VERSION "0.0.1"

NS_ :

BS_:

BU_: TCU BRK ESP MCU RDD GP TMS GW KPD1 RDE FNR ECU KPD2 ATSGO ACU IMU1 IMU2 IMU3 IMU4 IMU5 AGW PMI HDOQS EGOQS OBC EEC CBSW EJRH EJLH EPDLT EPDL2 EPDLR EPDLA TRBDZ ECU1 CLST LC510 EGDL JS SMB KPAC ACCU Audio TGU RDRR RDLH RDRH AVM CHMSL CTC SMK MC3D EVC MCU2
VAL_TABLE_ Bool 3 "N/A" 2 "Error" 1 "True" 0 "False" ;
VAL_TABLE_ PwrDnCmd 3 "N/A" 2 "Emergency Power-Down" 1 "Normal Power-Down" 0 "Not request" ;
VAL_TABLE_ OffOn 3 "N/A" 2 "Error" 1 "On" 0 "Off" ;
VAL_TABLE_ NoneOffOn 3 "N/A" 2 "On" 1 "Off" 0 "None" ;
VAL_TABLE_ MachineStatus 3 "N/A" 2 "Key off charging" 1 "Key on" 0 "Key off" ;
VAL_TABLE_ ChargingStatus 5 "EVSE Signal Warning" 4 "AC Voltage Below Normal" 3 "AC Voltage Above Normal" 2 "Charging Gun Warning" 1 "Charging Port Warning" 0 "Charging" ;
VAL_TABLE_ WrnLamp 3 "Slow Blinking" 2 "Blinking" 1 "On" 0 "Off" ;
VAL_TABLE_ WrnLampTxt 15 "Slow Blinking text4" 14 "Blinking text4" 13 "On text4" 12 "N/A" 11 "Slow Blinking text2" 10 "Blinking text2" 9 "On text2" 8 "N/A" 7 "Slow Blinking text3" 6 "Blinking text3" 5 "On text3" 4 "N/A" 3 "Slow Blinking text1" 2 "Blinking text1" 1 "On text1" 0 "Off" ;
VAL_TABLE_ AntDetect 2 "Shorted" 1 "Removal" 0 "Normal" ;
VAL_TABLE_ TrvModeCr 3 "N/A" 2 "Auto Speed" 1 "High Speed" 0 "Low Speed" ;
VAL_TABLE_ WrkMode 3 "Reserved" 2 "Two Way" 1 "Breaker" 0 "Not Defined" ;
VAL_TABLE_ TwoWayOpt 3 "Not Defined" 2 "Option Pedal" 1 "Joystick Thumb Wheel" 0 "N/A" ;
VAL_TABLE_ GpsSt 3 "3D" 2 "2D" 1 "No Fix" 0 "Unknown" ;
VAL_TABLE_ SmkFobReg 3 "Fail2" 2 "Fail1" 1 "Success" 0 "Normal" ;
VAL_TABLE_ SmkFobDet 1 "Detect Request" 0 "Default" ;
VAL_TABLE_ SmkFobIdReq 1 "Request" 0 "Default" ;
VAL_TABLE_ CmdOnOff 3 "N/A" 2 "Off" 1 "On" 0 "No Action" ;
VAL_TABLE_ EgStartCmd 3 "Key On" 2 "Engine Off" 1 "Engine On" 0 "No Action" ;
VAL_TABLE_ ColdStart 8 "Test of Grid Heater Voltage" 7 "Normal Blinking" 6 "Slow Blinking" 5 "Fault while Pre-Heating" 4 "Parking Brake for Pre-Heating" 3 "No Foot on the Pdedal for Pre-Heating" 2 "Gear Neutral for Pre-Heating" 1 "Trsm Pre-Heating" 0 "OFF" ;
VAL_TABLE_ FuelBlock 1 "Fuel Blocked" 0 "Fuel Released" ;
VAL_TABLE_ LampSt 3 "N/A" 2 "Blinking" 1 "On" 0 "Off" ;
VAL_TABLE_ WrnHigh 3 "Not Available" 2 "Reserved" 1 "Above Operation Range" 0 "Normal" ;
VAL_TABLE_ LampBitSt 4 "Blinking" 1 "On" 0 "Off" ;
VAL_TABLE_ WrnLow 3 "Not Available" 2 "Reserved" 1 "Below Operation Range" 0 "Normal" ;
VAL_TABLE_ Wrn 3 "Not Available" 2 "Reserved" 1 "Warning" 0 "Normal" ;
VAL_TABLE_ EdcOprSt 2 "Diagnostic Test" 1 "Afterrun Drive" 0 "Normal Operation" ;
VAL_TABLE_ PtoSt 31 "N/A" 19 "PTO set speed memory 2" 18 "PTO set speed memory 1" 17 "Preprogrammed set speed 8" 16 "Preprogrammed set speed 7" 15 "Preprogrammed set speed 6" 14 "Preprogrammed set speed 5" 13 "Preprogrammed set speed 4" 12 "Preprogrammed set speed 3" 11 "Preprogrammed set speed 2" 10 "Preprogrammed set speed 1" 9 "Accelerator Override" 8 "Accelerate" 7 "Resume" 6 "Decelerate/Coast" 5 "Set" 4 "Remote Standby" 3 "Standby" 2 "Remote Hold" 1 "Hold" 0 "Off/Disabled" ;
VAL_TABLE_ DpfActRegenSt 3 "N/A" 2 "Regeneration needed" 1 "Active" 0 "Not active" ;
VAL_TABLE_ DpfActRegenIhbSw 3 "N/A" 1 "Inhibited" 0 "Not inhibited" ;
VAL_TABLE_ AtDefPpt 15 "N/A" 14 "Error" 13 "Not able to determine" 3 "Diesel exhaust fluid is proper mixture" 2 "Fluid is diesel" 1 "Urea concentration too low" 0 "Urea concentration too high" ;
VAL_TABLE_ AtSelCatalRedOprIndAct 7 "N/A" 4 "Blinking" 1 "On" 0 "Off" ;
VAL_TABLE_ AtGasSsHtCont 3 "Heater off" 2 "Preheat 1" 1 "Preheat 2" 0 "Automatic" ;
VAL_TABLE_ EgOvrContMd 3 "Speed/torque limit control" 2 "Torque control" 1 "Speed control" 0 "Override disabled" ;
VAL_TABLE_ PRI 3 "Low" 2 "Medium" 1 "High" 0 "Highest" ;
VAL_TABLE_ TractionCont 4 "Auto" 3 "High" 2 "Medium" 1 "Low" 0 "Off" ;
VAL_TABLE_ PowMd 3 "N/A" 2 "PWR" 1 "STD" 0 "ECO" ;
VAL_TABLE_ MaxSpd 5 "Speed 5" 4 "Speed 4" 3 "Speed 3" 2 "Speed 2" 1 "Speed 1" 0 "Neutral" ;
VAL_TABLE_ RpmReqMd 3 "None" 1 "Limphome" 0 "Autoidle" ;
VAL_TABLE_ NFR 3 "TCU requires N position" 2 "Position_R" 1 "Position_F" 0 "Position_N" ;
VAL_TABLE_ FNR 3 "N/A" 2 "R" 1 "N" 0 "F" ;
VAL_TABLE_ GrSt 7 "Limp Home" 6 "Gear 6" 5 "Gear 5" 4 "Gear 4" 3 "Gear 3" 2 "Gear 2" 1 "Gear 1" 0 "Neutral" ;
VAL_TABLE_ OpMd 6 "TCU Idle" 5 "TCU Key Off" 4 "TCU_Shutdown" 3 "Transmission_Shutdown" 2 "Limp_Home" 1 "Substitute_Clutch_Control" 0 "Normal" ;
VAL_TABLE_ MchKeyOnSt 3 "Not defined" 2 "Key off charging" 1 "Key on" 0 "Key off" ;
VAL_TABLE_ ChrgSt 5 "EVSE Signal Warning" 4 "AC Voltage Below Normal" 3 "AC Voltage Above Normal" 2 "Charging Gun Warning" 1 "Charging Port Warning" 0 "Charging" ;
VAL_TABLE_ TrvMdCrw 3 "N/A" 2 "Auto Speed" 1 "High Speed" 0 "Low Speed" ;
VAL_TABLE_ IsoBhl 2 "BHL" 1 "ISO" 0 "OFF" ;
VAL_TABLE_ TrvMdWhl 3 "Not Defined" 2 "3" 1 "2" 0 "True" ;
VAL_TABLE_ HhMntLgc 3 ">4000m" 2 "<=4000m" 1 "<=3000m" 0 "OFF" ;
VAL_TABLE_ BrakerAct 3 "N/A" 2 "Forced Stop" 1 "Running" 0 "Stop" ;
VAL_TABLE_ FaultCnt 3 "N/A" 2 "FaultOc2" 1 "FaultOc1" 0 "None" ;
VAL_TABLE_ TrvMdWld 3 "Not Defined" 2 "Auto Speed 2" 1 "Auto Speed 1" 0 "Manual" ;
VAL_TABLE_ HstMdWld 3 "Not Defined" 2 "Slip" 1 "Auto" 0 "Max" ;
VAL_TABLE_ OprPowMd 4 "Power+" 3 "AutoIdle" 2 "Economy" 1 "Standard" 0 "Power" ;
VAL_TABLE_ OprMd 1 "Digging" 0 "Normal" ;
VAL_TABLE_ WhlDrvMd 3 "AlignComplete" 2 "RearAlignReq" 1 "FrontAlignReq" 0 "Off" ;
VAL_TABLE_ OffOnCnd 3 "Condition Yellow" 2 "Condition Green" 1 "On" 0 "Off" ;
VAL_TABLE_ VhcStSymb 3 "Yellow" 2 "Green" 1 "Grey" 0 "Off" ;
VAL_TABLE_ DAC 5 "Suspend auto" 4 "Interlock" 3 "Auto" 2 "Manual" 1 "Stand By" 0 "Not Ready" ;
VAL_TABLE_ Chmsl 6 "Object Sensing (Fast Flashing)" 5 "Swing Left" 4 "Swing Right" 3 "Working Status (Flashing)" 2 "Standby Working (Continuous)" 1 "Brake On" 0 "Off" ;
VAL_TABLE_ MchCond 3 "Standstill Condition" 2 "Error" 1 "Working Condition" 0 "Idle Condition" ;
VAL_TABLE_ PilotCutOffSt 3 "Not Available" 2 "Auto Lock" 1 "Manual Lock " 0 "Unlock " ;
VAL_TABLE_ BodySt 3 "Not Defined" 2 "Float" 1 "Hold" 0 "Off" ;
VAL_TABLE_ EcoSymbol 3 "White" 2 "Red" 1 "Yellow" 0 "Green" ;
VAL_TABLE_ Progress 3 "N/A" 2 "Complete" 1 "In Progress" 0 "None" ;
VAL_TABLE_ Progress2 1 "Complete" 0 "In Progress" ;
VAL_TABLE_ ManAuto 3 "N/A" 2 "Error" 1 "Auto" 0 "Manual" ;
VAL_TABLE_ AdminSet 4 "Entertainment Restrict" 2 "Attachment" 1 "Ignition Lock" 0 "None" ;
VAL_TABLE_ Uptime 3 "N/A" 2 "5 min" 1 "1 min" 0 "Always" ;
VAL_TABLE_ HydElec 1 "Electronic" 0 "Hydraulic" ;
VAL_TABLE_ JoyPdl 3 "N/A" 2 "Option Pedal" 1 "Joystick Thumb Wheel" 0 "N/A" ;
VAL_TABLE_ ThmbWhl 3 "N/A" 2 "Fast" 1 "Normal" 0 "Smooth" ;
VAL_TABLE_ MultiFunc 7 "Not Defined" 6 "Not Defined" 5 "Auto Breaker" 4 "Audio Mute" 3 "Ram Lock  Status Change" 2 "Camera View Mode Change" 1 "Smart Boom Cut" 0 "Wiper On" ;
VAL_TABLE_ EmsCtrl 128 "N/A" 5 "NR4" 4 "StageV" 3 "Tier4F" 2 "Tier4i" 1 "Tier3" 0 "Tier2" ;
VAL_TABLE_ MchGen 224 "D" 133 "G" 132 "SD" 131 "S" 130 "K" 129 "H" 128 "DL" 108 "AGK" 96 "JD" 5 "W" 4 "B" 3 "C" 2 "V" 1 "U" 0 "DX" ;
VAL_TABLE_ MchType 14 "ADT" 13 "Road Builder" 12 "Compact Track Loader" 11 "Drill Rig" 10 "Material Handler Wheel" 9 "Material Handler" 8 "Dozer" 7 "Loader" 6 "Wheel" 5 "Mountain" 4 "Zero Tail" 3 "Reduced Tail" 2 "LogLoader" 1 "Long Crawler" 0 "Crawler" ;
VAL_TABLE_ ModelYearVer 5 "5th" 4 "4th" 3 "3rd" 2 "2nd" 1 "1st" 0 "Original" ;
VAL_TABLE_ EgMaker 8 "Daedong" 7 "Yanmar" 5 "Isuzu" 4 "Perkins" 3 "Cummins" 2 "Scania" 1 "Doosan" 0 "None" ;
VAL_TABLE_ EcuMaker 12 "Perkins_2506J_Unified" 11 "Weifu" 10 "Bosch (EDC7)" 9 "Woodward" 8 "Perkins_1204J" 7 "Hitachi" 6 "Bosch (G2)" 5 "Isuzu" 4 "Perkins_2506J" 3 "Cummins" 2 "Scania" 1 "Bosch (DL06 / DL08)" 0 "None" ;
VAL_TABLE_ PmpType 4 "LS" 3 "VBO" 2 "Open Center" 1 "Posicon" 0 "Negacon" ;
VAL_TABLE_ MechElec 1 "Electric" 0 "Mechanic" ;
VAL_TABLE_ McvCtrlType 2 "FEH" 1 "VBO" 0 "Mechanic" ;
VAL_TABLE_ TcuType 3 "HDT Level1" 2 "CVT" 1 "HST" 0 "HDT" ;
VAL_TABLE_ Region 4 "US" 3 "Emerging" 2 "Advanced" 1 "China" 0 "Korea" ;
VAL_TABLE_ Btn 3 "N/A" 2 "Propotional" 1 "Toggle" 0 "Push" ;
VAL_TABLE_ Active 3 "N/A" 2 "Error" 1 "Active" 0 "Deactive" ;
VAL_TABLE_ GYR 2 "Red" 1 "Yellow" 0 "Green" ;
VAL_TABLE_ WghSt 5 "Confirm(Truck Tip-off)" 4 "Estimate(Truck tip-off)" 3 "Complete" 2 "Confirm" 1 "Estimate" 0 "Ready" ;
VAL_TABLE_ WghCntSt 3 "Not Defined" 2 "Return" 1 "Cancel" 0 "Off" ;
VAL_TABLE_ Srage 15 "Error" 14 "Success" 13 "Last Stage (Confirm)" 12 "Stage 12" 11 "Stage 11" 10 "Stage 10" 9 "Stage 9" 8 "Stage 8" 7 "Stage 7" 6 "Stage 6" 5 "Stage 5" 4 "Stage 4" 3 "Stage 3" 2 "Stage 2" 1 "Stage 1" 0 "Reserved" ;
VAL_TABLE_ GradeOffsetSw 15 "Not Available" 14 "Error" 2 "Decrement button pressed" 1 "Increment button pressed" 0 "No button pressed" ;
VAL_TABLE_ BladeAutoMd 15 "Not Available" 14 "Error" 4 "Auto Not Allowed" 3 "Service Mode" 2 "Suspend Auto" 0 "Auto Allowed" ;
VAL_TABLE_ TmsStInfo01 1 "??" 0 "????" ;
VAL_TABLE_ VwMd 15 "Not Available" 5 "Boom" 4 "3D" 3 "Top+Rear" 2 "Right" 1 "Rear" 0 "Top" ;
VAL_TABLE_ PriMd 1 "Priority Mode" 0 "Normal Mode" ;
VAL_TABLE_ FactoryType 3 "?? 4" 2 "?? 3" 1 "?? 2" 0 "?? 1" ;
VAL_TABLE_ VhcType1 1 "Crawler" 0 "Wheel" ;
VAL_TABLE_ VhcType2 3 "Not Defined" 2 "LL" 1 "LCR(???)" 0 "LC(??)" ;
VAL_TABLE_ UltsRecognitionDistanceSet 1 "???" 0 "??" ;
VAL_TABLE_ BoomCamOpt 1 "Boom Camera ??" 0 "Boom Camera ???" ;
VAL_TABLE_ OnOffSt 1 "Off" 0 "On" ;
VAL_TABLE_ Opt 1 "?? ??" 0 "?? ??" ;
VAL_TABLE_ DisEnable 1 "Enable" 0 "Disable" ;
VAL_TABLE_ ToleranceCorCmd 3 "?? ?? ??" 2 "?? ?? ??" 1 "?? ?? ?" 0 "?? ?? ?" ;
VAL_TABLE_ ToleranceCorMenuentryCmd 1 "?? ?? ?? ??" 0 "?? ?? ?? ??" ;
VAL_TABLE_ CamPrmtCorCompleteSt 0 "???" ;
VAL_TABLE_ CamPrmtcorCompleteSt 1 "?? ??" ;
VAL_TABLE_ PwrMdSt 3 "Power Mode" 2 "Power + Mode" 1 "Economy Mode" 0 "Standard Mode" ;
VAL_TABLE_ WrkMdSt 3 "Two Way" 2 "Breaker" 1 "Lift" 0 "Dig" ;
VAL_TABLE_ LockSt 1 "Lock" 0 "Unlock " ;
VAL_TABLE_ TractionMdSt 4 "Auto" 3 "C(1)" 2 "B(2)" 1 "A(3)" 0 "Max" ;
VAL_TABLE_ KeyPadPri 1 "Virtual KePad" 0 "KeyPad" ;
VAL_TABLE_ EvMdCmd 3 "N/A" 2 "N/A" 1 "EV Mode" 0 "Normal Mode" ;
VAL_TABLE_ AttType 1 "Two Way" 0 "Breaker" ;
VAL_TABLE_ AlarmSt 5 "Alarm #5" 4 "Alarm #4" 3 "Alarm #3" 2 "Alarm #2" 1 "Alarm #1" 0 "Alarm Off" ;
VAL_TABLE_ MgSoundGudStep 9 "Alarm #9" 8 "Alarm #8" 7 "Alarm #7" 6 "Alarm #6" 5 "Alarm #5" 4 "Alarm #4" 3 "Alarm #3" 2 "Alarm #2" 1 "Alarm #1" 0 "Alarm Off" ;
VAL_TABLE_ OptSetJoyPatternChange 6 "CTL H" 5 "CTL ISO" 4 "SCM" 3 "KOBE" 2 "MHI" 1 "BHL (for CTL Backhoe)" 0 "ISO (for CTL EXC)" ;
VAL_TABLE_ AudioAuxSel 3 "N/A" 2 "Error Indicator" 1 "On" 0 "Off" ;
VAL_TABLE_ ReqCallIndex 10 "10th Index" 9 "9th Index" 8 "8th Index" 7 "7th Index" 6 "6th Index" 5 "5th Index" 4 "4th Index" 3 "3rd Index" 2 "2nd Index" 1 "1st Index" 0 "None" ;
VAL_TABLE_ MainCmd 1 "CAM Button CMD" 0 "No Action CMD" ;
VAL_TABLE_ SubCmd 1 "????? ?? ?" 0 "????? ?? ??" ;
VAL_TABLE_ Dt02GpType 1 "S&T 8inch ???" 0 "S&T 7inch ???" ;
VAL_TABLE_ GspnIdentifier 1 "GSPN" 0 "SPN" ;
VAL_TABLE_ PdlCalb 2 "Max Pushed Cal CMD" 1 "Max Release Cal CMD" 0 "Calibration Ready CMD" ;
VAL_TABLE_ Joystick 3 "Not Defined" 2 "???" 1 "??" 0 "????" ;
VAL_TABLE_ NoInReq 1 "??" 0 "??" ;
VAL_TABLE_ DoorLockSt 3 "Failed" 2 "Unlock " 1 "Lock" 0 "None" ;
VAL_TABLE_ NoneOnOff 3 "Failed" 2 "Off" 1 "On" 0 "None" ;
VAL_TABLE_ VentilationTmp 15 "Failed" ;
VAL_TABLE_ FobRgstFdbk 3 "None" 2 "Detection Complete" 1 "Not Detection" 0 "Default" ;
VAL_TABLE_ FobWarn 3 "ON (Slow Blinking)" 2 "ON (Normal Blinking)" 1 "ON (No Blinking)" 0 "OFF" ;
VAL_TABLE_ KeyStChange 3 "Crank or Engine Running" 2 "Key On" 1 "ACC" 0 "Key Off" ;
VAL_TABLE_ Detect 1 "Detect" 0 "No Detect" ;
VAL_TABLE_ OpenClose 1 "Close" 0 "Open" ;
VAL_TABLE_ RmRunningSt 1 "Remote Running Status" 0 "Normal Status" ;
VAL_TABLE_ Activation 1 "Activation" 0 "No Activation" ;
VAL_TABLE_ JoyEnbsignal 3 "Not Available" 2 "Reserved" 1 "Active" 0 "Inactive" ;
VAL_TABLE_ Errorcode 15 "No Error" 14 "Reserved" 13 "Reserved" 12 "Reserved" 11 "Reserved" 10 "Reserved" 9 "Reserved" 8 "Reserved" 7 "Reserved" 6 "Reserved" 5 "Reserved" 4 "Reserved" 3 "Reserved" 2 "Reserved" 1 "Reserved" 0 "Reserved" ;
VAL_TABLE_ Drtindication 3 "Not Available" 2 "Error indicator" 1 "Reverse" 0 "Forward" ;
VAL_TABLE_ IfconfiguredasPrptA 0 "Always" ;
VAL_TABLE_ StrMdReq 1 "Operating" 0 "Not Operating" ;
VAL_TABLE_ AuxStrDeviceLckout 3 "Not Available" 2 "Reserved" 1 "AUX steering prohibited" 0 "AUX steering allowed" ;
VAL_TABLE_ AutoGudRecvSelandLckout 3 "Reserved" 2 "GPS 2 Steering selected" 1 "GPS Steering selected" 0 "No GPS receiver selected (GPS steering
prohibited)" ;
VAL_TABLE_ TrvlSpdSet 3 "Preset 4" 2 "Preset 3" 1 "Preset 2" 0 "Preset 1" ;
VAL_TABLE_ Spd 10 "Speed 5" 9 "Speed 4.5" 8 "Speed 4" 7 "Speed 3.5" 6 "Speed 3" 5 "Speed 2.5" 4 "Speed 2" 3 "Speed 1.5" 2 "Speed 1" 1 "Speed 0.5" 0 "Speed 0" ;
VAL_TABLE_ Fnr 2 "Reverse" 1 "Neutral" 0 "Forward" ;
VAL_TABLE_ CurPwrMd 3 "Not available" 2 "PWR" 1 "STD" 0 "ECO" ;
VAL_TABLE_ MnAutoMdSt 3 "Reserved" 2 "Auto" 1 "Not Available" 0 "Manual" ;
VAL_TABLE_ MdSt 3 "Reserved" 2 "Enable" 1 "Not Available" 0 "Disable" ;
VAL_TABLE_ OuttakeIntakeMdsel 3 "Reserved" 2 "Intake mode" 1 "Not Available" 0 "Outtake mode" ;
VAL_TABLE_ VhcStSybACOffInd 3 "Blink (Slow Blink)" 2 "Blink (Normal Blink)" 1 "On(No Blinking)" 0 "Off" ;
VAL_TABLE_ OutReq 3 "Not Available" 2 "Error Indicator" 1 "On" 0 "Off" ;
VAL_TABLE_ OutFdbkCur 1 "Not Available" 0 "Error indicator" ;
VAL_TABLE_ ErrorFlag 1 "Error indicator" 0 "None" ;
VAL_TABLE_ NorOpenShort 2 "Short" 1 "Open" 0 "Normal" ;
VAL_TABLE_ ResolutionMd 3 "Don't Care" 2 "Reserved" 1 "High Resolution" 0 "Standard Resolution" ;
VAL_TABLE_ VvSt 15 "N/A" 3 "Float" 2 "Retract" 1 "Extend" 0 "Block" ;
VAL_TABLE_ FailSafeMd 3 "Don't Care" 2 "Reserved" 1 "Extend" 0 "Block" ;
VAL_TABLE_ AvmLanguagePack 24 "Vietnamese" 23 "Greek" 22 "Thai" 21 " Hindi" 20 "Farsi(Persian)" 19 "Arabic(Saudi Arabia)" 18 "Russian" 17 "Polish" 16 " Indonesian" 15 "Turkish" 14 "Japanese" 13 "Danish" 12 "Norwegian(Bokmal)" 11 "Swedish" 10 "Finnish" 9 "Spanish(International)" 8 "Portuguese(Portugal)" 7 "Italian(Italy)" 6 "Dutch(Netherlands)" 5 "German(Germany)" 4 "French(France)" 3 "Chinese (PRC)" 2 "English" 1 "Korean (Default)" 0 "NotUsed" ;
VAL_TABLE_ AvmVw 5 "Boom (Option)" 4 "3D" 3 "Rear + Corner" 2 "Top + Right" 1 "Rear Wide" 0 "Topview" ;
VAL_TABLE_ AvmOutType 7 "Invalid" 6 "Error" 2 "AVM Output Type LVDS" 1 "AVM Output Type NTSC" 0 "Not Used" ;
VAL_TABLE_ AvmDisplayMsg 255 "Invalid" 254 "Error" 63 "Warning_Check_Back&Right&Left" 62 "Warning_Check_Front&Right&Left" 2 "InCameraCalibarionMode" 1 "No Message" 0 "Not Used" ;
VAL_TABLE_ AvmTonSize 15 "Invalid" 14 "Error" 5 "30T Crawler" 4 "21T Wheel" 3 "14T Wheel" 2 "5T Wheel" 1 "5T Crawler" 0 "Not Used" ;
VAL_TABLE_ AvmUltraBz 15 "Invalid" 14 "Error" 7 "Left / Right / Rear Activation" 6 "Right / Rear Activation" 5 "Left / Right Activation" 4 "Left / Rear Activation" 3 "Rear Activation" 2 "Righr Activation" 1 "Left Activation" 0 "Ultrasonic All Off" ;
VAL_TABLE_ AvmSt 31 "Invalid" 30 "Error" 3 "AVM Fail" 2 "AVM Normal (IGN On)" 1 "AVM Not Ready (IGN Off)" 0 "Not Used" ;
VAL_TABLE_ AvmWarnGud 7 "Invalid" 6 "Error" 2 "AVM Warning Guide Line On" 1 "AVM Warning Guide Line Off" 0 "Not Used" ;
VAL_TABLE_ UltsSig 15 "Invalid" 14 "Error" 5 "Noise Error" 4 "Fault" 3 "Level 3" 2 "Level 2" 1 "Level 1" 0 "Off" ;
VAL_TABLE_ Working 1 "Working" 0 "Not Working" ;
VAL_TABLE_ HtPadSt 1 "On Board Charger" 0 "Off" ;
VAL_TABLE_ ChgSt 7 "Not Available" 6 "Charger Error" 5 "Reserved" 4 "Pause" 3 "Complete" 2 "Failure" 1 "Charging" 0 "Standby" ;
VAL_TABLE_ BmsChgSourceType 3 "Not Available" 2 "Quick charger" 1 "On Board Charger" 0 "None" ;
VAL_TABLE_ ScrtyCmd 3 "Not Available" 2 "Engine Lock" 1 "RPM Limit" 0 "Normal" ;
VAL_TABLE_ GpsAntSt 3 "N/A" 2 "Shorten" 1 "Removed" 0 "Normal" ;
VAL_TABLE_ KeyType 4 "Remote" 3 "Keyless" 2 "Digital Key" 1 "Fob" 0 "None" ;
VAL_TABLE_ Type 7 "N/A" 3 "5G" 2 "4G" 1 "3G" 0 "2G" ;
VAL_TABLE_ WarnPopHyhOilQual 2 "?? 2??" 1 "?? 1??" 0 "Off" ;
VAL_TABLE_ WarnPopEgOilQual 2 "?? 2??" 1 "?? 1??" 0 "Off" ;

BO_ 3221225472 VECTOR__INDEPENDENT_SIG_MSG: 0 Vector__XXX
 SG_ GyroSnsrX : 0|16@1+ (0.0152671755725191,0) [0|1000.53435114504] "" Vector__XXX
 SG_ SwgRdctVib : 0|16@1+ (7.7E-005,0) [0|5.046195] "" Vector__XXX
 SG_ SPN : 0|19@1+ (1,0) [0|0] "" Vector__XXX
 SG_ KnmtVcstyofEgOil : 0|16@1+ (0.00778149,0) [0|500] "" Vector__XXX
 SG_ KnmtVcstyofHyhOil : 0|16@1+ (0.00778149,0) [0|500] "" Vector__XXX
 SG_ LwThKnmtVcstyofEgOil : 0|16@1+ (0.00778149,0) [0|500] "" Vector__XXX
 SG_ UpThKnmtVcstyofEgOil : 0|16@1+ (0.00778149,0) [0|500] "" Vector__XXX
 SG_ LwThDielecCstofEgOil : 0|16@1+ (0.0001220703125,0) [0|7.844] "" Vector__XXX
 SG_ UpThDielecCstofEgOil : 0|16@1+ (0.0001220703125,0) [0|7.844] "" Vector__XXX
 SG_ LwThKnmtVcstyofHyhOil : 0|16@1+ (0.00778149,0) [0|500] "" Vector__XXX
 SG_ UpThKnmtVcstyofHyhOil : 0|16@1+ (0.00778149,0) [0|500] "" Vector__XXX
 SG_ LwThDielecCstofHyhOil : 0|16@1+ (0.0001220703125,0) [0|7.844] "" Vector__XXX
 SG_ UpThDielecCstofHyhOil : 0|16@1+ (0.0001220703125,0) [0|7.844] "" Vector__XXX
 SG_ RqstdPGN : 0|24@1+ (1,0) [0|0] "" Vector__XXX
 SG_ AddressAcknowledged : 0|8@1+ (1,0) [0|0] "" Vector__XXX
 SG_ GroupFunctionValue : 0|8@1+ (1,0) [0|0] "" Vector__XXX
 SG_ ControlByte : 0|8@1+ (1,0) [0|0] "" Vector__XXX
 SG_ WarnPopHyhOilQual : 0|3@1+ (1,0) [0|7] "" Vector__XXX
 SG_ WarnPopEgOilQual : 0|3@1+ (1,0) [0|7] "" Vector__XXX
 SG_ SwVer : 0|72@1+ (1,0) [0|255] "ASCII" Vector__XXX
 SG_ KnlVer : 0|72@1+ (1,0) [0|255] "ASCII" Vector__XXX
 SG_ ProdDate : 0|72@1+ (1,0) [0|255] "ASCII" Vector__XXX
 SG_ TGUId : 0|160@1+ (1,0) [0|255] "ASCII" Vector__XXX
 SG_ TypeCd : 0|48@1+ (1,0) [0|255] "ASCII" Vector__XXX
 SG_ SwRdctFeature2ndR : 0|16@1+ (0.01,0) [0|655.35] "" Vector__XXX
 SG_ SwRdctFeature2ndL : 0|16@1+ (0.01,0) [0|655.35] "" Vector__XXX
 SG_ SwRdctFeature1stR : 0|16@1+ (0.01,0) [0|655.35] "" Vector__XXX
 SG_ SwRdctFeature1stL : 0|16@1+ (0.01,0) [0|655.35] "" Vector__XXX
 SG_ SwRdctThreshEnvTSA : 0|8@1+ (0.1,0) [0|25.5] "" Vector__XXX
 SG_ SwRdctUnitStat2ndR : 0|4@1+ (1,0) [0|15] "" Vector__XXX
 SG_ SwRdctUnitStat2ndL : 0|4@1+ (1,0) [0|15] "" Vector__XXX
 SG_ SwRdctUnitStat1stR : 0|4@1+ (1,0) [0|15] "" Vector__XXX
 SG_ SwRdctUnitStat1stL : 0|4@1+ (1,0) [0|15] "" Vector__XXX
 SG_ SwRdctThreshDTSA : 0|8@1+ (0.1,0) [0|25.5] "" Vector__XXX
 SG_ SwgRdctStatus : 0|2@1+ (1,0) [0|3] "" Vector__XXX
 SG_ SwgAngle : 0|4@1+ (24,0) [0|360] "" Vector__XXX

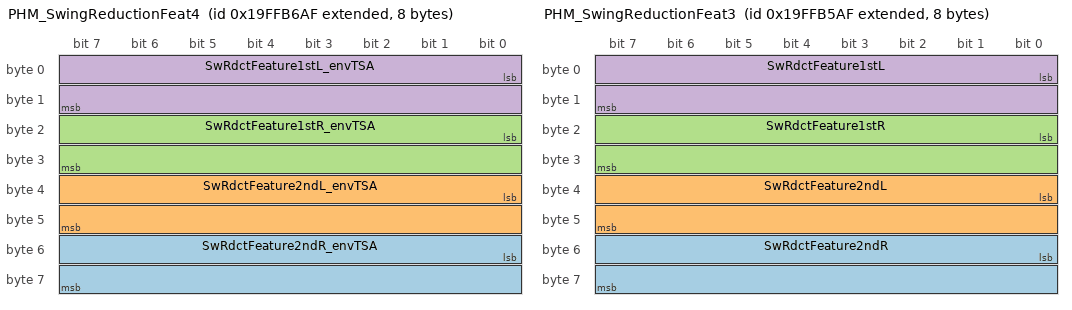
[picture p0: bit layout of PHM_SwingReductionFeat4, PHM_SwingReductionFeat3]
BO_ 2583672495 PHM_SwingReductionFeat4: 8 Vector__XXX
 SG_ SwRdctFeature2ndR_envTSA : 48|16@1+ (0.01,0) [0|655.35] "" Vector__XXX
 SG_ SwRdctFeature2ndL_envTSA : 32|16@1+ (0.01,0) [0|655.35] "" Vector__XXX
 SG_ SwRdctFeature1stR_envTSA : 16|16@1+ (0.01,0) [0|655.35] "" Vector__XXX
 SG_ SwRdctFeature1stL_envTSA : 0|16@1+ (0.01,0) [0|655.35] "" Vector__XXX

BO_ 2583672239 PHM_SwingReductionFeat3: 8 Vector__XXX
 SG_ SwRdctFeature2ndR : 48|16@1+ (0.01,0) [0|655.35] "" Vector__XXX
 SG_ SwRdctFeature2ndL : 32|16@1+ (0.01,0) [0|655.35] "" Vector__XXX
 SG_ SwRdctFeature1stR : 16|16@1+ (0.01,0) [0|655.35] "" Vector__XXX
 SG_ SwRdctFeature1stL : 0|16@1+ (0.01,0) [0|655.35] "" Vector__XXX

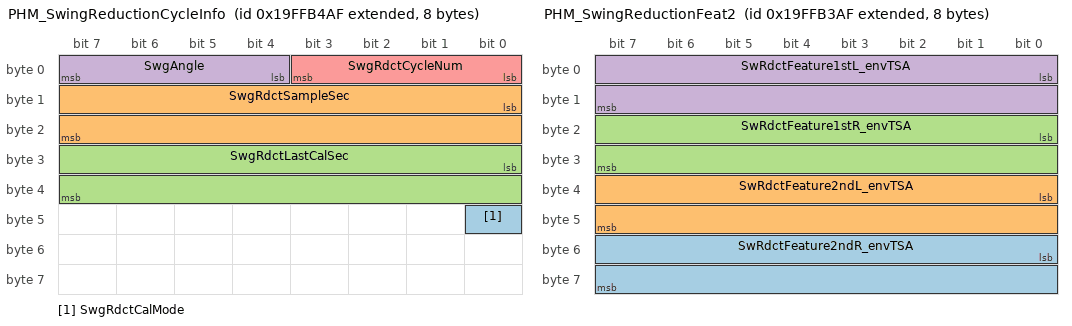
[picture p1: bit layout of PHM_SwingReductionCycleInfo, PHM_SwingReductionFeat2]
BO_ 2583671983 PHM_SwingReductionCycleInfo: 8 Vector__XXX
 SG_ SwgRdctCalMode : 40|1@1+ (1,0) [0|1] "" Vector__XXX
 SG_ SwgRdctSampleSec : 8|16@1+ (1,0) [0|65535] "" Vector__XXX
 SG_ SwgRdctLastCalSec : 24|16@1+ (1,0) [0|65535] "" Vector__XXX
 SG_ SwgAngle : 4|4@1+ (24,0) [0|360] "" Vector__XXX
 SG_ SwgRdctCycleNum : 0|4@1+ (1,0) [0|15] "" Vector__XXX

BO_ 2583671727 PHM_SwingReductionFeat2: 8 Vector__XXX
 SG_ SwRdctFeature2ndR_envTSA : 48|16@1+ (0.01,0) [0|655.35] "" Vector__XXX
 SG_ SwRdctFeature2ndL_envTSA : 32|16@1+ (0.01,0) [0|655.35] "" Vector__XXX
 SG_ SwRdctFeature1stR_envTSA : 16|16@1+ (0.01,0) [0|655.35] "" Vector__XXX
 SG_ SwRdctFeature1stL_envTSA : 0|16@1+ (0.01,0) [0|655.35] "" Vector__XXX

BO_ 2566834688 ECU_DM1_: 25 Vector__XXX
 SG_ FMI_6 : 192|5@1+ (1,0) [0|0] "" Vector__XXX
 SG_ FMI_5 : 160|5@1+ (1,0) [0|0] "" Vector__XXX
 SG_ FMI_4 : 128|5@1+ (1,0) [0|0] "" Vector__XXX
 SG_ FMI_3 : 96|5@1+ (1,0) [0|0] "" Vector__XXX
 SG_ FMI_2 : 64|5@1+ (1,0) [0|0] "" Vector__XXX
 SG_ FMI_1 : 32|5@1+ (1,0) [0|0] "" Vector__XXX
 SG_ MSB3bitofSPN_6 : 197|3@1+ (1,0) [0|0] "" Vector__XXX
 SG_ MSB3bitofSPN_5 : 165|3@1+ (1,0) [0|0] "" Vector__XXX
 SG_ MSB3bitofSPN_4 : 133|3@1+ (1,0) [0|0] "" Vector__XXX
 SG_ MSB3bitofSPN_3 : 101|3@1+ (1,0) [0|0] "" Vector__XXX
 SG_ MSB3bitofSPN_2 : 69|3@1+ (1,0) [0|0] "" Vector__XXX
 SG_ LSbyteSPN_6 : 176|16@1+ (1,0) [0|0] "" Vector__XXX
 SG_ LSbyteSPN_5 : 144|16@1+ (1,0) [0|0] "" Vector__XXX
 SG_ LSbyteSPN_4 : 112|16@1+ (1,0) [0|0] "" Vector__XXX
 SG_ LSbyteSPN_3 : 80|16@1+ (1,0) [0|0] "" Vector__XXX
 SG_ LSbyteSPN_2 : 48|16@1+ (1,0) [0|0] "" Vector__XXX
 SG_ LSbyteSPN_1 : 16|16@1+ (1,0) [0|0] "" Vector__XXX
 SG_ MSB3bitofSPN_1 : 37|3@1+ (1,0) [0|0] "" Vector__XXX

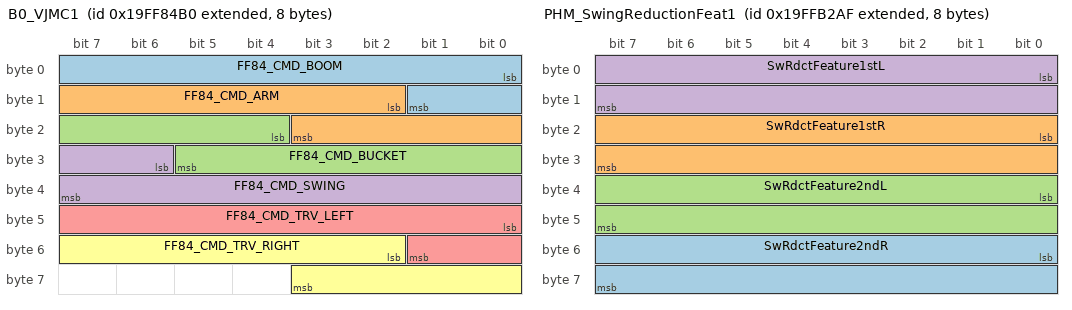
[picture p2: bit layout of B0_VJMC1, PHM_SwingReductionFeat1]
BO_ 2583659696 B0_VJMC1: 8 Vector__XXX
 SG_ FF84_CMD_BOOM : 0|10@1+ (4,-1000) [-1000|3092] "" Vector__XXX
 SG_ FF84_CMD_ARM : 10|10@1+ (4,-1000) [-1000|3092] "" Vector__XXX
 SG_ FF84_CMD_BUCKET : 20|10@1+ (4,-1000) [-1000|3092] "" Vector__XXX
 SG_ FF84_CMD_SWING : 30|10@1+ (4,-1000) [-1000|3092] "" Vector__XXX
 SG_ FF84_CMD_TRV_LEFT : 40|10@1+ (4,-1000) [-1000|3092] "" Vector__XXX
 SG_ FF84_CMD_TRV_RIGHT : 50|10@1+ (4,-1000) [-1000|3092] "" Vector__XXX

BO_ 2583671471 PHM_SwingReductionFeat1: 8 Vector__XXX
 SG_ SwRdctFeature2ndR : 48|16@1+ (0.01,0) [0|655.35] "" Vector__XXX
 SG_ SwRdctFeature1stR : 16|16@1+ (0.01,0) [0|655.35] "" Vector__XXX
 SG_ SwRdctFeature2ndL : 32|16@1+ (0.01,0) [0|655.35] "" Vector__XXX
 SG_ SwRdctFeature1stL : 0|16@1+ (0.01,0) [0|655.35] "" Vector__XXX

BO_ 2583643978 TGU_APIToken: 150 Vector__XXX

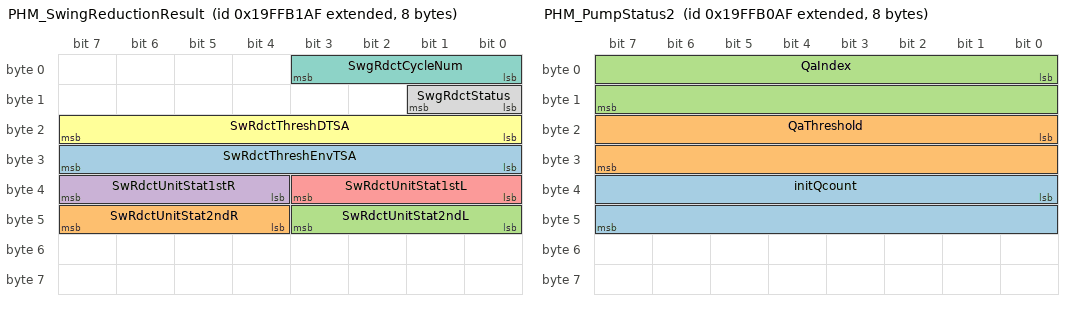
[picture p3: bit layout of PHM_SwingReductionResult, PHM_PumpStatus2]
BO_ 2583671215 PHM_SwingReductionResult: 8 Vector__XXX
 SG_ SwRdctThreshEnvTSA : 24|8@1+ (0.1,0) [0|25.5] "" Vector__XXX
 SG_ SwRdctUnitStat2ndR : 44|4@1+ (1,0) [0|15] "" Vector__XXX
 SG_ SwRdctUnitStat2ndL : 40|4@1+ (1,0) [0|15] "" Vector__XXX
 SG_ SwRdctUnitStat1stR : 36|4@1+ (1,0) [0|15] "" Vector__XXX
 SG_ SwRdctUnitStat1stL : 32|4@1+ (1,0) [0|15] "" Vector__XXX
 SG_ SwRdctThreshDTSA : 16|8@1+ (0.1,0) [0|25.5] "" Vector__XXX
 SG_ SwgRdctCycleNum : 0|4@1+ (1,0) [0|15] "" Vector__XXX
 SG_ SwgRdctStatus : 8|2@1+ (1,0) [0|3] "" Vector__XXX

BO_ 2583670959 PHM_PumpStatus2: 8 Vector__XXX
 SG_ initQcount : 32|16@1+ (1,0) [0|65535] "" Vector__XXX
 SG_ QaThreshold : 16|16@1+ (0.01,0) [0|655.35] "lpm" Vector__XXX
 SG_ QaIndex : 0|16@1+ (0.01,0) [0|655.35] "lpm" Vector__XXX

BO_ 2565517089 EPOS_REQ_PHM: 8 Vector__XXX
 SG_ PGN : 0|24@1+ (1,0) [0|16777215] "" Vector__XXX

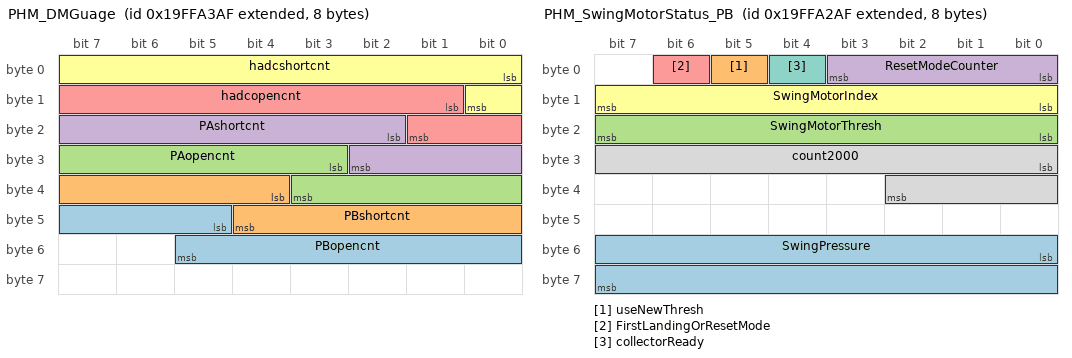
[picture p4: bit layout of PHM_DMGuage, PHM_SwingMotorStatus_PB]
BO_ 2583667631 PHM_DMGuage: 8 Vector__XXX
 SG_ PBopencnt : 45|9@1+ (1,0) [0|511] "" Vector__XXX
 SG_ PBshortcnt : 36|9@1+ (1,0) [0|511] "" Vector__XXX
 SG_ PAopencnt : 27|9@1+ (1,0) [0|511] "" Vector__XXX
 SG_ PAshortcnt : 18|9@1+ (1,0) [0|511] "" Vector__XXX
 SG_ hadcopencnt : 9|9@1+ (1,0) [0|511] "" Vector__XXX
 SG_ hadcshortcnt : 0|9@1+ (1,0) [0|511] "" Vector__XXX

BO_ 2566834863 PHM_Premium_DM1: 25 Vector__XXX
 SG_ FMI_6 : 192|5@1+ (1,0) [0|0] "" Vector__XXX
 SG_ FMI_5 : 160|5@1+ (1,0) [0|0] "" Vector__XXX
 SG_ FMI_4 : 128|5@1+ (1,0) [0|0] "" Vector__XXX
 SG_ FMI_3 : 96|5@1+ (1,0) [0|0] "" Vector__XXX
 SG_ FMI_2 : 64|5@1+ (1,0) [0|0] "" Vector__XXX
 SG_ FMI_1 : 32|5@1+ (1,0) [0|0] "" Vector__XXX
 SG_ MSB3bitofSPN_6 : 197|3@1+ (1,0) [0|0] "" Vector__XXX
 SG_ MSB3bitofSPN_5 : 165|3@1+ (1,0) [0|0] "" Vector__XXX
 SG_ MSB3bitofSPN_4 : 133|3@1+ (1,0) [0|0] "" Vector__XXX
 SG_ MSB3bitofSPN_3 : 101|3@1+ (1,0) [0|0] "" Vector__XXX
 SG_ MSB3bitofSPN_2 : 69|3@1+ (1,0) [0|0] "" Vector__XXX
 SG_ LSbyteSPN_6 : 176|16@1+ (1,0) [0|0] "" Vector__XXX
 SG_ LSbyteSPN_5 : 144|16@1+ (1,0) [0|0] "" Vector__XXX
 SG_ LSbyteSPN_4 : 112|16@1+ (1,0) [0|0] "" Vector__XXX
 SG_ LSbyteSPN_3 : 80|16@1+ (1,0) [0|0] "" Vector__XXX
 SG_ LSbyteSPN_2 : 48|16@1+ (1,0) [0|0] "" Vector__XXX
 SG_ LSbyteSPN_1 : 16|16@1+ (1,0) [0|0] "" Vector__XXX
 SG_ MSB3bitofSPN_1 : 37|3@1+ (1,0) [0|0] "" Vector__XXX

BO_ 2583667375 PHM_SwingMotorStatus_PB: 8 Vector__XXX
 SG_ SwingPressure : 48|16@1+ (0.01,0) [0|655.35] "" Vector__XXX
 SG_ useNewThresh : 5|1@1+ (1,0) [0|1] "" Vector__XXX
 SG_ SwingMotorThresh : 16|8@1+ (0.0625,0) [0|15.9375] "" Vector__XXX
 SG_ ResetModeCounter : 0|4@1+ (1,0) [0|15] "" Vector__XXX
 SG_ FirstLandingOrResetMode : 6|1@1+ (1,0) [0|1] "" Vector__XXX
 SG_ SwingMotorIndex : 8|8@1+ (0.0625,0) [0|15.9375] "" Vector__XXX
 SG_ collectorReady : 4|1@1+ (1,0) [0|1] "" Vector__XXX
 SG_ count2000 : 24|11@1+ (1,0) [0|2047] "count" Vector__XXX

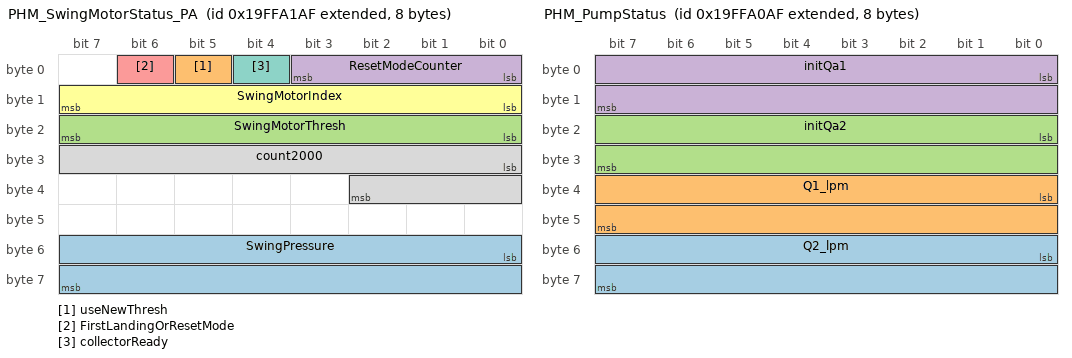
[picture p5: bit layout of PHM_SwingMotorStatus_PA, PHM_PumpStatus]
BO_ 2583667119 PHM_SwingMotorStatus_PA: 8 Vector__XXX
 SG_ SwingPressure : 48|16@1+ (0.01,0) [0|655.35] "" Vector__XXX
 SG_ useNewThresh : 5|1@1+ (1,0) [0|1] "" Vector__XXX
 SG_ SwingMotorThresh : 16|8@1+ (0.0625,0) [0|15.9375] "" Vector__XXX
 SG_ ResetModeCounter : 0|4@1+ (1,0) [0|15] "" Vector__XXX
 SG_ FirstLandingOrResetMode : 6|1@1+ (1,0) [0|1] "" Vector__XXX
 SG_ SwingMotorIndex : 8|8@1+ (0.0625,0) [0|15.9375] "" Vector__XXX
 SG_ collectorReady : 4|1@1+ (1,0) [0|1] "" Vector__XXX
 SG_ count2000 : 24|11@1+ (1,0) [0|2047] "count" Vector__XXX

BO_ 2583666863 PHM_PumpStatus: 8 Vector__XXX
 SG_ Q2_lpm : 48|16@1+ (0.01,0) [0|655.35] "" Vector__XXX
 SG_ Q1_lpm : 32|16@1+ (0.01,0) [0|655.35] "" Vector__XXX
 SG_ initQa2 : 16|16@1+ (0.01,0) [0|655.35] "" Vector__XXX
 SG_ initQa1 : 0|16@1+ (0.01,0) [0|655.35] "" Vector__XXX

BO_ 2583691183 PHM_SRGKnock: 4 Vector__XXX
 SG_ SwingGearSensor : 0|32@1+ (1,0) [0|4294967295] "" Vector__XXX

BO_ 2566838561 MCU_ADOS: 8 Vector__XXX
 SG_ RemoteReGen : 10|2@1+ (1,0) [0|0] "" Vector__XXX

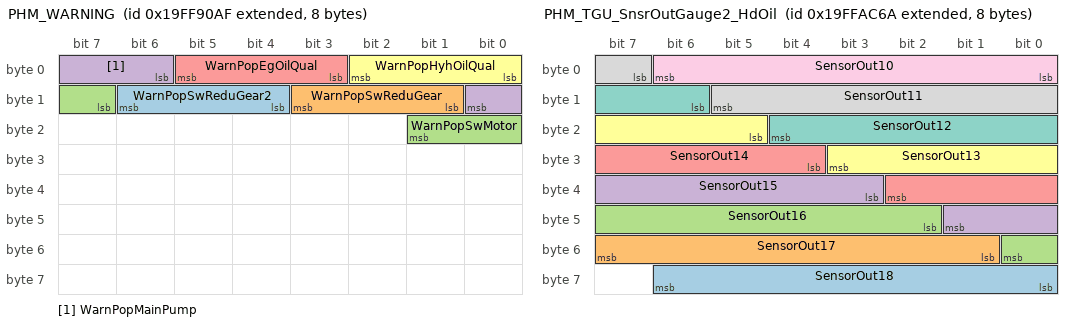
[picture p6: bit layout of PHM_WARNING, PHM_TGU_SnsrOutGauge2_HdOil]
BO_ 2583662767 PHM_WARNING: 8 Vector__XXX
 SG_ WarnPopSwReduGear2 : 12|3@1+ (1,0) [0|0] "" Vector__XXX
 SG_ WarnPopSwReduGear : 9|3@1+ (1,0) [0|0] "" Vector__XXX
 SG_ WarnPopSwMotor : 15|3@1+ (1,0) [0|0] "" Vector__XXX
 SG_ WarnPopMainPump : 6|3@1+ (1,0) [0|0] "" Vector__XXX
 SG_ WarnPopEgOilQual : 3|3@1+ (1,0) [0|7] "" Vector__XXX
 SG_ WarnPopHyhOilQual : 0|3@1+ (1,0) [0|7] "" Vector__XXX

BO_ 2565499432 GP_REQ_PHM_TGU: 8 Vector__XXX
 SG_ PGN : 0|24@1+ (1,0) [0|16777215] "" Vector__XXX

BO_ 2565818920 GP_GPSMTMS: 8 Vector__XXX
 SG_ DataSPN : 24|40@1+ (1,0) [0|0] "" Vector__XXX
 SG_ SPN : 0|19@1+ (1,0) [0|0] "" Vector__XXX

BO_ 2583669354 PHM_TGU_SnsrReplOffset_3F: 8 Vector__XXX
 SG_ ViscoSnsrOffset : 16|16@1+ (0.0015259021896696,-50) [-50|49.9999999999972] "" Vector__XXX
 SG_ DielecSnsrOffset : 0|16@1+ (0.0015259021896696,-50) [-50|49.9999999999972] "" Vector__XXX

BO_ 2583669866 PHM_TGU_SnsrOutGauge2_HdOil: 8 Vector__XXX
 SG_ SensorOut18 : 56|7@1+ (1,0) [0|120] "" Vector__XXX
 SG_ SensorOut17 : 49|7@1+ (1,0) [0|120] "" Vector__XXX
 SG_ SensorOut16 : 42|7@1+ (1,0) [0|120] "" Vector__XXX
 SG_ SensorOut15 : 35|7@1+ (1,0) [0|120] "" Vector__XXX
 SG_ SensorOut14 : 28|7@1+ (1,0) [0|120] "" Vector__XXX
 SG_ SensorOut13 : 21|7@1+ (1,0) [0|120] "" Vector__XXX
 SG_ SensorOut12 : 14|7@1+ (1,0) [0|120] "" Vector__XXX
 SG_ SensorOut11 : 7|7@1+ (1,0) [0|120] "" Vector__XXX
 SG_ SensorOut10 : 0|7@1+ (1,0) [0|120] "" Vector__XXX

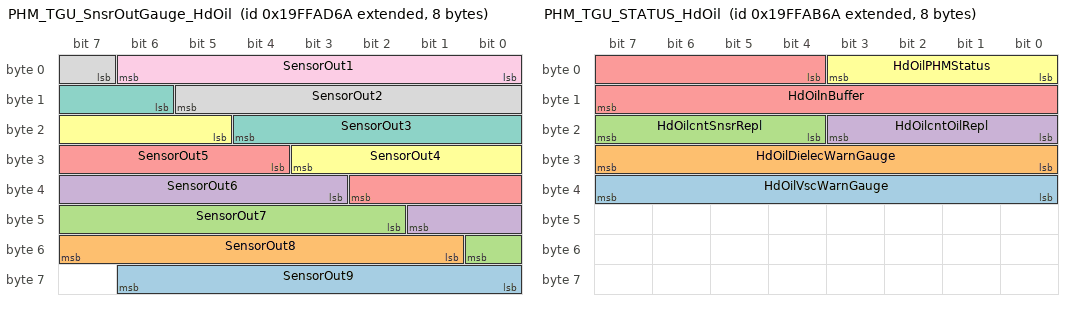
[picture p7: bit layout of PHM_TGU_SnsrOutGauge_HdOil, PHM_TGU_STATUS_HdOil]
BO_ 2583670122 PHM_TGU_SnsrOutGauge_HdOil: 8 Vector__XXX
 SG_ SensorOut9 : 56|7@1+ (1,0) [0|120] "" Vector__XXX
 SG_ SensorOut8 : 49|7@1+ (1,0) [0|120] "" Vector__XXX
 SG_ SensorOut7 : 42|7@1+ (1,0) [0|120] "" Vector__XXX
 SG_ SensorOut6 : 35|7@1+ (1,0) [0|120] "" Vector__XXX
 SG_ SensorOut5 : 28|7@1+ (1,0) [0|120] "" Vector__XXX
 SG_ SensorOut4 : 21|7@1+ (1,0) [0|120] "" Vector__XXX
 SG_ SensorOut3 : 14|7@1+ (1,0) [0|120] "" Vector__XXX
 SG_ SensorOut2 : 7|7@1+ (1,0) [0|120] "" Vector__XXX
 SG_ SensorOut1 : 0|7@1+ (1,0) [0|120] "" Vector__XXX

BO_ 2583669610 PHM_TGU_STATUS_HdOil: 8 Vector__XXX
 SG_ HdOilVscWarnGauge : 32|8@1+ (1,0) [0|255] "" Vector__XXX
 SG_ HdOilDielecWarnGauge : 24|8@1+ (1,0) [0|255] "" Vector__XXX
 SG_ HdOilcntSnsrRepl : 20|4@1+ (1,0) [0|0] "" Vector__XXX
 SG_ HdOilcntOilRepl : 16|4@1+ (1,0) [0|0] "" Vector__XXX
 SG_ HdOilnBuffer : 4|12@1+ (1,0) [0|0] "" Vector__XXX
 SG_ HdOilPHMStatus : 0|4@1+ (1,0) [0|0] "" Vector__XXX

BO_ 2583670378 PHM_TGU_SnsrReplOffset_AE: 8 Vector__XXX
 SG_ ViscoSnsrOffset : 16|16@1+ (0.0015259021896696,-50) [-50|49.9999999999972] "" Vector__XXX
 SG_ DielecSnsrOffset : 0|16@1+ (0.0015259021896696,-50) [-50|49.9999999999972] "" Vector__XXX

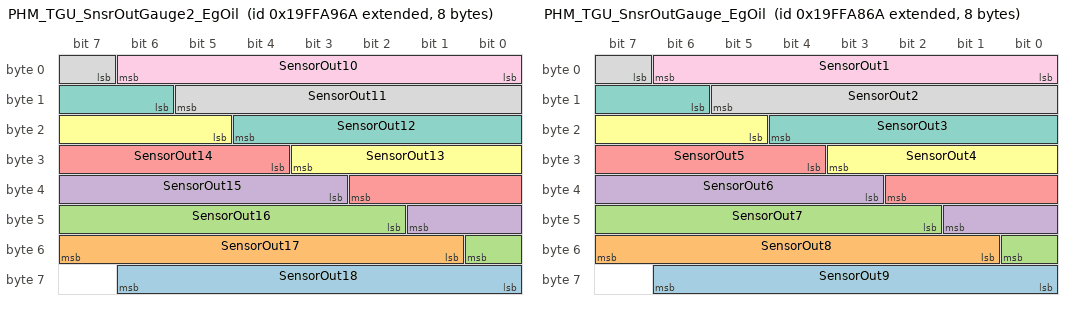
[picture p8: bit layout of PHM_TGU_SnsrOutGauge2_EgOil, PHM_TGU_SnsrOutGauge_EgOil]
BO_ 2583669098 PHM_TGU_SnsrOutGauge2_EgOil: 8 Vector__XXX
 SG_ SensorOut18 : 56|7@1+ (1,0) [0|120] "" Vector__XXX
 SG_ SensorOut17 : 49|7@1+ (1,0) [0|120] "" Vector__XXX
 SG_ SensorOut16 : 42|7@1+ (1,0) [0|120] "" Vector__XXX
 SG_ SensorOut15 : 35|7@1+ (1,0) [0|120] "" Vector__XXX
 SG_ SensorOut14 : 28|7@1+ (1,0) [0|120] "" Vector__XXX
 SG_ SensorOut13 : 21|7@1+ (1,0) [0|120] "" Vector__XXX
 SG_ SensorOut12 : 14|7@1+ (1,0) [0|120] "" Vector__XXX
 SG_ SensorOut11 : 7|7@1+ (1,0) [0|120] "" Vector__XXX
 SG_ SensorOut10 : 0|7@1+ (1,0) [0|120] "" Vector__XXX

BO_ 2583668842 PHM_TGU_SnsrOutGauge_EgOil: 8 Vector__XXX
 SG_ SensorOut9 : 56|7@1+ (1,0) [0|120] "" Vector__XXX
 SG_ SensorOut8 : 49|7@1+ (1,0) [0|120] "" Vector__XXX
 SG_ SensorOut7 : 42|7@1+ (1,0) [0|120] "" Vector__XXX
 SG_ SensorOut6 : 35|7@1+ (1,0) [0|120] "" Vector__XXX
 SG_ SensorOut5 : 28|7@1+ (1,0) [0|120] "" Vector__XXX
 SG_ SensorOut4 : 21|7@1+ (1,0) [0|120] "" Vector__XXX
 SG_ SensorOut3 : 14|7@1+ (1,0) [0|120] "" Vector__XXX
 SG_ SensorOut2 : 7|7@1+ (1,0) [0|120] "" Vector__XXX
 SG_ SensorOut1 : 0|7@1+ (1,0) [0|120] "" Vector__XXX

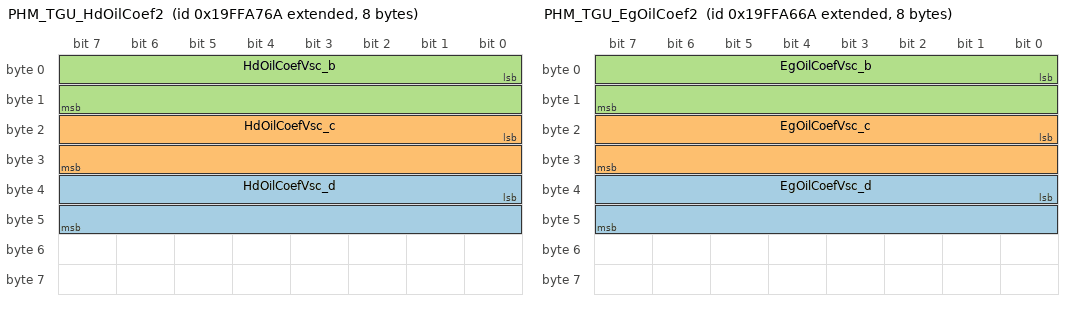
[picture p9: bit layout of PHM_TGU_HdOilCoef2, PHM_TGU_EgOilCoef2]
BO_ 2583668586 PHM_TGU_HdOilCoef2: 8 Vector__XXX
 SG_ HdOilCoefVsc_d : 32|16@1+ (0.01525925473799,-500) [-500|500.015259254175] "" Vector__XXX
 SG_ HdOilCoefVsc_c : 16|16@1+ (0.03051850947598,0) [0|2000.03051850835] "" Vector__XXX
 SG_ HdOilCoefVsc_b : 0|16@1+ (0.03051850947598,0) [0|2000.03051850835] "" Vector__XXX

BO_ 2583668330 PHM_TGU_EgOilCoef2: 8 Vector__XXX
 SG_ EgOilCoefVsc_d : 32|16@1+ (0.01525925473799,-500) [-500|500.015259254175] "" Vector__XXX
 SG_ EgOilCoefVsc_c : 16|16@1+ (0.03051850947598,0) [0|2000.03051850835] "" Vector__XXX
 SG_ EgOilCoefVsc_b : 0|16@1+ (0.03051850947598,0) [0|2000.03051850835] "" Vector__XXX

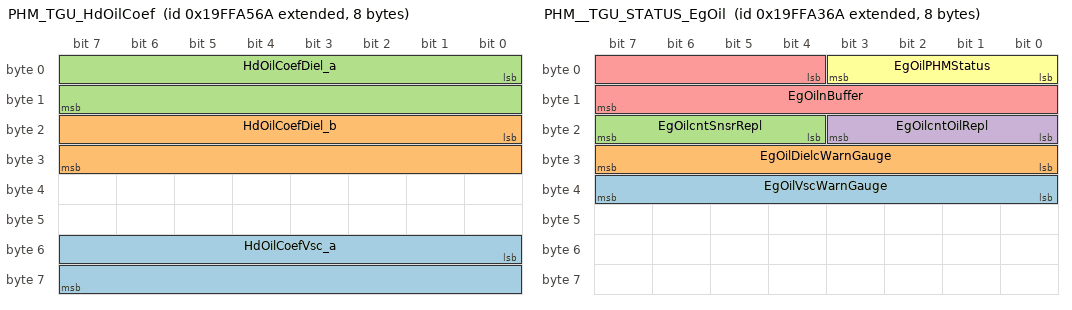
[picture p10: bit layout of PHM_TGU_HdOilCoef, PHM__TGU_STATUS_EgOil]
BO_ 2583668074 PHM_TGU_HdOilCoef: 8 Vector__XXX
 SG_ HdOilCoefVsc_a : 48|16@1+ (0.03051850947598,0) [0|2000.03051850835] "" Vector__XXX
 SG_ HdOilCoefDiel_b : 16|16@1+ (0.000305180437933928,-10) [-10|10] "" Vector__XXX
 SG_ HdOilCoefDiel_a : 0|16@1+ (0.000305180437933928,-10) [-10|10] "" Vector__XXX

BO_ 2583667818 PHM_TGU_EgOilCoef: 8 Vector__XXX
 SG_ EgOilCoefVsc_a : 48|16@1+ (0.03051850947598,0) [0|2000.03051850835] "" Vector__XXX
 SG_ EgOilCoefDiel_b : 16|16@1+ (0.000305180437933928,-10) [-10|9.99999999999997] "" Vector__XXX
 SG_ EgOilCoefDiel_a : 0|16@1+ (0.000305180437933928,-10) [-10|10] "" Vector__XXX

BO_ 2583667562 PHM__TGU_STATUS_EgOil: 8 Vector__XXX
 SG_ EgOilVscWarnGauge : 32|8@1+ (1,0) [0|255] "" Vector__XXX
 SG_ EgOilDielcWarnGauge : 24|8@1+ (1,0) [0|255] "" Vector__XXX
 SG_ EgOilcntSnsrRepl : 20|4@1+ (1,0) [0|0] "" Vector__XXX
 SG_ EgOilcntOilRepl : 16|4@1+ (1,0) [0|0] "" Vector__XXX
 SG_ EgOilnBuffer : 4|12@1+ (1,0) [0|0] "" Vector__XXX
 SG_ EgOilPHMStatus : 0|4@1+ (1,0) [0|0] "" Vector__XXX

BO_ 2565844776 GP_GPSMPHM: 8 Vector__XXX
 SG_ DataSPN : 24|40@1+ (1,0) [0|0] "" Vector__XXX
 SG_ SPN : 0|19@1+ (1,0) [0|0] "" Vector__XXX

BO_ 2566834794 PHM_TGU_DM1: 14 Vector__XXX
 SG_ LSbyteSPN_1 : 16|16@1+ (1,0) [0|0] "" Vector__XXX
 SG_ MSB3bitofSPN_1 : 37|3@1+ (1,0) [0|0] "" Vector__XXX
 SG_ FMI : 32|5@1+ (1,0) [0|0] "" Vector__XXX

BO_ 2566834762 TGU_DM1: 14 Vector__XXX
 SG_ FMI_1 : 35|5@1+ (1,0) [0|0] "" Vector__XXX
 SG_ SPN : 16|19@1+ (1,0) [0|0] "" Vector__XXX

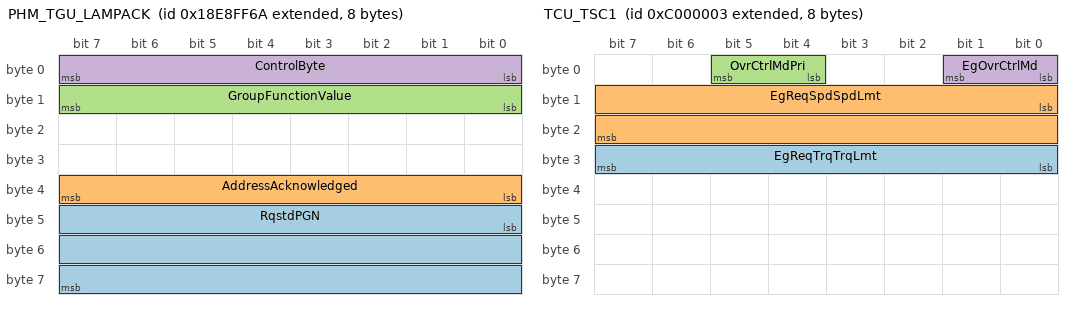
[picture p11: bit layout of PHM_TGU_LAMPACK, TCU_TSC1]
BO_ 2565406570 PHM_TGU_LAMPACK: 8 Vector__XXX
 SG_ RqstdPGN : 40|24@1+ (1,0) [0|0] "" Vector__XXX
 SG_ AddressAcknowledged : 32|8@1+ (1,0) [0|0] "" Vector__XXX
 SG_ GroupFunctionValue : 8|8@1+ (1,0) [0|0] "" Vector__XXX
 SG_ ControlByte : 0|8@1+ (1,0) [0|0] "" Vector__XXX

BO_ 2348810243 TCU_TSC1: 8 TCU
 SG_ EgReqTrqTrqLmt : 24|8@1+ (1,-125) [-125|125] "%" Vector__XXX
 SG_ EgReqSpdSpdLmt : 8|16@1+ (0.125,0) [0|8031.875] "Rpm" Vector__XXX
 SG_ OvrCtrlMdPri : 4|2@1+ (1,0) [0|3] "bit" Vector__XXX
 SG_ EgOvrCtrlMd : 0|2@1+ (1,0) [0|3] "bit" Vector__XXX

BO_ 2348810251 BRK_TSC1: 250 BRK
 SG_ EgReqTrqTrqLmt : 24|8@1+ (1,-125) [-125|125] "%" Vector__XXX
 SG_ EgReqSpdSpdLmt : 8|16@1+ (0.125,0) [0|8031.875] "Rpm" Vector__XXX
 SG_ OvrCtrlMdPri : 4|2@1+ (1,0) [0|3] "bit" Vector__XXX
 SG_ EgOvrCtrlMd : 0|2@1+ (1,0) [0|3] "bit" Vector__XXX

BO_ 2348810259 ESP_TSC1: 250 ESP
 SG_ EgReqTrqTrqLmt : 24|8@1+ (1,-125) [-125|125] "%" Vector__XXX
 SG_ EgReqSpdSpdLmt : 8|16@1+ (0.125,0) [0|8031.875] "Rpm" Vector__XXX
 SG_ OvrCtrlMdPri : 4|2@1+ (1,0) [0|3] "bit" Vector__XXX
 SG_ EgOvrCtrlMd : 0|2@1+ (1,0) [0|3] "bit" Vector__XXX

BO_ 2348810273 MCU_TSC1: 250 MCU
 SG_ EgReqTrqTrqLmt : 24|8@1+ (1,-125) [-125|125] "%" Vector__XXX
 SG_ EgReqSpdSpdLmt : 8|16@1+ (0.125,0) [0|8031.875] "Rpm" Vector__XXX
 SG_ OvrCtrlMdPri : 4|2@1+ (1,0) [0|3] "bit" Vector__XXX
 SG_ EgOvrCtrlMd : 0|2@1+ (1,0) [0|3] "bit" Vector__XXX

BO_ 2348814083 TCU_TSC1RDE: 250 TCU

BO_ 2348814091 BRK_TSC1RDE: 250 BRK

BO_ 2348814096 RDD_TSC1RDE: 250 RDD

BO_ 2348814099 ESP_TSC1RDE: 250 ESP

BO_ 2348814113 MCU_TSC1RDE: 250 MCU

BO_ 2350579745 MCU_HVESSC1: 8 MCU

BO_ 2351300641 MCU_MG1IC: 8 MCU

BO_ 2564816912 RDD_CM1: 8 RDD
 SG_ AtRgnFrcSw : 42|2@1+ (1,0) [0|3] "bit" Vector__XXX
 SG_ AtRgnInhbSw : 40|2@1+ (1,0) [0|3] "bit" Vector__XXX

BO_ 2564816929 MCU_CM1: 250 MCU
 SG_ AtRgnFrcSw : 42|2@1+ (1,0) [0|3] "bit" Vector__XXX
 SG_ AtRgnInhbSw : 40|2@1+ (1,0) [0|3] "bit" Vector__XXX

BO_ 2565800744 GP_GPSMTCU: 8 GP

BO_ 2364478241 MCU_MMIPR: 8 MCU

BO_ 2565805864 GP_GPSMCLT: 8 GP

BO_ 2565808424 GP_GPSMVCU: 8 GP
 SG_ DataSPN : 24|40@1+ (1,0) [0|0] "" Vector__XXX
 SG_ SPN : 0|19@1+ (1,0) [0|0] "" Vector__XXX

BO_ 2565808458 TMS_REQMCU: 250 TMS

BO_ 2565810241 GW_REQGP: 9 GW

BO_ 2565810250 TMS_REQGP: 250 TMS

BO_ 2565810256 KPD1_REQGP: 250 KPD1

BO_ 2565816616 GP_GPSMGW: 250 GP

BO_ 2565827112 GP_GPSMPHMTGU: 8 GP
 SG_ DataSPN : 24|40@1+ (1,0) [0|0] "" Vector__XXX
 SG_ SPN : 0|19@1+ (1,0) [0|0] "" Vector__XXX

BO_ 2565820456 GP_GPSMKPD: 250 GP

BO_ 2565821480 GP_GPSMAVM: 250 GP

BO_ 2565821505 GW_REQEXMON: 10 GW

BO_ 2364496417 MCU_MMISC: 8 MCU

BO_ 2565865487 RDE_ERC1: 8 RDE

BO_ 2565865488 RDD_ERC1: 8 RDD

BO_ 2565865733 FNR_EBC1: 8 FNR
 SG_ EgAuxShdnSw : 28|2@1+ (1,0) [0|3] "bit" Vector__XXX

BO_ 2565865739 BRK_EBC1: 250 BRK
 SG_ EgAuxShdnSw : 28|2@1+ (1,0) [0|3] "bit" Vector__XXX

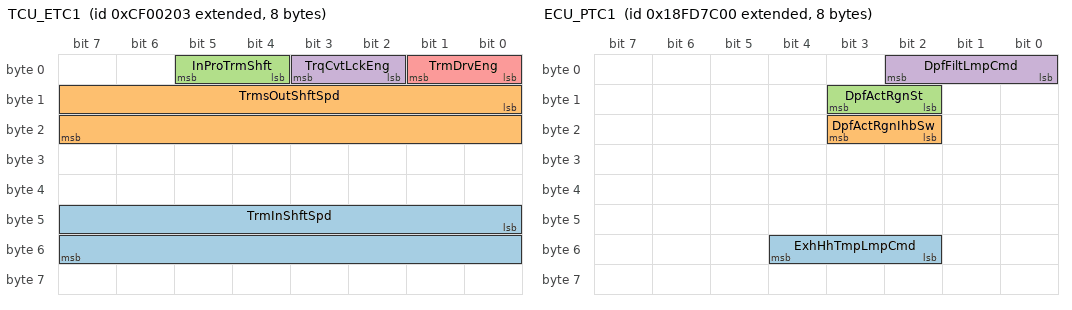
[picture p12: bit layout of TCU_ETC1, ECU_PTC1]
BO_ 2364539395 TCU_ETC1: 8 TCU
 SG_ TrmInShftSpd : 40|16@1+ (0.125,0) [0|8031.875] "Rpm" Vector__XXX
 SG_ TrmsOutShftSpd : 8|16@1+ (0.125,0) [0|8031.875] "Rpm" Vector__XXX
 SG_ InProTrmShft : 4|2@1+ (1,0) [0|3] "" Vector__XXX
 SG_ TrqCvtLckEng : 2|2@1+ (1,0) [0|3] "" Vector__XXX
 SG_ TrmDrvEng : 0|2@1+ (1,0) [0|3] "" Vector__XXX

BO_ 2364539648 ECU_EEC2: 8 ECU
 SG_ AccPdlPos2 : 32|8@1+ (0.4,0) [0|100] "%" Vector__XXX
 SG_ EgPctLoadCurSpd : 16|8@1+ (1,0) [0|250] "%" Vector__XXX
 SG_ AccPdlPos1 : 8|8@1+ (0.4,0) [0|100] "%" Vector__XXX

BO_ 2364539904 ECU_EEC1: 8 ECU
 SG_ EgSpd : 24|16@1+ (0.125,0) [0|8031.875] "Rpm" Vector__XXX
 SG_ ActEgPctTrq : 16|8@1+ (1,-125) [-125|125] "%" Vector__XXX
 SG_ DrvDmdEgPctTrq : 8|8@1+ (1,-125) [-125|125] "%" Vector__XXX

BO_ 2565866755 TCU_ETC2: 8 TCU
 SG_ TrmsCurGr : 24|8@1+ (1,-125) [-125|125] "" Vector__XXX
 SG_ TrmsActGrRatio : 8|16@1+ (0.001,0) [0|64.255] "" Vector__XXX
 SG_ TrmsSelGr : 0|8@1+ (1,-125) [-125|125] "" Vector__XXX

BO_ 2565867011 TCU_EAC1: 8 TCU
 SG_ DifLckStCtrEng : 16|2@1+ (1,0) [0|3] "" Vector__XXX

BO_ 2364542241 MCU_LOI: 250 MCU
 SG_ BladeAutoMdCmd : 8|4@1+ (1,0) [0|15] "" Vector__XXX
 SG_ DsrGrdOfsSw : 4|4@1+ (1,0) [0|15] "" Vector__XXX
 SG_ BladeCtrlMdSw : 0|4@1+ (1,0) [0|15] "" Vector__XXX

BO_ 2565869137 KPD2_AT1IG1: 250 KPD2
 SG_ AtIntGasSsHtCtrl : 45|2@1+ (1,0) [0|3] "states" Vector__XXX
 SG_ InRngAtIntGasSsTmp : 34|2@1+ (1,0) [0|3] "states" Vector__XXX

BO_ 2565869394 ATSGO_AT1OG1: 250 ATSGO
 SG_ AtOutGasSsHtCtrl : 45|2@1+ (1,0) [0|3] "states" Vector__XXX
 SG_ InRngAtOutGasSsTmp : 34|2@1+ (1,0) [0|3] "states" Vector__XXX

BO_ 2565875998 ACU_SSI2: 8 ACU

BO_ 2565876161 IMU1_SSI2: 8 IMU1

BO_ 2565876162 IMU2_SSI2: 8 IMU2

BO_ 2565876163 IMU3_SSI2: 8 IMU3

BO_ 2565876164 IMU4_SSI2: 8 IMU4

BO_ 2565876165 IMU5_SSI2: 8 IMU5

BO_ 2364575987 AGW_HVESSD1: 8 AGW

BO_ 2364576243 AGW_HVESSD2: 8 AGW

BO_ 2364576755 AGW_HVESSD4: 8 AGW

BO_ 2364577011 AGW_HVESSD5: 8 AGW

BO_ 2364577267 AGW_HVESSD6: 8 AGW

BO_ 2364637584 PMI_MG1IMF1: 8 PMI

BO_ 2364641057 MCU_IPGA: 250 MCU

BO_ 2364641267 AGW_IPGA: 250 AGW

BO_ 2365288848 PMI_MG1IMT: 8 PMI

BO_ 2365289104 PMI_MG1IT: 8 PMI

BO_ 2365289360 PMI_MG1IR2: 8 PMI

BO_ 2365289616 PMI_MG1IS1: 8 PMI

BO_ 2566675955 AGW_HVESSCFG: 8 AGW

BO_ 2633785075 AGW_HVESSHIST: 8 AGW

BO_ 2566709248 ECU_DPFC2: 8 ECU

BO_ 2633828415 HDOQS_OQM1: 8 HDOQS
 SG_ Oildieleccst : 48|16@1+ (0.00012207,0) [0|7.84360785] "" Vector__XXX
 SG_ Oildensity : 16|16@1+ (3.052E-005,0) [0|1.9610626] "g/cm3" Vector__XXX
 SG_ OilVcsty : 0|16@1+ (0.015625,0) [0|1003.984375] "cP" Vector__XXX

BO_ 2633828526 EGOQS_OQM1: 8 EGOQS
 SG_ Oildieleccst : 48|16@1+ (0.00012207,0) [0|7.84360785] "" Vector__XXX
 SG_ Oildensity : 16|16@1+ (3.052E-005,0) [0|1.9610626] "g/cm3" Vector__XXX
 SG_ OilVcsty : 0|16@1+ (0.015625,0) [0|1003.984375] "cP" Vector__XXX

BO_ 2566719744 ECU_HRLFC: 8 ECU

BO_ 2365394514 ATSGO_AT1OGC2: 250 ATSGO

BO_ 2365394770 ATSGO_AT1OGC1: 250 ATSGO

BO_ 2365395025 KPD2_AT1IGC2: 250 KPD2

BO_ 2365395281 KPD2_AT1IGC1: 250 KPD2

BO_ 2566722989 OBC_BCH1: 8 OBC

BO_ 2566725632 ECU_A1DOC: 8 ECU

BO_ 2566748928 ECU_AT1S: 8 ECU
 SG_ DpfSootLoadPct : 0|8@1+ (1,0) [0|250] "%" Vector__XXX

BO_ 2566749184 ECU_PTC1: 8 ECU
 SG_ ExhHhTmpLmpCmd : 50|3@1+ (1,0) [0|7] "states" Vector__XXX
 SG_ DpfActRgnIhbSw : 18|2@1+ (1,0) [0|3] "states" Vector__XXX
 SG_ DpfActRgnSt : 10|2@1+ (1,0) [0|3] "states" Vector__XXX
 SG_ DpfFiltLmpCmd : 0|3@1+ (1,0) [0|7] "states" Vector__XXX

BO_ 2566755587 TCU_TRF2: 8 TCU
 SG_ TrqCvtOilOutTmp : 8|16@1+ (0.03125,-273) [-273|1735] "deg" Vector__XXX
 SG_ TrmOilFiltRstrSw : 0|2@1+ (1,0) [0|3] "" Vector__XXX

BO_ 2566757120 ECU_A1DEFI1: 8 ECU
 SG_ AtDefPpt : 40|4@1+ (1,0) [0|15] "states" Vector__XXX
 SG_ AtDefCct : 8|8@1+ (0.25,0) [0|62.5] "%" Vector__XXX

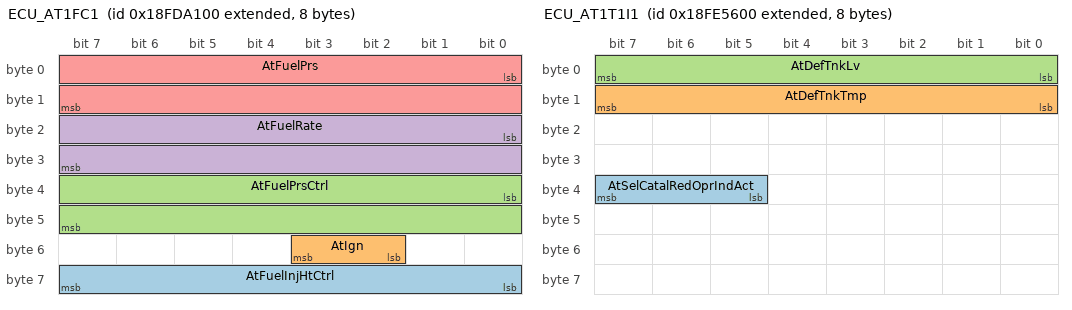
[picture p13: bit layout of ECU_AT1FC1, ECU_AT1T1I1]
BO_ 2566758656 ECU_AT1FC1: 8 ECU
 SG_ AtFuelInjHtCtrl : 56|8@1+ (0.4,0) [0|100] "%" Vector__XXX
 SG_ AtIgn : 50|2@1+ (1,0) [0|3] "states" Vector__XXX
 SG_ AtFuelPrsCtrl : 32|16@1+ (0.0025,0) [0|160.6375] "%" Vector__XXX
 SG_ AtFuelRate : 16|16@1+ (0.05,0) [0|3212.75] "L/h" Vector__XXX
 SG_ AtFuelPrs : 0|16@1+ (0.1,0) [0|6425.5] "kPa" Vector__XXX

BO_ 2566763008 ECU_AT1IMG: 8 ECU

BO_ 2566763264 ECU_AT1OG2: 8 ECU
 SG_ AtDpfOutGasTmp : 16|16@1+ (0.03125,-273) [-273|1734.96875] "�C" Vector__XXX

BO_ 2566763325 EEC_AT1OG2: 250 EEC
 SG_ AtDpfOutGasTmp : 16|16@1+ (0.03125,-273) [-273|1734.96875] "�C" Vector__XXX

BO_ 2566763520 ECU_AT1IG2: 8 ECU
 SG_ AtDpfIntGasTmp : 16|16@1+ (0.03125,-273) [-273|1734.96875] "�C" Vector__XXX
 SG_ AtExhGasTmp : 0|16@1+ (0.03125,-273) [-273|1734.96875] "�C" Vector__XXX

BO_ 2566763581 EEC_AT1IG2: 250 EEC
 SG_ AtDpfIntGasTmp : 16|16@1+ (0.03125,-273) [-273|1734.96875] "�C" Vector__XXX
 SG_ AtExhGasTmp : 0|16@1+ (0.03125,-273) [-273|1734.96875] "�C" Vector__XXX

BO_ 2365441523 AGW_ECUID: 250 AGW

BO_ 2566769997 CBSW_OWW: 8 CBSW

BO_ 2566771968 ECU_EEC5: 8 ECU
 SG_ EgEgrVvCtrl : 32|16@1+ (0.0025,0) [0|160.6375] "%" Vector__XXX

BO_ 2365445841 EJRH_BJM1: 8 EJRH

BO_ 2365446097 EJRH_EJM1: 8 EJRH

BO_ 2365446352 EJLH_BJM2: 8 EJLH

BO_ 2365446608 EJLH_EJM2: 8 EJLH

BO_ 2365446893 EPDLT_BJM3: 8 EPDLT

BO_ 2365446894 EPDL2_BJM3: 8 EPDL2

BO_ 2365446895 EPDLR_BJM3: 8 EPDLR

BO_ 2365446896 EPDLA_BJM3: 8 EPDLA

BO_ 2365468962 TRBDZ_AV01C: 250 TRBDZ
 SG_ PortFlowHighResolution : 24|16@1+ (0.0015625,0) [0|100.3984375] "" Vector__XXX
 SG_ FailSafeMd : 22|2@1+ (1,0) [0|3] "" Vector__XXX
 SG_ VvSt : 16|4@1+ (1,0) [0|15] "" Vector__XXX
 SG_ ResolutionMd : 8|2@1+ (1,0) [0|3] "" Vector__XXX
 SG_ AuxVv1PortFlowCmd : 0|8@1+ (0.4,0) [0|100] "" Vector__XXX

BO_ 2365469218 TRBDZ_AV02C: 250 TRBDZ
 SG_ PortFlowHighResolution : 24|16@1+ (0.0015625,0) [0|100.3984375] "" Vector__XXX
 SG_ FailSafeMd : 22|2@1+ (1,0) [0|3] "" Vector__XXX
 SG_ VvSt : 16|4@1+ (1,0) [0|15] "" Vector__XXX
 SG_ ResolutionMd : 8|2@1+ (1,0) [0|3] "" Vector__XXX
 SG_ AuxVv1PortFlowCmd : 0|8@1+ (0.4,0) [0|100] "" Vector__XXX

BO_ 2365473101 CBSW_LCMD: 8 CBSW

BO_ 2566801441 MCU_WBSD: 250 MCU

BO_ 2566801923 TCU_ETC7: 8 TCU

BO_ 2566802176 ECU_TCFG2: 8 ECU
 SG_ EgThrtActCtrlCmd : 0|16@1+ (0.0025,0) [0|160.6375] "%" Vector__XXX

BO_ 2566803211 BRK_VDC1: 250 BRK

BO_ 2566804992 ECU_AT1T1I1: 8 ECU
 SG_ AtSelCatalRedOprIndAct : 37|3@1+ (1,0) [0|7] "states" Vector__XXX
 SG_ AtDefTnkTmp : 8|8@1+ (1,-40) [-40|210] "�C" Vector__XXX
 SG_ AtDefTnkLv : 0|8@1+ (0.4,0) [0|100] "%" Vector__XXX

BO_ 2566804993 ECU1_AT1T1I1: 250 ECU1
 SG_ AtSelCatalRedOprIndAct : 37|3@1+ (1,0) [0|7] "states" Vector__XXX
 SG_ AtDefTnkTmp : 8|8@1+ (1,-40) [-40|210] "�C" Vector__XXX
 SG_ AtDefTnkLv : 0|8@1+ (0.4,0) [0|100] "%" Vector__XXX

BO_ 2365484270 EPDL2_TCO1: 250 EPDL2

BO_ 2566811147 BRK_HRWS: 250 BRK

BO_ 2633927682 ECU_AAI2EDC: 250 ECU

BO_ 2566831360 ECU_FD: 8 ECU

BO_ 2566831616 ECU_EEC4: 8 ECU

BO_ 2566831883 BRK_EBC2: 250 BRK

BO_ 2566832622 EPDL2_VDHR: 250 EPDL2

BO_ 2566834749 EEC_DM1: 250 EEC

BO_ 2566834944 ECU_DM2: 250 ECU

BO_ 2566835456 ECU_DM4: 250 ECU

BO_ 2566835712 ECU_DM5: 250 ECU

BO_ 2566835968 ECU_DM6: 250 ECU

BO_ 2566838528 ECU_AUXIO1: 8 ECU

BO_ 2566838784 ECU_SOFT: 8 ECU

BO_ 2566838787 TCU_SOFT: 67 TCU

BO_ 2365512435 AGW_SOFT: 250 AGW

BO_ 2566839296 ECU_IDLOP: 8 ECU

BO_ 2566840064 ECU_EEC3: 8 ECU
 SG_ At1ExhGasMasFlw : 40|16@1+ (0.2,0) [0|12851] "kg/h" Vector__XXX
 SG_ EgDsrOprSpd : 8|16@1+ (0.125,0) [0|8031.875] "Rpm" Vector__XXX
 SG_ NrmFricPctTrq : 0|8@1+ (1,-125) [-125|125] "%" Vector__XXX

BO_ 2566841344 ECU_SHUTDWN: 8 ECU

BO_ 2566841600 ECU_HOURS: 8 ECU
 SG_ EgTotRev : 32|32@1+ (1000,0) [0|4211081215000] "r" Vector__XXX
 SG_ EgTotHrOpr : 0|32@1+ (0.05,0) [0|210554060.75] "hr" Vector__XXX

BO_ 2566841879 CLST_TD: 8 CLST

BO_ 2566842094 EPDL2_TD: 250 EPDL2

BO_ 2566842112 ECU_VH: 8 ECU

BO_ 2566842624 ECU_LFC1: 8 ECU
 SG_ EgTotFuelUsed : 32|32@1+ (0.5,0) [0|2105540607.5] "L" Vector__XXX
 SG_ EgTripFuel : 0|32@1+ (0.5,0) [0|2105540607.5] "L" Vector__XXX

BO_ 2566843136 ECU_CI: 8 ECU

BO_ 2566843392 ECU_VI: 8 ECU

BO_ 2566843648 ECU_CCSS: 8 ECU

BO_ 2566843651 TCU_CCSS: 8 TCU

BO_ 2566843653 FNR_CCSS: 8 FNR

BO_ 2566843904 ECU_ET1: 8 ECU
 SG_ EgFuelTmp : 8|8@1+ (1,-40) [-40|210] "�C" Vector__XXX
 SG_ EgCoolTmp : 0|8@1+ (1,-40) [-40|210] "�C" Vector__XXX

BO_ 2566843967 HDOQS_OT1: 8 HDOQS
 SG_ OilAvrgTmp : 16|16@1+ (0.03125,-273) [-273|1734.96875] "?" Vector__XXX

BO_ 2566844078 EGOQS_OT1: 8 EGOQS
 SG_ OilAvrgTmp : 16|16@1+ (0.03125,-273) [-273|1734.96875] "?" Vector__XXX

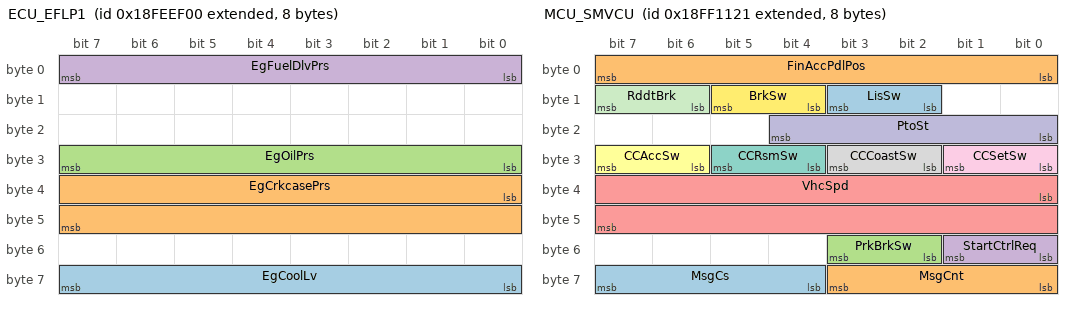
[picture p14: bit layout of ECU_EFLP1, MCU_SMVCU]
BO_ 2566844160 ECU_EFLP1: 8 ECU
 SG_ EgCoolLv : 56|8@1+ (0.4,0) [0|100] "%" Vector__XXX
 SG_ EgCrkcasePrs : 32|16@1+ (0.0078125,-250) [-250|251.99] "kPa" Vector__XXX
 SG_ EgOilPrs : 24|8@1+ (4,0) [0|1000] "kPa" Vector__XXX
 SG_ EgFuelDlvPrs : 0|8@1+ (4,0) [0|1000] "kPa" Vector__XXX

BO_ 2566844672 ECU_CCVS: 8 ECU
 SG_ WhlVhcSpd : 8|16@1+ (0.00390625,0) [0|250.996] "km/h" Vector__XXX

BO_ 2566844675 TCU_CCVS: 8 TCU
 SG_ WhlVhcSpd : 8|16@1+ (0.00390625,0) [0|250.996] "km/h" Vector__XXX

BO_ 2566844705 MCU_CCVS: 8 MCU
 SG_ WhlVhcSpd : 8|16@1+ (0.00390625,0) [0|250.996] "km/h" Vector__XXX

BO_ 2566844928 ECU_LFE1: 8 ECU
 SG_ EgThrtVvPos : 48|8@1+ (0.4,0) [0|100] "%" Vector__XXX
 SG_ EgFuelRate : 0|16@1+ (0.05,0) [0|3212.75] "L/h" Vector__XXX

BO_ 2566845696 ECU_AMB: 8 ECU
 SG_ EgAirIntTmp : 40|8@1+ (1,-40) [-40|210] "�C" Vector__XXX
 SG_ AmbAirTmp : 24|16@1+ (0.03125,-273) [-273|1734.96875] "�C" Vector__XXX
 SG_ BaroPrs : 0|8@1+ (0.5,0) [0|125] "kPa" Vector__XXX

BO_ 2566845952 ECU_IC1: 8 ECU
 SG_ EgAirIntPrs : 24|8@1+ (2,0) [0|500] "kPa" Vector__XXX
 SG_ EgIntMnfdTmp : 16|8@1+ (1,-40) [-40|210] "�C" Vector__XXX
 SG_ EgIntMnfdPrs : 8|8@1+ (2,0) [0|500] "kPa" Vector__XXX

BO_ 2566846208 ECU_VEP1: 8 ECU
 SG_ KeyswBatPtc : 48|16@1+ (0.05,0) [0|3212.75] "V" Vector__XXX
 SG_ BatPtcPowIn : 32|16@1+ (0.05,0) [0|3212.75] "V" Vector__XXX

BO_ 2566846467 TCU_TF: 8 TCU

BO_ 2566846981 FNR_B1: 8 FNR

BO_ 2566847235 TCU_RF: 8 TCU
 SG_ TrmOilFiltRstrSw : 8|8@1+ (1,-40) [-40|210] "deg" Vector__XXX

BO_ 2566847511 CLST_DD1: 8 CLST

BO_ 2566847521 MCU_DD1: 8 MCU

BO_ 2566848256 ECU_WFI: 8 ECU

BO_ 2566849085 EEC_TXEGSPM: 8 EEC

BO_ 2566851074 ECU_ACTVCODERx: 8 ECU

BO_ 2566852897 MCU_SMVCU: 8 MCU
 SG_ MsgCs : 60|4@1+ (1,0) [0|15] "count" Vector__XXX
 SG_ MsgCnt : 56|4@1+ (1,0) [0|15] "count" Vector__XXX
 SG_ PrkBrkSw : 50|2@1+ (1,0) [0|3] "" Vector__XXX
 SG_ StartCtrlReq : 48|2@1+ (1,0) [0|3] "" Vector__XXX
 SG_ VhcSpd : 32|16@1+ (0.00390625,0) [0|250.996] "km/h" Vector__XXX
 SG_ CCAccSw : 30|2@1+ (1,0) [0|3] "" Vector__XXX
 SG_ CCRsmSw : 28|2@1+ (1,0) [0|3] "" Vector__XXX
 SG_ CCCoastSw : 26|2@1+ (1,0) [0|3] "" Vector__XXX
 SG_ CCSetSw : 24|2@1+ (1,0) [0|3] "" Vector__XXX
 SG_ PtoSt : 16|5@1+ (1,0) [0|31] "" Vector__XXX
 SG_ RddtBrk : 14|2@1+ (1,0) [0|3] "" Vector__XXX
 SG_ BrkSw : 12|2@1+ (1,0) [0|3] "" Vector__XXX
 SG_ LisSw : 10|2@1+ (1,0) [0|3] "" Vector__XXX
 SG_ FinAccPdlPos : 0|8@1+ (0.4,0) [0|100] "%" Vector__XXX

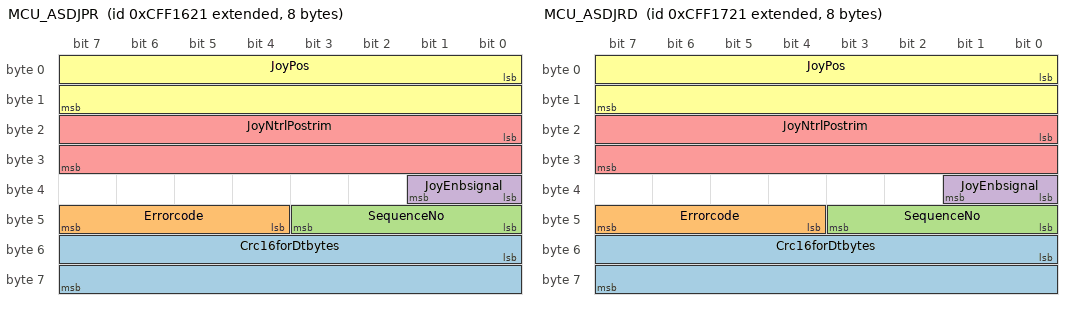
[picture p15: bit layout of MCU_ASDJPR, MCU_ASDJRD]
BO_ 2365527585 MCU_ASDJPR: 8 MCU
 SG_ Crc16forDtbytes : 48|16@1+ (1,0) [0|65535] "" Vector__XXX
 SG_ Errorcode : 44|4@1+ (1,0) [0|15] "" Vector__XXX
 SG_ SequenceNo : 40|4@1+ (1,0) [0|15] "count" Vector__XXX
 SG_ JoyEnbsignal : 32|2@1+ (1,0) [0|3] "" Vector__XXX
 SG_ JoyNtrlPostrim : 16|16@1+ (0.1,-20) [-20|20] "%" Vector__XXX
 SG_ JoyPos : 0|16@1+ (0.1,-100) [-100|100] "%" Vector__XXX

BO_ 2365527841 MCU_ASDJRD: 8 MCU
 SG_ Crc16forDtbytes : 48|16@1+ (1,0) [0|65535] "" Vector__XXX
 SG_ Errorcode : 44|4@1+ (1,0) [0|15] "" Vector__XXX
 SG_ SequenceNo : 40|4@1+ (1,0) [0|15] "count" Vector__XXX
 SG_ JoyEnbsignal : 32|2@1+ (1,0) [0|3] "" Vector__XXX
 SG_ JoyNtrlPostrim : 16|16@1+ (0.1,-20) [-20|20] "%" Vector__XXX
 SG_ JoyPos : 0|16@1+ (0.1,-100) [-100|100] "%" Vector__XXX

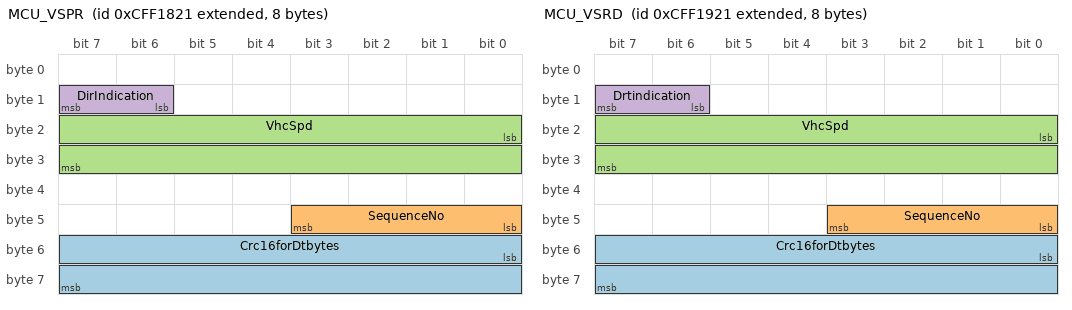
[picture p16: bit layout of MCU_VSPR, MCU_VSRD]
BO_ 2365528097 MCU_VSPR: 8 MCU
 SG_ Crc16forDtbytes : 48|16@1+ (1,0) [0|65535] "" Vector__XXX
 SG_ SequenceNo : 40|4@1+ (1,0) [0|15] "" Vector__XXX
 SG_ VhcSpd : 16|16@1+ (0.00390625,0) [0|250.996] "" Vector__XXX
 SG_ DirIndication : 14|2@1+ (1,0) [0|3] "" Vector__XXX

BO_ 2365528353 MCU_VSRD: 8 MCU
 SG_ Crc16forDtbytes : 48|16@1+ (1,0) [0|65535] "" Vector__XXX
 SG_ SequenceNo : 40|4@1+ (1,0) [0|15] "" Vector__XXX
 SG_ VhcSpd : 16|16@1+ (0.00390625,0) [0|250.996] "" Vector__XXX
 SG_ Drtindication : 14|2@1+ (1,0) [0|3] "" Vector__XXX

BO_ 2566856451 TCU_TCU2: 8 TCU

BO_ 2566856707 TCU_TCU3: 8 TCU

BO_ 2365530117 FNR_SLP1: 8 FNR

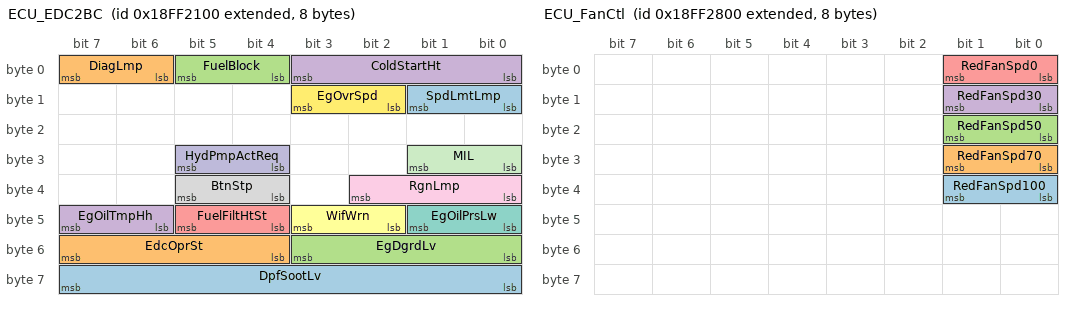
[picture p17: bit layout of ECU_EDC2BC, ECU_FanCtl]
BO_ 2566856960 ECU_EDC2BC: 8 ECU
 SG_ DpfSootLv : 56|8@1+ (1,0) [0|255] "%" Vector__XXX
 SG_ EdcOprSt : 52|4@1+ (1,0) [0|15] "" Vector__XXX
 SG_ EgDgrdLv : 48|4@1+ (1,0) [0|4] "" Vector__XXX
 SG_ EgOilTmpHh : 46|2@1+ (1,0) [0|3] "" Vector__XXX
 SG_ FuelFiltHtSt : 44|2@1+ (1,0) [0|3] "" Vector__XXX
 SG_ WifWrn : 42|2@1+ (1,0) [0|3] "" Vector__XXX
 SG_ EgOilPrsLw : 40|2@1+ (1,0) [0|3] "" Vector__XXX
 SG_ BtnStp : 36|2@1+ (1,0) [0|3] "" Vector__XXX
 SG_ RgnLmp : 32|3@1+ (1,0) [0|7] "" Vector__XXX
 SG_ HydPmpActReq : 28|2@1+ (1,0) [0|3] "" Vector__XXX
 SG_ MIL : 24|2@1+ (1,0) [0|3] "" Vector__XXX
 SG_ EgOvrSpd : 10|2@1+ (1,0) [0|3] "" Vector__XXX
 SG_ SpdLmtLmp : 8|2@1+ (1,0) [0|3] "" Vector__XXX
 SG_ DiagLmp : 6|2@1+ (1,0) [0|3] "" Vector__XXX
 SG_ FuelBlock : 4|2@1+ (1,0) [0|3] "" Vector__XXX
 SG_ ColdStartHt : 0|4@1+ (1,0) [0|15] "" Vector__XXX

BO_ 2365530373 FNR_SLP2: 8 FNR

BO_ 2566857219 TCU_TCU4: 8 TCU
 SG_ CnvtTurbTrq : 16|16@1+ (1,-3200) [-32000|32255] "Nm" Vector__XXX
 SG_ CnvtPmpTrq : 0|16@1+ (1,-3200) [-32000|32255] "Nm" Vector__XXX

BO_ 2566857731 TCU_ZFCC: 8 TCU

BO_ 2566857984 ECU_ENGCOND: 10 ECU
 SG_ PhsDifCrkCam : 32|48@1+ (0.1,-720) [-720|5833.5] "degCrS" Vector__XXX
 SG_ EgOprCmd : 16|16@1+ (1,0) [0|65535] "" Vector__XXX
 SG_ AirMassPrs : 0|16@1+ (0.25,0) [0|16383.75] "kg/h" Vector__XXX

BO_ 2566858752 ECU_FanCtl: 8 ECU
 SG_ RedFanSpd100 : 32|2@1+ (1,0) [0|255] "" Vector__XXX
 SG_ RedFanSpd70 : 24|2@1+ (1,0) [0|255] "" Vector__XXX
 SG_ RedFanSpd50 : 16|2@1+ (1,0) [0|255] "" Vector__XXX
 SG_ RedFanSpd30 : 8|2@1+ (1,0) [0|255] "" Vector__XXX
 SG_ RedFanSpd0 : 0|2@1+ (1,0) [0|255] "" Vector__XXX

BO_ 2566859297 MCU_VEHICLE2: 8 MCU

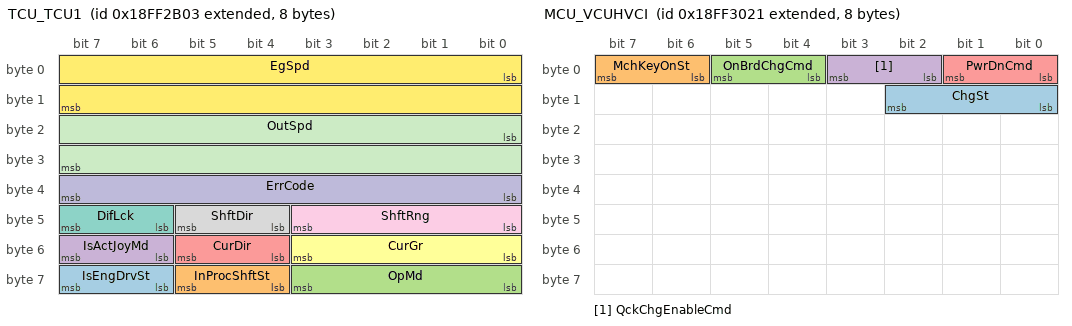
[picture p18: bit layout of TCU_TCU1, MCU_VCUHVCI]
BO_ 2566859523 TCU_TCU1: 8 TCU
 SG_ IsEngDrvSt : 62|2@1+ (1,0) [0|3] "" Vector__XXX
 SG_ InProcShftSt : 60|2@1+ (1,0) [0|3] "" Vector__XXX
 SG_ OpMd : 56|4@1+ (1,0) [0|4] "" Vector__XXX
 SG_ IsActJoyMd : 54|2@1+ (1,0) [0|3] "" Vector__XXX
 SG_ CurDir : 52|2@1+ (1,0) [0|3] "" Vector__XXX
 SG_ CurGr : 48|4@1+ (1,0) [0|15] "" Vector__XXX
 SG_ DifLck : 46|2@1+ (1,0) [0|3] "" Vector__XXX
 SG_ ShftDir : 44|2@1+ (1,0) [0|3] "" Vector__XXX
 SG_ ShftRng : 40|4@1+ (1,0) [0|4] "" Vector__XXX
 SG_ ErrCode : 32|8@1+ (1,0) [0|255] "" Vector__XXX
 SG_ OutSpd : 16|16@1+ (1,0) [0|8031.875] "Rpm" Vector__XXX
 SG_ EgSpd : 0|16@1+ (1,0) [0|8031.875] "Rpm" Vector__XXX

BO_ 2566860833 MCU_VCUHVCI: 8 MCU
 SG_ ChgSt : 8|3@1+ (1,0) [0|7] "" Vector__XXX
 SG_ MchKeyOnSt : 6|2@1+ (1,0) [0|3] "" Vector__XXX
 SG_ OnBrdChgCmd : 4|2@1+ (1,0) [0|3] "" Vector__XXX
 SG_ QckChgEnableCmd : 2|2@1+ (1,0) [0|3] "" Vector__XXX
 SG_ PwrDnCmd : 0|2@1+ (1,0) [0|3] "" Vector__XXX

BO_ 2566861056 ECU_TFI4CMD: 8 ECU
 SG_ FiltTm : 8|8@1+ (1,0) [0|255] "" Vector__XXX
 SG_ Cmd : 0|8@1+ (1,0) [0|255] "" Vector__XXX

BO_ 2566861119 HDOQS_OSM: 8 HDOQS
 SG_ StMsgCode : 0|24@1+ (1,0) [0|16777215] "" Vector__XXX

BO_ 2566861230 EGOQS_OSM: 8 EGOQS
 SG_ StMsgCode : 0|24@1+ (1,0) [0|16777215] "" Vector__XXX

BO_ 2566863330 LC510_TFI4Data: 8 LC510

BO_ 2566863533 OBC_OBCMI: 14 OBC
 SG_ FanSt : 104|1@1+ (1,0) [0|1] "" Vector__XXX
 SG_ PdVlt : 96|8@1+ (0.2,0) [0|50] "" Vector__XXX
 SG_ CpVlt : 80|16@1+ (0.05,-1606) [-1606|1606.75] "" Vector__XXX
 SG_ ObcAtmosphereTemp : 72|8@1+ (1,-40) [-40|210] "" Vector__XXX
 SG_ ObcMaxTemp : 64|8@1+ (1,-40) [-40|210] "" Vector__XXX
 SG_ PfcVlt : 48|16@1+ (1,0) [0|65535] "" Vector__XXX
 SG_ AcInCur : 40|8@1+ (0.25,0) [0|62.5] "" Vector__XXX
 SG_ AcInFrequency : 32|8@1+ (1,0) [0|250] "" Vector__XXX
 SG_ AcInVlt : 16|16@1+ (0.01,0) [0|642.55] "" Vector__XXX
 SG_ ChgElapsedTm : 0|16@1+ (1,0) [0|64255] "" Vector__XXX

BO_ 2566864354 LC510_RxTFI4OBD: 8 LC510

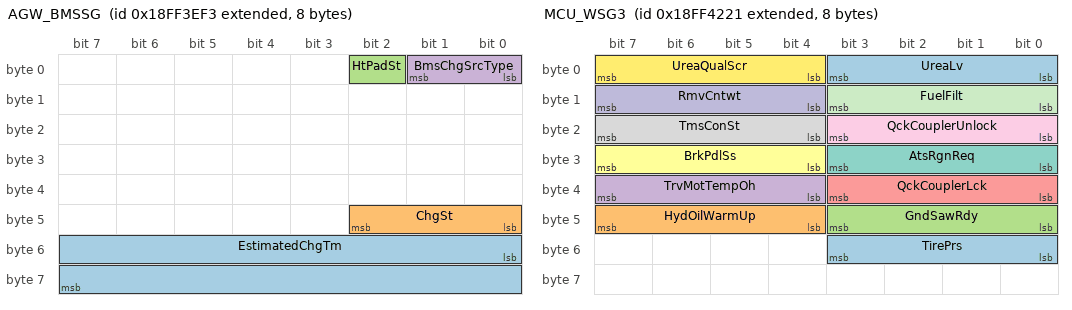
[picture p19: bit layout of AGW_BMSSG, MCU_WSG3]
BO_ 2566864627 AGW_BMSSG: 8 AGW
 SG_ EstimatedChgTm : 48|16@1+ (1,0) [0|64255] "" Vector__XXX
 SG_ ChgSt : 40|3@1+ (1,0) [0|7] "" Vector__XXX
 SG_ HtPadSt : 2|1@1+ (1,0) [0|1] "" Vector__XXX
 SG_ BmsChgSrcType : 0|2@1+ (1,0) [0|3] "" Vector__XXX

BO_ 2566864680 GP_USUHDI: 63 GP
 SG_ FuelEfficiencybyUser : 488|16@1+ (0.05,0) [0|3212.75] "" Vector__XXX
 SG_ EcnMdFuelUsgbyUser : 456|32@1+ (0.5,0) [0|2105540607.5] "" Vector__XXX
 SG_ StdMdFuelUsgbyUser : 424|32@1+ (0.5,0) [0|2105540607.5] "" Vector__XXX
 SG_ PwrMdFuelUsgbyUser : 392|32@1+ (0.5,0) [0|2105540607.5] "" Vector__XXX
 SG_ PwrPlusMdFuelUsgbyUser : 360|32@1+ (0.5,0) [0|2105540607.5] "" Vector__XXX
 SG_ TotalFuelUsgbyUser : 328|32@1+ (0.5,0) [0|2105540607.5] "" Vector__XXX
 SG_ EcnMdOprtgHrbyUser : 296|32@1+ (1,0) [0|4211081215] "min" Vector__XXX
 SG_ StdMdOprtgHrbyUser : 264|32@1+ (1,0) [0|4211081215] "min" Vector__XXX
 SG_ PwrMdOprtgHrbyUser : 232|32@1+ (1,0) [0|4211081215] "min" Vector__XXX
 SG_ PwrPlusMdOprtgHrbyUser : 200|32@1+ (1,0) [0|4211081215] "min" Vector__XXX
 SG_ IdleOprtgHrbyUser : 168|32@1+ (1,0) [0|4211081215] "min" Vector__XXX
 SG_ TotalOprtgHrbyUser : 136|32@1+ (1,0) [0|4211081215] "min" Vector__XXX
 SG_ UserName : 8|128@1+ (1,0) [0|255] "" Vector__XXX
 SG_ UserSeparatorFlag : 3|5@1+ (1,0) [0|31] "" Vector__XXX
 SG_ UserSeparatorSlot : 0|3@1+ (1,0) [0|7] "" Vector__XXX

BO_ 2566864929 MCU_WSG1: 8 MCU
 SG_ InvOh : 62|2@1+ (1,0) [0|3] "" Vector__XXX
 SG_ MotOh : 60|2@1+ (1,0) [0|3] "" Vector__XXX
 SG_ BatOh : 58|2@1+ (1,0) [0|3] "" Vector__XXX
 SG_ Bms : 56|2@1+ (1,0) [0|3] "" Vector__XXX
 SG_ BatHt : 54|2@1+ (1,0) [0|3] "" Vector__XXX
 SG_ TrvlPdlFail : 52|2@1+ (1,0) [0|3] "" Vector__XXX
 SG_ RrWhlAlgn : 50|2@1+ (1,0) [0|3] "" Vector__XXX
 SG_ PrkBrkPrs : 48|2@1+ (1,0) [0|3] "" Vector__XXX
 SG_ TrsmOilFiltClog : 46|2@1+ (1,0) [0|3] "" Vector__XXX
 SG_ FanMotPrsLw : 44|2@1+ (1,0) [0|3] "" Vector__XXX
 SG_ OvSpd : 42|2@1+ (1,0) [0|3] "" Vector__XXX
 SG_ RBrkPdlNoCalb : 40|2@1+ (1,0) [0|3] "" Vector__XXX
 SG_ ElecStr : 38|2@1+ (1,0) [0|3] "" Vector__XXX
 SG_ EgOvr : 36|2@1+ (1,0) [0|3] "" Vector__XXX
 SG_ EmgStr : 34|2@1+ (1,0) [0|3] "" Vector__XXX
 SG_ SeatBelt : 32|2@1+ (1,0) [0|3] "" Vector__XXX
 SG_ TrsmOilOh : 30|2@1+ (1,0) [0|3] "" Vector__XXX
 SG_ Trsm : 28|2@1+ (1,0) [0|3] "" Vector__XXX
 SG_ VboEpprVvOut : 26|2@1+ (1,0) [0|3] "" Vector__XXX
 SG_ VboJoySs : 24|2@1+ (1,0) [0|3] "" Vector__XXX
 SG_ VboAngSs : 22|2@1+ (1,0) [0|3] "" Vector__XXX
 SG_ BatEq : 20|2@1+ (1,0) [0|3] "" Vector__XXX
 SG_ Uss : 18|2@1+ (1,0) [0|3] "" Vector__XXX
 SG_ IceptSs : 16|2@1+ (1,0) [0|3] "" Vector__XXX
 SG_ Str : 14|2@1+ (1,0) [0|3] "" Vector__XXX
 SG_ BrkOilPrsLw : 12|2@1+ (1,0) [0|3] "" Vector__XXX
 SG_ Ags : 10|2@1+ (1,0) [0|3] "" Vector__XXX
 SG_ Owd : 8|2@1+ (1,0) [0|3] "" Vector__XXX
 SG_ PilotFilt : 6|2@1+ (1,0) [0|3] "" Vector__XXX
 SG_ RetFilt : 4|2@1+ (1,0) [0|3] "" Vector__XXX
 SG_ HydOilOh : 2|2@1+ (1,0) [0|3] "" Vector__XXX
 SG_ BatChg : 0|2@1+ (1,0) [0|3] "" Vector__XXX

BO_ 2566865185 MCU_WSG2: 8 MCU
 SG_ AcleOilOh : 62|2@1+ (1,0) [0|3] "" Vector__XXX
 SG_ TireTemp : 50|2@1+ (1,0) [0|3] "" Vector__XXX
 SG_ FuelEmptyAddFuelTnk : 48|2@1+ (1,0) [0|3] "" Vector__XXX
 SG_ ePowStp : 46|2@1+ (1,0) [0|3] "" Vector__XXX
 SG_ ePowChk : 44|2@1+ (1,0) [0|3] "" Vector__XXX
 SG_ CoolLv : 42|2@1+ (1,0) [0|3] "" Vector__XXX
 SG_ DefPrsLw : 40|2@1+ (1,0) [0|3] "" Vector__XXX
 SG_ WifMainFiltFault : 38|2@1+ (1,0) [0|3] "" Vector__XXX
 SG_ WifMainFiltWaterDetectFault : 36|2@1+ (1,0) [0|3] "" Vector__XXX
 SG_ WifPrePilotFault : 34|2@1+ (1,0) [0|3] "" Vector__XXX
 SG_ WifPrePilot : 32|2@1+ (1,0) [0|3] "" Vector__XXX
 SG_ FuelEmpty : 30|2@1+ (1,0) [0|3] "" Vector__XXX
 SG_ AutoSCrcondPrkns : 28|2@1+ (1,0) [0|3] "" Vector__XXX
 SG_ ExHhTempAmb : 24|2@1+ (1,0) [0|3] "" Vector__XXX
 SG_ ExHhTempGr : 22|2@1+ (1,0) [0|3] "" Vector__XXX
 SG_ DpfActRgnInhbtSt : 20|2@1+ (1,0) [0|3] "" Vector__XXX
 SG_ DpfRgnClg : 18|2@1+ (1,0) [0|3] "" Vector__XXX
 SG_ EgChkSrv : 16|2@1+ (1,0) [0|3] "" Vector__XXX
 SG_ EgChk2 : 14|2@1+ (1,0) [0|3] "" Vector__XXX
 SG_ EgChk1 : 12|2@1+ (1,0) [0|3] "" Vector__XXX
 SG_ EgStp : 10|2@1+ (1,0) [0|3] "" Vector__XXX
 SG_ EgWrn : 8|2@1+ (1,0) [0|3] "" Vector__XXX
 SG_ AirCln : 6|2@1+ (1,0) [0|3] "" Vector__XXX
 SG_ CoolLvSrgTnk : 4|2@1+ (1,0) [0|3] "" Vector__XXX
 SG_ CoolTmpOv : 2|2@1+ (1,0) [0|3] "" Vector__XXX
 SG_ EgOilPrs : 0|2@1+ (1,0) [0|3] "" Vector__XXX

BO_ 2566865441 MCU_WSG3: 8 MCU
 SG_ TirePrs : 48|4@1+ (1,0) [0|15] "" Vector__XXX
 SG_ HydOilWarmUp : 44|4@1+ (1,0) [0|15] "" Vector__XXX
 SG_ GndSawRdy : 40|4@1+ (1,0) [0|15] "" Vector__XXX
 SG_ TrvMotTempOh : 36|4@1+ (1,0) [0|15] "" Vector__XXX
 SG_ QckCouplerLck : 32|4@1+ (1,0) [0|15] "" Vector__XXX
 SG_ BrkPdlSs : 28|4@1+ (1,0) [0|15] "" Vector__XXX
 SG_ AtsRgnReq : 24|4@1+ (1,0) [0|15] "" Vector__XXX
 SG_ TmsConSt : 20|4@1+ (1,0) [0|15] "" Vector__XXX
 SG_ QckCouplerUnlock : 16|4@1+ (1,0) [0|15] "" Vector__XXX
 SG_ RmvCntwt : 12|4@1+ (1,0) [0|15] "" Vector__XXX
 SG_ FuelFilt : 8|4@1+ (1,0) [0|15] "" Vector__XXX
 SG_ UreaQualScr : 4|4@1+ (1,0) [0|15] "" Vector__XXX
 SG_ UreaLv : 0|4@1+ (1,0) [0|15] "" Vector__XXX

BO_ 2566865697 MCU_SIG1: 8 MCU
 SG_ BzzCtrlCmd : 62|2@1+ (1,0) [0|3] "" Vector__XXX
 SG_ CurGr : 59|3@1+ (1,0) [0|7] "" Vector__XXX
 SG_ SelGr : 56|3@1+ (1,0) [0|7] "" Vector__XXX
 SG_ BoomFltBiDir : 55|1@1+ (1,0) [0|1] "" Vector__XXX
 SG_ Is3RdFNRElecStr : 54|1@1+ (1,0) [0|1] "" Vector__XXX
 SG_ IsFR : 53|1@1+ (1,0) [0|1] "" Vector__XXX
 SG_ IsElecStr : 52|1@1+ (1,0) [0|1] "" Vector__XXX
 SG_ IsOprRdy : 50|2@1+ (1,0) [0|3] "" Vector__XXX
 SG_ PreHt : 48|2@1+ (1,0) [0|3] "" Vector__XXX
 SG_ FaultCntAvm : 46|2@1+ (1,0) [0|3] "" Vector__XXX
 SG_ FaultCntMch : 44|2@1+ (1,0) [0|3] "" Vector__XXX
 SG_ CtrWrnLed : 43|1@1+ (1,0) [0|1] "" Vector__XXX
 SG_ ExBzz : 42|1@1+ (1,0) [0|1] "" Vector__XXX
 SG_ AutoShdnAval : 41|1@1+ (1,0) [0|1] "" Vector__XXX
 SG_ AutoShdnSt : 40|1@1+ (1,0) [0|1] "" Vector__XXX
 SG_ BrkrAct : 38|2@1+ (1,0) [0|3] "" Vector__XXX
 SG_ ThmbWhlLvErr : 37|1@1+ (1,0) [0|1] "" Vector__XXX
 SG_ AutoIdle : 36|1@1+ (1,0) [0|1] "" Vector__XXX
 SG_ RgnPrkns : 35|1@1+ (1,0) [0|1] "" Vector__XXX
 SG_ RpmCtrlRstrt : 34|1@1+ (1,0) [0|1] "" Vector__XXX
 SG_ IgnRstrtPilotCutOff : 33|1@1+ (1,0) [0|1] "" Vector__XXX
 SG_ IgnRstrtFRP : 32|1@1+ (1,0) [0|1] "" Vector__XXX
 SG_ OhPrv : 30|2@1+ (1,0) [0|3] "" Vector__XXX
 SG_ HhMntLgc : 28|2@1+ (1,0) [0|3] "" Vector__XXX
 SG_ AutoShdn : 27|1@1+ (1,0) [0|1] "" Vector__XXX
 SG_ FuelHt : 26|1@1+ (1,0) [0|1] "" Vector__XXX
 SG_ AutoWarmUpGr : 25|1@1+ (1,0) [0|1] "" Vector__XXX
 SG_ AutoWarmUpAmb : 24|1@1+ (1,0) [0|1] "" Vector__XXX
 SG_ HhBeam : 23|1@1+ (1,0) [0|1] "" Vector__XXX
 SG_ RamLck : 22|1@1+ (1,0) [0|1] "" Vector__XXX
 SG_ PrkBrk : 21|1@1+ (1,0) [0|1] "" Vector__XXX
 SG_ Trv : 20|1@1+ (1,0) [0|1] "" Vector__XXX
 SG_ FNR : 18|2@1+ (1,0) [0|3] "" Vector__XXX
 SG_ TrvMdWhl : 16|2@1+ (1,0) [0|3] "" Vector__XXX
 SG_ IsoBhl : 14|2@1+ (1,0) [0|3] "" Vector__XXX
 SG_ TwOpt : 12|2@1+ (1,0) [0|3] "" Vector__XXX
 SG_ WrkMd : 10|2@1+ (1,0) [0|3] "" Vector__XXX
 SG_ TrvMdCrw : 8|2@1+ (1,0) [0|3] "" Vector__XXX
 SG_ MrrHt : 7|1@1+ (1,0) [0|1] "" Vector__XXX
 SG_ AuxMdSt : 6|1@1+ (1,0) [0|1] "" Vector__XXX
 SG_ RvsFanSt : 5|1@1+ (1,0) [0|1] "" Vector__XXX
 SG_ SwPriSt : 4|1@1+ (1,0) [0|1] "" Vector__XXX
 SG_ BoomSwAct : 3|1@1+ (1,0) [0|1] "" Vector__XXX
 SG_ BoomFltSngDir : 2|1@1+ (1,0) [0|1] "" Vector__XXX
 SG_ PowMax : 1|1@1+ (1,0) [0|1] "" Vector__XXX
 SG_ WrkLmp : 0|1@1+ (1,0) [0|1] "" Vector__XXX

BO_ 2566865953 MCU_SIG2: 8 MCU
 SG_ HstTractionLvSel : 63|1@1+ (1,0) [0|1] "" Vector__XXX
 SG_ FltHold : 62|1@1+ (1,0) [0|1] "" Vector__XXX
 SG_ Adb : 60|2@1+ (1,0) [0|3] "" Vector__XXX
 SG_ Cruise : 59|1@1+ (1,0) [0|1] "" Vector__XXX
 SG_ WhlDrvMd : 57|2@1+ (1,0) [0|3] "" Vector__XXX
 SG_ DesMchShtDn : 56|1@1+ (1,0) [0|1] "" Vector__XXX
 SG_ FrcRgnStp : 55|1@1+ (1,0) [0|1] "" Vector__XXX
 SG_ FrcRgnScs : 54|1@1+ (1,0) [0|1] "" Vector__XXX
 SG_ WghCnt : 53|1@1+ (1,0) [0|1] "" Vector__XXX
 SG_ MapCreateProg : 48|5@1+ (1,0) [0|31] "" Vector__XXX
 SG_ AngSsTunReq : 47|1@1+ (1,0) [0|1] "" Vector__XXX
 SG_ ZeroCalbReq : 46|1@1+ (1,0) [0|1] "" Vector__XXX
 SG_ WarmUp : 45|1@1+ (1,0) [0|1] "" Vector__XXX
 SG_ MapCreatReady : 44|1@1+ (1,0) [0|1] "" Vector__XXX
 SG_ ColdStart : 40|4@1+ (1,0) [0|15] "" Vector__XXX
 SG_ WghTooHv : 38|1@1+ (1,0) [0|1] "" Vector__XXX
 SG_ WghPoorLft : 37|1@1+ (1,0) [0|1] "" Vector__XXX
 SG_ WghStartPosHh : 36|1@1+ (1,0) [0|1] "" Vector__XXX
 SG_ WghSpdBuc : 35|1@1+ (1,0) [0|1] "" Vector__XXX
 SG_ WghUnderSpd : 34|1@1+ (1,0) [0|1] "" Vector__XXX
 SG_ RrDefst : 33|1@1+ (1,0) [0|1] "" Vector__XXX
 SG_ EmgMd : 32|1@1+ (1,0) [0|1] "" Vector__XXX
 SG_ OprMd : 30|2@1+ (1,0) [0|3] "" Vector__XXX
 SG_ OprPowMd : 26|4@1+ (1,0) [0|15] "" Vector__XXX
 SG_ HstMdWld : 24|2@1+ (1,0) [0|3] "" Vector__XXX
 SG_ CCO : 23|1@1+ (1,0) [0|250] "min" Vector__XXX
 SG_ TrqCvt : 22|1@1+ (1,0) [0|250] "min" Vector__XXX
 SG_ TrvMdWld : 20|2@1+ (1,0) [0|3] "" Vector__XXX
 SG_ Creep : 19|1@1+ (1,0) [0|250] "min" Vector__XXX
 SG_ ThrtLck : 18|1@1+ (1,0) [0|250] "min" Vector__XXX
 SG_ Dhl : 17|1@1+ (1,0) [0|250] "min" Vector__XXX
 SG_ LisSw : 16|1@1+ (1,0) [0|250] "min" Vector__XXX
 SG_ CoolDrtTm : 8|8@1+ (1,0) [0|250] "min" Vector__XXX
 SG_ WifDrtTm : 0|8@1+ (1,0) [0|250] "min" Vector__XXX

BO_ 2566866179 TCU_ZFETC9: 8 TCU

BO_ 2566866209 MCU_GPG: 8 MCU

BO_ 2566866465 MCU_UPD: 8 MCU

BO_ 2566866721 MCU_SIG3: 8 MCU
 SG_ DifActlTrgGrdt : 63|1@1+ (1,0) [0|1] "" Vector__XXX
 SG_ OprPrsntSt : 62|1@1+ (1,0) [0|1] "" Vector__XXX
 SG_ HydCutOffRls : 61|1@1+ (1,0) [0|1] "" Vector__XXX
 SG_ ChgErr : 60|1@1+ (1,0) [0|1] "" Vector__XXX
 SG_ ChgSt : 58|2@1+ (1,0) [0|3] "" Vector__XXX
 SG_ WrkTrv : 56|2@1+ (1,0) [0|3] "" Vector__XXX
 SG_ BatLw : 55|1@1+ (1,0) [0|1] "" Vector__XXX
 SG_ HydLck : 54|1@1+ (1,0) [0|1] "" Vector__XXX
 SG_ HillDscntCtrlSt : 52|1@1+ (1,0) [0|1] "" Vector__XXX
 SG_ OprPrsnc : 51|1@1+ (1,0) [0|1] "" Vector__XXX
 SG_ BckDust : 50|1@1+ (1,0) [0|1] "" Vector__XXX
 SG_ BmsPrhtLmp : 48|2@1+ (1,0) [0|3] "" Vector__XXX
 SG_ DacSt : 45|3@1+ (1,0) [0|7] "" Vector__XXX
 SG_ EmcvFngrtpLvrErr : 44|1@1+ (1,0) [0|1] "" Vector__XXX
 SG_ IllminSt : 40|2@1+ (1,0) [0|3] "" Vector__XXX
 SG_ ChmslSt : 36|4@1+ (1,0) [0|15] "" Vector__XXX
 SG_ CdsFanRvsSt : 35|1@1+ (1,0) [0|1] "" Vector__XXX
 SG_ CacFanRvsSt : 34|1@1+ (1,0) [0|1] "" Vector__XXX
 SG_ WrnGndSlop : 29|1@1+ (1,0) [0|1] "" Vector__XXX
 SG_ WrnOilTmpLw : 28|1@1+ (1,0) [0|1] "" Vector__XXX
 SG_ AttOpr : 23|1@1+ (1,0) [0|1] "" Vector__XXX
 SG_ WrnLimpHome : 19|1@1+ (1,0) [0|1] "" Vector__XXX
 SG_ MchCond : 16|2@1+ (1,0) [0|3] "" Vector__XXX
 SG_ WrnRollOvr : 14|2@1+ (1,0) [0|3] "" Vector__XXX
 SG_ WrnArmPosOnDrv : 13|1@1+ (1,0) [0|1] "" Vector__XXX
 SG_ WrnThmbWhlStrShft : 12|1@1+ (1,0) [0|1] "" Vector__XXX
 SG_ WrnRamLck : 10|2@1+ (1,0) [0|3] "" Vector__XXX
 SG_ WrnHstOilFilt : 9|1@1+ (1,0) [0|1] "" Vector__XXX
 SG_ WrnGrBoxOvTmp : 8|1@1+ (1,0) [0|1] "" Vector__XXX
 SG_ VhcStTractionLv : 6|2@1+ (1,0) [0|3] "" Vector__XXX
 SG_ WhlLis : 4|2@1+ (1,0) [0|3] "" Vector__XXX
 SG_ WhlDzTrlHitch : 3|1@1+ (1,0) [0|1] "" Vector__XXX
 SG_ WhlSwgAlign : 2|1@1+ (1,0) [0|1] "" Vector__XXX
 SG_ WhlRamLckAuto : 0|2@1+ (1,0) [0|3] "" Vector__XXX

CM_ BO_ 3221225472 "This is a message for not used signals, created by Vector CANdb++ DBC OLE DB Provider.";
CM_ SG_ 3221225472 KnmtVcstyofEgOil "Kinematic Viscosity of Engine Oil";
CM_ SG_ 3221225472 KnmtVcstyofHyhOil "Kinematic Viscosity of Hydraulic Oil";
CM_ SG_ 3221225472 LwThKnmtVcstyofEgOil "Lower Threshold Kinematic Viscosity of Engine Oil";
CM_ SG_ 3221225472 UpThKnmtVcstyofEgOil "Upper Threshold Kinematic Viscosity of Engine Oil";
CM_ SG_ 3221225472 LwThDielecCstofEgOil "Lower Threshold Dieletric Constant of Engine Oil";
CM_ SG_ 3221225472 UpThDielecCstofEgOil "Upper Threshold Dieletric Constant of Engine Oil";
CM_ SG_ 3221225472 LwThKnmtVcstyofHyhOil "Lower Threshold Kinematic Viscosity of Hydraulic Oil";
CM_ SG_ 3221225472 UpThKnmtVcstyofHyhOil "Upper Threshold Kinematic Viscosity of Hydraulic Oil";
CM_ SG_ 3221225472 LwThDielecCstofHyhOil "Lower Threshold Dieletric Constant of Hydraulic Oil";
CM_ SG_ 3221225472 UpThDielecCstofHyhOil "Upper Threshold Dieletric Constant of Hydraulic Oil";
CM_ SG_ 3221225472 WarnPopHyhOilQual "Warning Pop-up; PHM - Hydraulic Oil Quality ";
CM_ SG_ 3221225472 WarnPopEgOilQual "Warning Pop-up; PHM - Engine Oil Quality ";
CM_ SG_ 3221225472 SwVer "Terminal Application Version";
CM_ SG_ 3221225472 KnlVer "Terminal Kernel Version";
CM_ SG_ 3221225472 ProdDate "Production Date";
CM_ SG_ 3221225472 TGUId "TerminalSerialNumber";
CM_ SG_ 3221225472 TypeCd "TerminalTypeCode";
CM_ BO_ 2583662767 "PHM Warning Group";
CM_ SG_ 2583662767 WarnPopEgOilQual "Warning Pop-up; PHM - Engine Oil Quality ";
CM_ SG_ 2583662767 WarnPopHyhOilQual "Warning Pop-up; PHM - Hydraulic Oil Quality ";
CM_ BO_ 2565818920 "GP Setting Message to TMS";
CM_ BO_ 2565844776 "GP Setting Message to TMS";
CM_ BO_ 2348810243 "Torque/Speed Control 1";
CM_ SG_ 2348810243 EgReqTrqTrqLmt "EngineRequestedTorque/TorqueLimit";
CM_ SG_ 2348810243 EgReqSpdSpdLmt "EngineRequestedSpeed/SpeedLimit";
CM_ SG_ 2348810243 OvrCtrlMdPri "OverrideControlModePriority";
CM_ SG_ 2348810243 EgOvrCtrlMd "EngineOverrideControlMode";
CM_ BO_ 2348810251 "Torque/Speed Control 1";
CM_ SG_ 2348810251 EgReqTrqTrqLmt "EngineRequestedTorque/TorqueLimit";
CM_ SG_ 2348810251 EgReqSpdSpdLmt "EngineRequestedSpeed/SpeedLimit";
CM_ SG_ 2348810251 OvrCtrlMdPri "OverrideControlModePriority";
CM_ SG_ 2348810251 EgOvrCtrlMd "EngineOverrideControlMode";
CM_ BO_ 2348810259 "Torque/Speed Control 1";
CM_ SG_ 2348810259 EgReqTrqTrqLmt "EngineRequestedTorque/TorqueLimit";
CM_ SG_ 2348810259 EgReqSpdSpdLmt "EngineRequestedSpeed/SpeedLimit";
CM_ SG_ 2348810259 OvrCtrlMdPri "OverrideControlModePriority";
CM_ SG_ 2348810259 EgOvrCtrlMd "EngineOverrideControlMode";
CM_ BO_ 2348810273 "Torque/Speed Control 1";
CM_ SG_ 2348810273 EgReqTrqTrqLmt "EngineRequestedTorque/TorqueLimit";
CM_ SG_ 2348810273 EgReqSpdSpdLmt "EngineRequestedSpeed/SpeedLimit";
CM_ SG_ 2348810273 OvrCtrlMdPri "OverrideControlModePriority";
CM_ SG_ 2348810273 EgOvrCtrlMd "EngineOverrideControlMode";
CM_ BO_ 2348814083 "Torque/Speed Control 1";
CM_ BO_ 2348814091 "Torque/Speed Control 1";
CM_ BO_ 2348814096 "Torque? Speed Control receive message from Adaptive cruise control unit to retarder";
CM_ BO_ 2348814099 "Torque? Speed Control receive message from Adaptive cruise control unit to retarder";
CM_ BO_ 2348814113 "Torque/Speed Control 1";
CM_ BO_ 2350579745 "High Voltage Energy Storage System Control 1";
CM_ BO_ 2351300641 "Motor/Generator 1 Inverter Control";
CM_ BO_ 2564816912 "Cab Message 1";
CM_ SG_ 2564816912 AtRgnFrcSw "AftertreatmentRegenerationForceSwitch";
CM_ SG_ 2564816912 AtRgnInhbSw "AftertreatmentRegenerationInhibitSwitch";
CM_ BO_ 2564816929 "Cab Message 1";
CM_ SG_ 2564816929 AtRgnFrcSw "AftertreatmentRegenerationForceSwitch";
CM_ SG_ 2564816929 AtRgnInhbSw "AftertreatmentRegenerationInhibitSwitch";
CM_ BO_ 2565800744 "GP Setting Message to TCU";
CM_ BO_ 2364478241 "Man Machine Interface � Primary";
CM_ BO_ 2565805864 "GP Setting Message to Cluster";
CM_ BO_ 2565808424 "GP Setting Message to VCU";
CM_ BO_ 2565808458 "VCU Setting Message  From TMS";
CM_ BO_ 2565810241 "Gateway Setting Message to GP";
CM_ BO_ 2565810250 "GP Setting Message  From TMS";
CM_ BO_ 2565810256 "Keypad Setting Message to GP";
CM_ BO_ 2565816616 "GP Setting Message to Gateway";
CM_ BO_ 2565827112 "GP Setting Message to TMS";
CM_ BO_ 2565820456 "GP Setting Message to Keypad";
CM_ BO_ 2565821480 "GP Setting Message to AVM";
CM_ BO_ 2565821505 "Gateway Setting Message to AVM";
CM_ BO_ 2364496417 "Man Machine Interface � Secondary";
CM_ BO_ 2565865487 "Electronic Retarder Controller 1";
CM_ BO_ 2565865488 "Electronic Retarder Controller 1";
CM_ BO_ 2565865733 "EBC1";
CM_ SG_ 2565865733 EgAuxShdnSw "EngineAuxiliaryShutdownSwitch";
CM_ BO_ 2565865739 "Electronic Brake Controller 1";
CM_ SG_ 2565865739 EgAuxShdnSw "EngineAuxiliaryShutdownSwitch";
CM_ BO_ 2364539395 "Electronic Transmission Controller 1";
CM_ SG_ 2364539395 TrmInShftSpd "TransInputShaftSpeed";
CM_ SG_ 2364539395 TrmsOutShftSpd "Transmission1OutputShaftSpeed";
CM_ SG_ 2364539395 InProTrmShft "TransShiftInProcess";
CM_ SG_ 2364539395 TrqCvtLckEng "TorqueConverterLockupEngaged";
CM_ SG_ 2364539395 TrmDrvEng "TransDrivelineEngaged";
CM_ BO_ 2364539648 "Electronic Engine Controller 2";
CM_ SG_ 2364539648 AccPdlPos2 "AcceleratorPedalPosition2";
CM_ SG_ 2364539648 EgPctLoadCurSpd "EnginePercentLoadAtCurrentSpeed";
CM_ SG_ 2364539648 AccPdlPos1 "AcceleratorPedalPosition1";
CM_ BO_ 2364539904 "Electronic Engine Controller 1";
CM_ SG_ 2364539904 EgSpd "EngineSpeed";
CM_ SG_ 2364539904 ActEgPctTrq "ActualEngine-PercentTorque";
CM_ SG_ 2364539904 DrvDmdEgPctTrq "Driver'sDemandEngine-PercentTorque";
CM_ BO_ 2565866755 "ETC2";
CM_ SG_ 2565866755 TrmsCurGr "TransCurrentGear";
CM_ SG_ 2565866755 TrmsActGrRatio "TransActualGearRatio";
CM_ SG_ 2565866755 TrmsSelGr "TransSelectedGear";
CM_ BO_ 2565867011 "EAC1";
CM_ SG_ 2565867011 DifLckStCtrEng "DiffLockStateCentral";
CM_ BO_ 2364542241 "Land levelling system operational information";
CM_ SG_ 2364542241 BladeAutoMdCmd "BladeAutoModeCommand";
CM_ SG_ 2364542241 DsrGrdOfsSw "DesiredGradeOffsetSwitch";
CM_ SG_ 2364542241 BladeCtrlMdSw "BladeControlModeSwitch";
CM_ BO_ 2565869137 "Aftertreatment 1 Intake Gas 1";
CM_ SG_ 2565869137 AtIntGasSsHtCtrl "Aftertreatment1IntakeGasSensorHeaterControl";
CM_ SG_ 2565869137 InRngAtIntGasSsTmp "Aftertreatment1IntakeGasSensoratTemperature";
CM_ BO_ 2565869394 "Aftertreatment 1 Outlet Gas 1";
CM_ SG_ 2565869394 AtOutGasSsHtCtrl "Aftertreatment1OutletGasSensorHeaterControl";
CM_ SG_ 2565869394 InRngAtOutGasSsTmp "Aftertreatment1OutletGasSensoratTemperature";
CM_ BO_ 2565875998 "Slope Sensor Information 2";
CM_ BO_ 2565876161 "Slope Sensor Information 2";
CM_ BO_ 2565876162 "Slope Sensor Information 2";
CM_ BO_ 2565876163 "Slope Sensor Information 2";
CM_ BO_ 2565876164 "Slope Sensor Information 2";
CM_ BO_ 2565876165 "Slope Sensor Information 2";
CM_ BO_ 2364575987 "High Voltage Energy Storage System Data 1";
CM_ BO_ 2364576243 "High Voltage Energy Storage System Data 2";
CM_ BO_ 2364576755 "High Voltage Energy Storage System Data 4";
CM_ BO_ 2364577011 "High Voltage Energy Storage System Data 5";
CM_ BO_ 2364577267 "High Voltage Energy Storage System Data 6";
CM_ BO_ 2364637584 "Motor/Generator 1 Inverter Mode Feedback 1";
CM_ BO_ 2364641057 "PG Impostor Alert Message";
CM_ BO_ 2364641267 "PG Impostor Alert Message";
CM_ BO_ 2365288848 "Motor/Generator 1 Inverter Motor Temperature";
CM_ BO_ 2365289104 "Motor/Generator 1 Inverter Temperature";
CM_ BO_ 2365289360 "Motor/Generator 1 Inverter Reference 2";
CM_ BO_ 2365289616 "Motor/Generator 1 Inverter Status 1";
CM_ BO_ 2566675955 "High Voltage Energy Storage System Configuration";
CM_ BO_ 2633785075 "High Voltage Energy Storage System History";
CM_ BO_ 2566709248 "Diesel Particulate Filter Control 2";
CM_ BO_ 2633828415 "Oil Quality Message 1";
CM_ SG_ 2633828415 Oildieleccst "Oil dielectric constant";
CM_ SG_ 2633828415 Oildensity "Oil density";
CM_ SG_ 2633828415 OilVcsty "Oil viscosity";
CM_ BO_ 2633828526 "Oil Quality Message 1";
CM_ SG_ 2633828526 Oildieleccst "Oil dielectric constant";
CM_ SG_ 2633828526 Oildensity "Oil density";
CM_ SG_ 2633828526 OilVcsty "Oil viscosity";
CM_ BO_ 2566719744 "High Resolution Fuel Consumption (Liquid)";
CM_ BO_ 2365394514 "Aftertreatment 1 Outlet Gas NOx Sensor Correction Data 2";
CM_ BO_ 2365394770 "Aftertreatment 1 Outlet Gas NOx Sensor Correction Data 1";
CM_ BO_ 2365395025 "Aftertreatment 1 Intake Gas NOx Sensor Correction Data 2";
CM_ BO_ 2365395281 "Aftertreatment 1 Intake Gas NOx Sensor Correction Data 1";
CM_ BO_ 2566722989 "Battery Charger 1";
CM_ BO_ 2566725632 "Aftertreatment 1 Diesel Oxidation Catalyst";
CM_ BO_ 2566748928 "Aftertreatment 1 Outlet Gas 2";
CM_ SG_ 2566748928 DpfSootLoadPct "DieselParticulateFilter1SootLoadPercent";
CM_ BO_ 2566749184 "Diesel Particulate Filter Control 1";
CM_ SG_ 2566749184 ExhHhTmpLmpCmd "ExhaustSystemHighTemperatureLampCommand";
CM_ SG_ 2566749184 DpfActRgnIhbSw "DieselParticulateFilterActiveRegenerationInhibitedDuetoInhibitSwitch";
CM_ SG_ 2566749184 DpfActRgnSt "DieselParticulateFilterActiveRegenerationStatus";
CM_ SG_ 2566749184 DpfFiltLmpCmd "DieselParticulateFilterLampCommand";
CM_ BO_ 2566755587 "TRF2";
CM_ SG_ 2566755587 TrqCvtOilOutTmp "TRF2TrqueConverterOilOutletTemp";
CM_ SG_ 2566755587 TrmOilFiltRstrSw "TRF2TrmOilFilterRestrictSwitch";
CM_ BO_ 2566757120 "Aftertreatment 1 Diesel Exhaust Fluid Information 1";
CM_ SG_ 2566757120 AtDefPpt "Aftertreatment1DieselExhaustFluidProperty";
CM_ SG_ 2566757120 AtDefCct "Aftertreatment1DieselExhaustFluidConcentration";
CM_ BO_ 2566758656 "Aftertreatment1 Fuelcontrol Frame1";
CM_ SG_ 2566758656 AtFuelInjHtCtrl "Aftertreatment1FuelInjector1HeaterControl";
CM_ SG_ 2566758656 AtIgn "Aftertreatment1Ignition";
CM_ SG_ 2566758656 AtFuelPrsCtrl "Aftertreatment1FuelPressure1Control";
CM_ SG_ 2566758656 AtFuelRate "Aftertreatment1FuelRate";
CM_ SG_ 2566758656 AtFuelPrs "Aftertreatment1FuelPressure1";
CM_ BO_ 2566763008 "Aftertreatment 1 Intermediate Gas";
CM_ BO_ 2566763264 "Aftertreatment 1 Outlet Gas 2";
CM_ SG_ 2566763264 AtDpfOutGasTmp "Aftertreatment1DieselParticulateFilterOutletGasTemperature";
CM_ BO_ 2566763325 "Aftertreatment 1 Outlet Gas 2";
CM_ SG_ 2566763325 AtDpfOutGasTmp "Aftertreatment1DieselParticulateFilterOutletGasTemperature";
CM_ BO_ 2566763520 "Aftertreatment 1 Intake Gas 2";
CM_ SG_ 2566763520 AtDpfIntGasTmp "Aftertreatment1DieselParticulateFilterIntakeGasTemperature";
CM_ SG_ 2566763520 AtExhGasTmp "Aftertreatment1ExhaustGasTemperature1";
CM_ BO_ 2566763581 "Aftertreatment 1 Intake Gas 2";
CM_ SG_ 2566763581 AtDpfIntGasTmp "Aftertreatment1DieselParticulateFilterIntakeGasTemperature";
CM_ SG_ 2566763581 AtExhGasTmp "Aftertreatment1ExhaustGasTemperature1";
CM_ BO_ 2365441523 "PG engcon AGW ECU Identification Information";
CM_ BO_ 2566769997 "Operator Wiper and Washer Controls Message";
CM_ BO_ 2566771968 "Electronic Engine Controller 5";
CM_ SG_ 2566771968 EgEgrVvCtrl "EngineExhaustGasRecirculation1(EGR1)ValveControl";
CM_ BO_ 2365445841 "Basic Joystick Message 1";
CM_ BO_ 2365446097 "Extended Joystick Message 1";
CM_ BO_ 2365446352 "Basic Joystick Message 2";
CM_ BO_ 2365446608 "Extended Joystick Message 2";
CM_ BO_ 2365446893 "Basic Joystick Message 3";
CM_ BO_ 2365446894 "Basic Joystick Message 3";
CM_ BO_ 2365446895 "Basic Joystick Message 3";
CM_ BO_ 2365446896 "Basic Joystick Message 3";
CM_ BO_ 2365468962 "Auxiliary Valve Number 1 Command";
CM_ SG_ 2365468962 PortFlowHighResolution "PortFlow(HighResolution)";
CM_ SG_ 2365468962 FailSafeMd "FailSafeMode";
CM_ SG_ 2365468962 VvSt "ValveState";
CM_ SG_ 2365468962 ResolutionMd "ResolutionMode";
CM_ SG_ 2365468962 AuxVv1PortFlowCmd "AuxValve1PortFlowCommand";
CM_ BO_ 2365469218 "Auxiliary Valve Number 2 Command";
CM_ SG_ 2365469218 PortFlowHighResolution "PortFlow(HighResolution)";
CM_ SG_ 2365469218 FailSafeMd "FailSafeMode";
CM_ SG_ 2365469218 VvSt "ValveState";
CM_ SG_ 2365469218 ResolutionMd "ResolutionMode";
CM_ SG_ 2365469218 AuxVv1PortFlowCmd "AuxValve1PortFlowCommand";
CM_ BO_ 2365473101 "Lighting Command";
CM_ BO_ 2566801441 "Wheel-based Speed and Distance";
CM_ BO_ 2566801923 "Electronic Transmission Controller 7";
CM_ BO_ 2566802176 "Transmission Configuration 2";
CM_ SG_ 2566802176 EgThrtActCtrlCmd "EngineThrottleActuator1ControlCommand";
CM_ BO_ 2566803211 "Vehicle Dynamic Stability Control 1";
CM_ BO_ 2566804992 "Aftertreatment 1 Diesel Exhaust Fluid Tank 1 Information 1";
CM_ SG_ 2566804992 AtSelCatalRedOprIndAct "AftertreatmentSelectiveCatalyticReductionOperatorInducementActive";
CM_ SG_ 2566804992 AtDefTnkTmp "Aftertreatment1DieselExhaustFluidTankTemperature";
CM_ SG_ 2566804992 AtDefTnkLv "Aftertreatment1DieselExhaustFluidTankLevel";
CM_ BO_ 2566804993 "Aftertreatment 1 Diesel Exhaust Fluid Tank 1 Information 1";
CM_ SG_ 2566804993 AtSelCatalRedOprIndAct "AftertreatmentSelectiveCatalyticReductionOperatorInducementActive";
CM_ SG_ 2566804993 AtDefTnkTmp "Aftertreatment1DieselExhaustFluidTankTemperature";
CM_ SG_ 2566804993 AtDefTnkLv "Aftertreatment1DieselExhaustFluidTankLevel";
CM_ BO_ 2365484270 "Tachograph";
CM_ BO_ 2566811147 "High Resolution Wheel Speed";
CM_ BO_ 2633927682 "Auxiliary Analog Information";
CM_ BO_ 2566831360 "Fan Drive #1";
CM_ BO_ 2566831616 "Electronic Engine Controller 4";
CM_ BO_ 2566831883 "Wheel Speed Information";
CM_ BO_ 2566832622 "High Resolution Vehicle Distance";
CM_ BO_ 2566834749 "Active Diagnostic Trouble Codes";
CM_ BO_ 2566834944 "Previously Active Diagnostic Trouble Codes";
CM_ BO_ 2566835456 "Freeze Frame Parameters";
CM_ BO_ 2566835712 "Diagnostic Readiness 1";
CM_ BO_ 2566835968 "Pending DTCs ";
CM_ BO_ 2566838528 "Auxiliary Input/Output Status 1";
CM_ BO_ 2566838784 "Software Identification";
CM_ BO_ 2566838787 "Software Identification";
CM_ BO_ 2365512435 "Software Identification";
CM_ BO_ 2566839296 "Idle Operation";
CM_ BO_ 2566840064 "Electronic Engine Controller 3";
CM_ SG_ 2566840064 At1ExhGasMasFlw "Aftertreatment1ExhaustGasMassFlow";
CM_ SG_ 2566840064 EgDsrOprSpd "Engine'sDesiredOperatingSpeed";
CM_ SG_ 2566840064 NrmFricPctTrq "NominalFriction-PercentTorque";
CM_ BO_ 2566841344 "Shutdown";
CM_ BO_ 2566841600 "Engine Hours, Revolutions";
CM_ SG_ 2566841600 EgTotRev "EngineTotalRevolutions";
CM_ SG_ 2566841600 EgTotHrOpr "EngineTotalHoursofOperation";
CM_ BO_ 2566841879 "Time/Date";
CM_ BO_ 2566842094 "Time/Date";
CM_ BO_ 2566842112 "Vehicle Electrical Power 1";
CM_ BO_ 2566842624 "Fuel Consumption (Liquid) 1";
CM_ SG_ 2566842624 EgTotFuelUsed "EngineTotalFuelUsed";
CM_ SG_ 2566842624 EgTripFuel "EngineTripFuel";
CM_ BO_ 2566843136 "Component Identification";
CM_ BO_ 2566843392 "Vehicle Identification";
CM_ BO_ 2566843648 "Cruise Control/Vehicle Speed Setup";
CM_ BO_ 2566843651 "Cruise Control/Vehicle Speed Setup";
CM_ BO_ 2566843653 "Cruise Control/Vehicle Speed Setup";
CM_ BO_ 2566843904 "Engine Temperature 1";
CM_ SG_ 2566843904 EgFuelTmp "EngineFuelTemperature1";
CM_ SG_ 2566843904 EgCoolTmp "EngineCoolantTemperature";
CM_ BO_ 2566843967 "Oil Temperature";
CM_ SG_ 2566843967 OilAvrgTmp "Oil average temperature";
CM_ BO_ 2566844078 "Oil Temperature";
CM_ SG_ 2566844078 OilAvrgTmp "Oil average temperature";
CM_ BO_ 2566844160 "Engine Fluid Level/Pressure 1";
CM_ SG_ 2566844160 EgCoolLv "EngineCoolantLevel";
CM_ SG_ 2566844160 EgCrkcasePrs "EngineCrankcasePressure";
CM_ SG_ 2566844160 EgOilPrs "EngineOilPressure";
CM_ SG_ 2566844160 EgFuelDlvPrs "EngineFuelDeliveryPressure";
CM_ BO_ 2566844672 "Cruise Control/Vehicle Speed 1";
CM_ SG_ 2566844672 WhlVhcSpd "WheelBasedVehicleSpeed";
CM_ BO_ 2566844675 "Cruise Control/Vehicle Speed 1";
CM_ SG_ 2566844675 WhlVhcSpd "WheelBasedVehicleSpeed";
CM_ BO_ 2566844705 "Cruise Control/Vehicle Speed 1";
CM_ SG_ 2566844705 WhlVhcSpd "WheelBasedVehicleSpeed";
CM_ BO_ 2566844928 "Fuel Economy";
CM_ SG_ 2566844928 EgThrtVvPos "EngineThrottleValve1Position";
CM_ SG_ 2566844928 EgFuelRate "EngineFuelRate";
CM_ BO_ 2566845696 "Ambient Conditions";
CM_ SG_ 2566845696 EgAirIntTmp "EngineAirIntakeTemperature";
CM_ SG_ 2566845696 AmbAirTmp "AmbientAirTemperature";
CM_ SG_ 2566845696 BaroPrs "BarometricPressure";
CM_ BO_ 2566845952 "Intake/Exhaust Conditions 1";
CM_ SG_ 2566845952 EgAirIntPrs "EngineAirIntakePressure";
CM_ SG_ 2566845952 EgIntMnfdTmp "EngineIntakeManifold1Temperature";
CM_ SG_ 2566845952 EgIntMnfdPrs "EngineIntakeManifold#1Pressure";
CM_ BO_ 2566846208 "Vehicle Electrical Power 1";
CM_ SG_ 2566846208 KeyswBatPtc "KeyswitchBatteryPotential";
CM_ SG_ 2566846208 BatPtcPowIn "BatteryPotential/PowerInput1";
CM_ BO_ 2566846467 "Transmission Fluids 1";
CM_ BO_ 2566846981 "Brakes 1";
CM_ BO_ 2566847235 "Retarder fluids";
CM_ SG_ 2566847235 TrmOilFiltRstrSw "TRF2TrmOilFilterRestrictSwitch";
CM_ BO_ 2566847511 "Dash Display 1";
CM_ BO_ 2566847521 "Dash Display 1";
CM_ BO_ 2566848256 "Operator indicators";
CM_ BO_ 2566849085 "Send message Exhaust Gas Sensor for Particulate Matter";
CM_ BO_ 2566851074 "Receiving and evaluating the ACTVCODE frame";
CM_ BO_ 2566852897 "Safety Message VCU";
CM_ SG_ 2566852897 MsgCs "MessageChecksum";
CM_ SG_ 2566852897 MsgCnt "MessageCounter";
CM_ SG_ 2566852897 PrkBrkSw "ParkingBrakeSwitch";
CM_ SG_ 2566852897 StartCtrlReq "StarterControlRequest";
CM_ SG_ 2566852897 VhcSpd "VehicleSpeed";
CM_ SG_ 2566852897 CCAccSw "CruiseControlAccelerateSwitch";
CM_ SG_ 2566852897 CCRsmSw "CruiseControlResumeSwitch";
CM_ SG_ 2566852897 CCCoastSw "CruiseControlCoast(Decelerate)Switch";
CM_ SG_ 2566852897 CCSetSw "CruiseControlSetSwitch";
CM_ SG_ 2566852897 PtoSt "PTOstate";
CM_ SG_ 2566852897 RddtBrk "RedundantBreak";
CM_ SG_ 2566852897 BrkSw "BrakeSwitch";
CM_ SG_ 2566852897 LisSw "LISSwitch";
CM_ SG_ 2566852897 FinAccPdlPos "FinalAcceleratorPedalPostion";
CM_ BO_ 2365527585 "Auxiliary Steering Device (Joystick) - Primary";
CM_ SG_ 2365527585 Crc16forDtbytes "CRC16fordatabytes(1~6)";
CM_ SG_ 2365527585 Errorcode "Errorcode";
CM_ SG_ 2365527585 SequenceNo "Sequencenumber";
CM_ SG_ 2365527585 JoyEnbsignal "JoystickEnablesignal";
CM_ SG_ 2365527585 JoyNtrlPostrim "Joystickneutralpositiontrim";
CM_ SG_ 2365527585 JoyPos "JoystickPosition";
CM_ BO_ 2365527841 "Auxiliary Steering Device (Joystick) � Redundant";
CM_ SG_ 2365527841 Crc16forDtbytes "CRC16fordatabytes(1~6)";
CM_ SG_ 2365527841 Errorcode "Errorcode";
CM_ SG_ 2365527841 SequenceNo "Sequencenumber";
CM_ SG_ 2365527841 JoyEnbsignal "JoystickEnablesignal";
CM_ SG_ 2365527841 JoyNtrlPostrim "Joystickneutralpositiontrim";
CM_ SG_ 2365527841 JoyPos "JoystickPosition";
CM_ BO_ 2365528097 "Vehicle Speed � Primary";
CM_ SG_ 2365528097 Crc16forDtbytes "CRC16fordatabytes(1~6)";
CM_ SG_ 2365528097 SequenceNo "Sequencenumber";
CM_ SG_ 2365528097 VhcSpd "VehicleSpeed";
CM_ SG_ 2365528097 DirIndication "Directionindication";
CM_ BO_ 2365528353 "Vehicle Speed � Redundant";
CM_ SG_ 2365528353 Crc16forDtbytes "CRC16fordatabytes(1~6)";
CM_ SG_ 2365528353 SequenceNo "Sequencenumber";
CM_ SG_ 2365528353 VhcSpd "VehicleSpeed";
CM_ SG_ 2365528353 Drtindication "Directionindication";
CM_ BO_ 2566856451 "TCU_2";
CM_ BO_ 2566856707 "TCU_3";
CM_ BO_ 2365530117 "SpeedLimit_Prop1";
CM_ BO_ 2566856960 "EDC to Body Computer EDC2BC CAN message CAN";
CM_ SG_ 2566856960 DpfSootLv "DPFSootLevel";
CM_ SG_ 2566856960 EdcOprSt "EDCOperationalStatus";
CM_ SG_ 2566856960 EgDgrdLv "EngineDegradationLevel";
CM_ SG_ 2566856960 EgOilTmpHh "EngineOilTemperatureHigh";
CM_ SG_ 2566856960 FuelFiltHtSt "FuelFilterHeaterStatus";
CM_ SG_ 2566856960 WifWrn "WaterInFuelDetection";
CM_ SG_ 2566856960 EgOilPrsLw "EngineOilPressureLow";
CM_ SG_ 2566856960 BtnStp "StopButtonStatus";
CM_ SG_ 2566856960 RgnLmp "RegenerationLampStatus";
CM_ SG_ 2566856960 HydPmpActReq "Hydraulicpumpactivationrequest/Forcedregenerationstatus";
CM_ SG_ 2566856960 MIL "MILStatus";
CM_ SG_ 2566856960 EgOvrSpd "EngineOverspeed";
CM_ SG_ 2566856960 SpdLmtLmp "VehicleSpeedLimiterLampStatus";
CM_ SG_ 2566856960 DiagLmp "DiagnosticLampStatus";
CM_ SG_ 2566856960 FuelBlock "FuelBlockStatusByTheImmobilizer";
CM_ SG_ 2566856960 ColdStartHt "ColdStartHeaterStatus";
CM_ BO_ 2365530373 "SpeedLimit_Prop2";
CM_ BO_ 2566857219 "TCU_4";
CM_ SG_ 2566857219 CnvtTurbTrq "ConverterTurbineTorque";
CM_ SG_ 2566857219 CnvtPmpTrq "ConverterPumpTorque";
CM_ BO_ 2566857731 "ZFCC";
CM_ BO_ 2566857984 "Engine operating condition Frame CAN";
CM_ SG_ 2566857984 PhsDifCrkCam "Phasedifferencebetweencrankandcam";
CM_ SG_ 2566857984 EgOprCmd "Engineoperatingcondition";
CM_ SG_ 2566857984 AirMassPrs "Airmass";
CM_ BO_ 2566858752 "Receive Frame to control fan speed";
CM_ SG_ 2566858752 RedFanSpd100 "statusmessagetoreducefanspeedby100%";
CM_ SG_ 2566858752 RedFanSpd70 "statusmessagetoreducefanspeedby70%";
CM_ SG_ 2566858752 RedFanSpd50 "statusmessagetoreducefanspeedby50%";
CM_ SG_ 2566858752 RedFanSpd30 "statusmessagetoreducefanspeedby30%";
CM_ SG_ 2566858752 RedFanSpd0 "statusmessagetoreducefanspeedby0%";
CM_ BO_ 2566859297 "VEHICLE_2";
CM_ BO_ 2566859523 "TCU_1";
CM_ SG_ 2566859523 IsEngDrvSt "Driveline_status";
CM_ SG_ 2566859523 InProcShftSt "Shift_status";
CM_ SG_ 2566859523 OpMd "OP_mode";
CM_ SG_ 2566859523 IsActJoyMd "Joystick_Mode";
CM_ SG_ 2566859523 CurDir "Current_dir";
CM_ SG_ 2566859523 CurGr "Current_gear";
CM_ SG_ 2566859523 DifLck "DifferentialLock";
CM_ SG_ 2566859523 ShftDir "Shifter_direction";
CM_ SG_ 2566859523 ShftRng "Shifter_range";
CM_ SG_ 2566859523 ErrCode "Error_code";
CM_ SG_ 2566859523 OutSpd "Output_speed";
CM_ SG_ 2566859523 EgSpd "Engine_speed";
CM_ BO_ 2566860833 "VCU High Voltage Control Information";
CM_ SG_ 2566860833 ChgSt "ChargingStatus";
CM_ SG_ 2566860833 MchKeyOnSt "MachineStatus";
CM_ SG_ 2566860833 OnBrdChgCmd "OnBoardChargerCommand";
CM_ SG_ 2566860833 QckChgEnableCmd "QuickChargerCommand";
CM_ SG_ 2566860833 PwrDnCmd "Power-DownCommand";
CM_ BO_ 2566861056 "TFI4 Command CAN frame";
CM_ SG_ 2566861056 FiltTm "Filtertime";
CM_ SG_ 2566861056 Cmd "Command";
CM_ BO_ 2566861119 "Oil Status Message";
CM_ SG_ 2566861119 StMsgCode "Status message code";
CM_ BO_ 2566861230 "Oil Status Message";
CM_ SG_ 2566861230 StMsgCode "Status message code";
CM_ BO_ 2566863330 "TFI4 Data CAN Frame";
CM_ BO_ 2566863533 "OBC Monitoring Information";
CM_ SG_ 2566863533 FanSt "FANStatus";
CM_ SG_ 2566863533 PdVlt "PDVoltage";
CM_ SG_ 2566863533 CpVlt "CPVoltage";
CM_ SG_ 2566863533 ObcAtmosphereTemp "OBCAtmosphereTemp.";
CM_ SG_ 2566863533 ObcMaxTemp "OBCMaximunTemp.";
CM_ SG_ 2566863533 PfcVlt "PFCVoltage";
CM_ SG_ 2566863533 AcInCur "ACInputCurrent";
CM_ SG_ 2566863533 AcInFrequency "ACInputFrequency";
CM_ SG_ 2566863533 AcInVlt "ACInputVoltage";
CM_ SG_ 2566863533 ChgElapsedTm "ChargingElapsedTime";
CM_ BO_ 2566864354 "TFI4 air mass flow sensor On Board Diagnostics receive frame";
CM_ BO_ 2566864627 "BMS Signal Group";
CM_ SG_ 2566864627 EstimatedChgTm "Estimatedchargingtime";
CM_ SG_ 2566864627 ChgSt "ChargingState";
CM_ SG_ 2566864627 HtPadSt "HeatingPadStatus";
CM_ SG_ 2566864627 BmsChgSrcType "BMSChargingSourceType";
CM_ BO_ 2566864680 "User Specific Used Hour Data Information";
CM_ SG_ 2566864680 FuelEfficiencybyUser "FuelEfficiencybyUser";
CM_ SG_ 2566864680 EcnMdFuelUsgbyUser "EconomyModeFuelUsagebyUser";
CM_ SG_ 2566864680 StdMdFuelUsgbyUser "StandardModeFuelUsagebyUser";
CM_ SG_ 2566864680 PwrMdFuelUsgbyUser "PowerModeFuelUsagebyUser";
CM_ SG_ 2566864680 PwrPlusMdFuelUsgbyUser "Power+ModeFuelUsagebyUser";
CM_ SG_ 2566864680 TotalFuelUsgbyUser "TotalFuelUsagebyUser";
CM_ SG_ 2566864680 EcnMdOprtgHrbyUser "EconomyModeOperatingHourbyUser";
CM_ SG_ 2566864680 StdMdOprtgHrbyUser "StandardModeOperatingHourbyUser";
CM_ SG_ 2566864680 PwrMdOprtgHrbyUser "PowerModeOperatingHourbyUser";
CM_ SG_ 2566864680 PwrPlusMdOprtgHrbyUser "Power+ModeOperatingHourbyUser";
CM_ SG_ 2566864680 IdleOprtgHrbyUser "IdleOperatingHourbyUser";
CM_ SG_ 2566864680 TotalOprtgHrbyUser "TotalOperatingHourbyUser";
CM_ SG_ 2566864680 UserName "UserName";
CM_ SG_ 2566864680 UserSeparatorFlag "UserSeparatorFlag";
CM_ SG_ 2566864680 UserSeparatorSlot "UserSeparatorSlot";
CM_ BO_ 2566864929 "Warning Symbol Group 1";
CM_ SG_ 2566864929 InvOh "WarningSymbol;InverterOverheatWarning";
CM_ SG_ 2566864929 MotOh "WarningSymbol;MotorOverheatWarning";
CM_ SG_ 2566864929 BatOh "WarningSymbol;BatteryOverheatWarning";
CM_ SG_ 2566864929 Bms "WarningSymbol;BMSWarning";
CM_ SG_ 2566864929 BatHt "WarningSymbol;BatteryHeater";
CM_ SG_ 2566864929 TrvlPdlFail "WarningSymbol;TravelPedalFailureWarning";
CM_ SG_ 2566864929 RrWhlAlgn "WarningSymbol;RearWheelAlignmentWarning";
CM_ SG_ 2566864929 PrkBrkPrs "WarningSymbol;ParkingBrakePressureWarning";
CM_ SG_ 2566864929 TrsmOilFiltClog "WarningSymbol;TransmissionOilFilterClogging";
CM_ SG_ 2566864929 FanMotPrsLw "WarningSymbol;LowFan-Motorpressure";
CM_ SG_ 2566864929 OvSpd "WarningSymbol;OverSpeed";
CM_ SG_ 2566864929 RBrkPdlNoCalb "WarningSymbol;Brakepedalnotcalibrated";
CM_ SG_ 2566864929 ElecStr "WarningSymbol;EletricSteeringWarning";
CM_ SG_ 2566864929 EgOvr "WarningSymbol;EngineOverrun";
CM_ SG_ 2566864929 EmgStr "WarningSymbol;EmergencySteering";
CM_ SG_ 2566864929 SeatBelt "WarningSymbol;SeatBelt";
CM_ SG_ 2566864929 TrsmOilOh "WarningSymbol;TransmissionOilOverheat";
CM_ SG_ 2566864929 Trsm "WarningSymbol;TransmissionWarning";
CM_ SG_ 2566864929 VboEpprVvOut "WarningSymbol;VBOError-EPPRV/VOutput";
CM_ SG_ 2566864929 VboJoySs "WarningSymbol;VBOError-JoystickSensor";
CM_ SG_ 2566864929 VboAngSs "WarningSymbol;VBOError-AngleSensor";
CM_ SG_ 2566864929 BatEq "WarningSymbol;BatteryEqualizer";
CM_ SG_ 2566864929 Uss "WarningSymbol;UltraSonicSensorWarning";
CM_ SG_ 2566864929 IceptSs "WarningSymbol;iCEPTSensorWarning";
CM_ SG_ 2566864929 Str "WarningSymbol;Steering";
CM_ SG_ 2566864929 BrkOilPrsLw "WarningSymbol;BrakeOilPressLow";
CM_ SG_ 2566864929 Ags "WarningSymbol;AGS??";
CM_ SG_ 2566864929 Owd "WarningSymbol;OWDWarning";
CM_ SG_ 2566864929 PilotFilt "WarningSymbol;PilotFilter";
CM_ SG_ 2566864929 RetFilt "WarningSymbol;ReturnFilter";
CM_ SG_ 2566864929 HydOilOh "WarningSymbol;Hyd.OilOverheat";
CM_ SG_ 2566864929 BatChg "WarningSymbol;BatteryCharge";
CM_ BO_ 2566865185 "Warning Symbol Group 2";
CM_ SG_ 2566865185 AcleOilOh "WarningSymbol;AxleOilOverheat";
CM_ SG_ 2566865185 TireTemp "WarningSymbol;TireTemperature";
CM_ SG_ 2566865185 FuelEmptyAddFuelTnk "WarningSymbol;FuelEmptyforAdditionalFuelTank";
CM_ SG_ 2566865185 ePowStp "WarningSymbol;ePowerSystemStop";
CM_ SG_ 2566865185 ePowChk "WarningSymbol;ePowerSystemCheck";
CM_ SG_ 2566865185 CoolLv "WarningSymbol;CoolantLevelWarning(RED)ReservedTank";
CM_ SG_ 2566865185 DefPrsLw "WarningSymbol;LowDEFpressure";
CM_ SG_ 2566865185 WifMainFiltFault "WarningSymbol;WaterInFuelWarning(MainFilterFault???)";
CM_ SG_ 2566865185 WifMainFiltWaterDetectFault "WarningSymbol;WaterInFuelWarning(MainFilter?????)";
CM_ SG_ 2566865185 WifPrePilotFault "WarningSymbol;WaterInFuelWarning(PreFilterFault???)";
CM_ SG_ 2566865185 WifPrePilot "WarningSymbol;WaterInFuelWarning(PreFilter?????)";
CM_ SG_ 2566865185 FuelEmpty "WarningSymbol;FuelEmpty";
CM_ SG_ 2566865185 AutoSCrcondPrkns "WarningSymbol;AutoSCRCONDITIONING(forPerkins)";
CM_ SG_ 2566865185 ExHhTempAmb "WarningSymbol;ExhaustSystemHighTemperature_Amber";
CM_ SG_ 2566865185 ExHhTempGr "WarningSymbol;ExhaustSystemHighTemperature_Green";
CM_ SG_ 2566865185 DpfActRgnInhbtSt "WarningSymbol;DPFActiveRegenerationInhibitedStatus";
CM_ SG_ 2566865185 DpfRgnClg "WarningSymbol;DPFRegenerationStatusLampCommand(DPF????)";
CM_ SG_ 2566865185 EgChkSrv "WarningSymbol;EngineCheck???";
CM_ SG_ 2566865185 EgChk2 "WarningSymbol;EngineCheck2?";
CM_ SG_ 2566865185 EgChk1 "WarningSymbol;EngineCheck1?";
CM_ SG_ 2566865185 EgStp "WarningSymbol;EngineStop";
CM_ SG_ 2566865185 EgWrn "WarningSymbol;EngineWarning";
CM_ SG_ 2566865185 AirCln "WarningSymbol;AirCleaner";
CM_ SG_ 2566865185 CoolLvSrgTnk "WarningSymbol;CoolantLevelWarning(RED)SurgeTank";
CM_ SG_ 2566865185 CoolTmpOv "WarningSymbol;CoolantTemp.Overheat";
CM_ SG_ 2566865185 EgOilPrs "WarningSymbol;EngineOilPressure";
CM_ BO_ 2566865441 "Warning Symbol Group 3";
CM_ SG_ 2566865441 TirePrs "WarningSymbol;TirePressure";
CM_ SG_ 2566865441 HydOilWarmUp "Warningpop-up;HydraulicOilWarmUp";
CM_ SG_ 2566865441 GndSawRdy "WarningSymbol;GroundSawReady";
CM_ SG_ 2566865441 TrvMotTempOh "WarningSymbol;TravelMotorTemp.Overheat";
CM_ SG_ 2566865441 QckCouplerLck "WarningSymbol;QuickCouplerLock";
CM_ SG_ 2566865441 BrkPdlSs "WarningSymbol;BrakePedalSensor";
CM_ SG_ 2566865441 AtsRgnReq "WarningSymbol;ATSRegenerationRequest";
CM_ SG_ 2566865441 TmsConSt "WarningSymbol;TMSModuleConnectStatus";
CM_ SG_ 2566865441 QckCouplerUnlock "WarningSymbol;QuickCouplerUnlock";
CM_ SG_ 2566865441 RmvCntwt "WarningSymbol;RemovableCountweight";
CM_ SG_ 2566865441 FuelFilt "WarningSymbol;FuelFilter";
CM_ SG_ 2566865441 UreaQualScr "WarningSymbol;UreaQualityWarningLamp(SCR?????)";
CM_ SG_ 2566865441 UreaLv "WarningSymbol;UreaLevelIndicator";
CM_ BO_ 2566865697 "State Information Group 1";
CM_ SG_ 2566865697 BzzCtrlCmd "BuzzerControlCommand";
CM_ SG_ 2566865697 CurGr "VehicleStateSymbol;CurrentGearStatus";
CM_ SG_ 2566865697 SelGr "VehicleStateSymbol;SelectedGearStatus";
CM_ SG_ 2566865697 BoomFltBiDir "VehicleStateSymbol;BoomFloat(Bi-Direction)";
CM_ SG_ 2566865697 Is3RdFNRElecStr "3rdFNR+????Activation";
CM_ SG_ 2566865697 IsFR "VehicleStateSymbol;F/RSelect";
CM_ SG_ 2566865697 IsElecStr "VehicleStateSymbol;ElectricSteeringSelect";
CM_ SG_ 2566865697 IsOprRdy "CEOpreratingReadyStaus";
CM_ SG_ 2566865697 PreHt "IndicatorSymbol;PreheatLamp";
CM_ SG_ 2566865697 FaultCntAvm "???????(AVM??)";
CM_ SG_ 2566865697 FaultCntMch "???????(????)";
CM_ SG_ 2566865697 CtrWrnLed "CentralWarningLEDCommand";
CM_ SG_ 2566865697 ExBzz "ExBuzzerCommand";
CM_ SG_ 2566865697 AutoShdnAval "AutoShutDown??????";
CM_ SG_ 2566865697 AutoShdnSt "AutoShutDownState";
CM_ SG_ 2566865697 BrkrAct "Breaker????";
CM_ SG_ 2566865697 ThmbWhlLvErr "????Command;ThumbWheelLeverError??";
CM_ SG_ 2566865697 AutoIdle "AutoidleStatusInformation";
CM_ SG_ 2566865697 RgnPrkns "????Command;Regeneration??(forPerkins)";
CM_ SG_ 2566865697 RpmCtrlRstrt "????Command;Rpm??????";
CM_ SG_ 2566865697 IgnRstrtPilotCutOff "????Command;??????(??????????)";
CM_ SG_ 2566865697 IgnRstrtFRP "????Command;??????(?/??????????????)";
CM_ SG_ 2566865697 OhPrv "????Command;??????";
CM_ SG_ 2566865697 HhMntLgc "IndicatorSymbol;???????";
CM_ SG_ 2566865697 AutoShdn "IndicatorSymbol;AutoShutDown";
CM_ SG_ 2566865697 FuelHt "IndicatorSymbol;FuelHeater";
CM_ SG_ 2566865697 AutoWarmUpGr "IndicatorSymbol;AutoWarmup(Green)";
CM_ SG_ 2566865697 AutoWarmUpAmb "IndicatorSymbol;AutoWarmup(Amber)";
CM_ SG_ 2566865697 HhBeam "WheelTypeSymbol;HighBeam";
CM_ SG_ 2566865697 RamLck "WheelTypeSymbol;RAMLock";
CM_ SG_ 2566865697 PrkBrk "WheelTypeSymbol;ParkingBrake";
CM_ SG_ 2566865697 Trv "WheelTypeSymbol;Travel";
CM_ SG_ 2566865697 FNR "WheelTypeSymbol;F/N/R";
CM_ SG_ 2566865697 TrvMdWhl "TravelModeSymbolforWheel";
CM_ SG_ 2566865697 IsoBhl "VehicleStateSymbol;ISO/BHL";
CM_ SG_ 2566865697 TwOpt "TwoWayOpt??????";
CM_ SG_ 2566865697 WrkMd "WorkModeSymbol";
CM_ SG_ 2566865697 TrvMdCrw "TravelModeSymbolforCrawler";
CM_ SG_ 2566865697 MrrHt "VehicleStateSymbol;MirrorHeater";
CM_ SG_ 2566865697 AuxMdSt "VehicleStateSymbol;AuxModeState";
CM_ SG_ 2566865697 RvsFanSt "VehicleStateSymbol;ReverseFanState";
CM_ SG_ 2566865697 SwPriSt "VehicleStateSymbol;SwingPriorityState";
CM_ SG_ 2566865697 BoomSwAct "VehicleStateSymbol;BoomSwingActive??";
CM_ SG_ 2566865697 BoomFltSngDir "VehicleStateSymbol;BoomFloat(SingleDirection)";
CM_ SG_ 2566865697 PowMax "VehicleStateSymbol;PowerMax";
CM_ SG_ 2566865697 WrkLmp "VehicleStateSymbol;WorkLamp";
CM_ BO_ 2566865953 "State Information Group 2";
CM_ SG_ 2566865953 HstTractionLvSel "WarningPop-up;HSTTractionLevelSelect";
CM_ SG_ 2566865953 FltHold "VehicleStateSymbol;FloatingHolding";
CM_ SG_ 2566865953 Adb "VehicleStateSymbol;ADB";
CM_ SG_ 2566865953 Cruise "VehicleStateSymbol;Cruise";
CM_ SG_ 2566865953 WhlDrvMd "????Command;4WheelDriveMode??";
CM_ SG_ 2566865953 DesMchShtDn "WarningPop-up;DESMachineShutdown";
CM_ SG_ 2566865953 FrcRgnStp "WarningPop-up;??????";
CM_ SG_ 2566865953 FrcRgnScs "WarningPop-up;??????";
CM_ SG_ 2566865953 WghCnt "WeighingSignal;WeightCount";
CM_ SG_ 2566865953 MapCreateProg "WeighingSignal;MapCreationProgressStepNo.";
CM_ SG_ 2566865953 AngSsTunReq "WeighingSignal;AngleSensorTunningRequest";
CM_ SG_ 2566865953 ZeroCalbReq "WeighingSignal;ZeroCalibrationRequest";
CM_ SG_ 2566865953 WarmUp "WeighingSignal;WarmUpRequest";
CM_ SG_ 2566865953 MapCreatReady "WeighingSignal;MapCreationReadySignal";
CM_ SG_ 2566865953 ColdStart "WarningPop-up;ColdStart";
CM_ SG_ 2566865953 WghTooHv "WarningPop-up;WeighingTooheavyWarning";
CM_ SG_ 2566865953 WghPoorLft "WarningPop-up;WeighingPoorLiftWarning";
CM_ SG_ 2566865953 WghStartPosHh "WarningPop-up;WeighingStartPositionHighWarning";
CM_ SG_ 2566865953 WghSpdBuc "WarningPop-up;WeighingSpeedBounceWarning";
CM_ SG_ 2566865953 WghUnderSpd "WarningPop-up;WeighingUnderSpeedWarning";
CM_ SG_ 2566865953 RrDefst "IndicatorSymbol;RearDefrost";
CM_ SG_ 2566865953 EmgMd "WarningPop-up;EmergencyMode";
CM_ SG_ 2566865953 OprMd "VehicleStateSymbol;OperatingModeInformation";
CM_ SG_ 2566865953 OprPowMd "VehicleStateSymbol;OperatingPowerModeInformation";
CM_ SG_ 2566865953 HstMdWld "TractionMode(HST)SymbolforLoader";
CM_ SG_ 2566865953 CCO "VehicleStateSymbol;CCO";
CM_ SG_ 2566865953 TrqCvt "VehicleStateSymbol;TorqueConverter";
CM_ SG_ 2566865953 TrvMdWld "TravelModeSymbolforLoader";
CM_ SG_ 2566865953 Creep "VehicleStateSymbol;Creep";
CM_ SG_ 2566865953 ThrtLck "VehicleStateSymbol;ThrottleLock";
CM_ SG_ 2566865953 Dhl "VehicleStateSymbol;DHL";
CM_ SG_ 2566865953 LisSw "VehicleStateSymbol;LISSiwtch";
CM_ SG_ 2566865953 CoolDrtTm "CoolantDeratingTime";
CM_ SG_ 2566865953 WifDrtTm "WIFDeratingTime";
CM_ BO_ 2566866179 "ZFETC9";
CM_ BO_ 2566866209 "Gauge Data Group";
CM_ BO_ 2566866465 "Unclassified Periodic Data";
CM_ BO_ 2566866721 "State Information Group 3";
CM_ SG_ 2566866721 DifActlTrgGrdt "Warningpop-up;InterlockDetail-DifferenceActualandTargetGradient";
CM_ SG_ 2566866721 OprPrsntSt "Warningpop-up;InterlockDetail-OperatorPresentState";
CM_ SG_ 2566866721 HydCutOffRls "Warningpop-up;InterlockDetail-HydraulicCutOffRelease";
CM_ SG_ 2566866721 ChgErr "Warningpop-up;Chargingisabnormal";
CM_ SG_ 2566866721 ChgSt "VehicleStateSymbol;ChargingStatus";
CM_ SG_ 2566866721 WrkTrv "VehicleStateSymbol;Working/Travelenable";
CM_ SG_ 2566866721 BatLw "Warningpop-up;LowBattery";
CM_ SG_ 2566866721 HydLck "IndicatorSymbol;HydraulicLock";
CM_ SG_ 2566866721 HillDscntCtrlSt "IndicatorSymbol;HillDescentControlStatus";
CM_ SG_ 2566866721 OprPrsnc "IndicatorSymbol;OperatorPresence";
CM_ SG_ 2566866721 BckDust "IndicatorSymbol;BucketDusting";
CM_ SG_ 2566866721 BmsPrhtLmp "IndicatorSymbol;BMSPreheatLamp";
CM_ SG_ 2566866721 DacSt "DACState";
CM_ SG_ 2566866721 EmcvFngrtpLvrErr "????Command;E-MCVFingertipLeverError??";
CM_ SG_ 2566866721 IllminSt "IlluminationStatus";
CM_ SG_ 2566866721 ChmslSt "CHMSLStatus";
CM_ SG_ 2566866721 CdsFanRvsSt "IndicatorSymbol;CondenserFanReverseState";
CM_ SG_ 2566866721 CacFanRvsSt "IndicatorSymbol;CACFanReverseState";
CM_ SG_ 2566866721 WrnGndSlop "WarningPop-up;GroundSlopeforWeighing";
CM_ SG_ 2566866721 WrnOilTmpLw "WarningPop-up;OilTemperaturetooLowforWeighing";
CM_ SG_ 2566866721 AttOpr "AttachmentOperatingSignal";
CM_ SG_ 2566866721 WrnLimpHome "Warningpop-up;LimpHome";
CM_ SG_ 2566866721 MchCond "MachineCondition";
CM_ SG_ 2566866721 WrnRollOvr "Warningpop-up;Rollover";
CM_ SG_ 2566866721 WrnArmPosOnDrv "Warningpop-up;ArmPositionondriving";
CM_ SG_ 2566866721 WrnThmbWhlStrShft "Warningpop-up;ThumbWheelSteeringShifting";
CM_ SG_ 2566866721 WrnRamLck "????Command;RAMLockinformation";
CM_ SG_ 2566866721 WrnHstOilFilt "Warningpop-up;HSTOilFilter";
CM_ SG_ 2566866721 WrnGrBoxOvTmp "Warningpop-up;GearboxOverTemperature";
CM_ SG_ 2566866721 VhcStTractionLv "VehicleStateSymbol;TractionLevel";
CM_ SG_ 2566866721 WhlLis "WheelTypeSymbol;LIS";
CM_ SG_ 2566866721 WhlDzTrlHitch "WheelTypeSymbol;Dozer/TrailerHitch";
CM_ SG_ 2566866721 WhlSwgAlign "WheelTypeSymbol;SwingAlign";
CM_ SG_ 2566866721 WhlRamLckAuto "WheelTypeSymbol;RAMLockAuto";
BA_DEF_  "DBName" STRING ;
BA_DEF_  "ProtocolType" STRING ;
BA_DEF_ BO_  "VFrameFormat" ENUM  "StandardCAN","ExtendedCAN","reserved","J1939PG";
BA_DEF_ BO_  "Channel" STRING ;
BA_DEF_ BO_  "VssMsg" STRING ;
BA_DEF_ SG_  "VssSig" STRING ;
BA_DEF_ BO_  "GenMsgCycleTime" INT 0 65535;
BA_DEF_DEF_  "DBName" "";
BA_DEF_DEF_  "ProtocolType" "J1939";
BA_DEF_DEF_  "VFrameFormat" "J1939PG";
BA_DEF_DEF_  "Channel" "";
BA_DEF_DEF_  "VssMsg" "";
BA_DEF_DEF_  "VssSig" "";
BA_DEF_DEF_  "GenMsgCycleTime" 0;
BA_ "DBName" "ModelW";
BA_ "Channel" BO_ 2566834688 "can2";
BA_ "Channel" BO_ 2566834863 "can2";
BA_ "Channel" BO_ 2583691183 "can5";
BA_ "GenMsgCycleTime" BO_ 2583662767 200;
BA_ "VssMsg" BO_ 2583662767 "Mch.TGU.PHMWG";
BA_ "Channel" BO_ 2583662767 "can1";
BA_ "VssMsg" BO_ 2565818920 "Mch.GP.GPSMTMS";
BA_ "Channel" BO_ 2565818920 "can1";
BA_ "GenMsgCycleTime" BO_ 2583669610 1000;
BA_ "Channel" BO_ 2583669610 "can2";
BA_ "GenMsgCycleTime" BO_ 2583667562 1000;
BA_ "Channel" BO_ 2583667562 "can2";
BA_ "Channel" BO_ 2565844776 "can2";
BA_ "VssMsg" BO_ 2565844776 "Mch.GP.GPSMTMS";
BA_ "Channel" BO_ 2566834794 "can2";
BA_ "GenMsgCycleTime" BO_ 2348810243 10;
BA_ "VssMsg" BO_ 2348810243 "Mch.TCU.TSC1";
BA_ "Channel" BO_ 2348810243 "can1";
BA_ "GenMsgCycleTime" BO_ 2348810251 10;
BA_ "VssMsg" BO_ 2348810251 "Mch.BRK.TSC1";
BA_ "Channel" BO_ 2348810251 "can1";
BA_ "GenMsgCycleTime" BO_ 2348810259 10;
BA_ "VssMsg" BO_ 2348810259 "Mch.ESP.TSC1";
BA_ "Channel" BO_ 2348810259 "can1";
BA_ "GenMsgCycleTime" BO_ 2348810273 10;
BA_ "VssMsg" BO_ 2348810273 "Mch.MCU.TSC1";
BA_ "Channel" BO_ 2348810273 "can1";
BA_ "GenMsgCycleTime" BO_ 2348814083 50;
BA_ "VssMsg" BO_ 2348814083 "Mch.TCU.TSC1RDE";
BA_ "Channel" BO_ 2348814083 "can1";
BA_ "GenMsgCycleTime" BO_ 2348814091 50;
BA_ "VssMsg" BO_ 2348814091 "Mch.BRK.TSC1RDE";
BA_ "Channel" BO_ 2348814091 "can1";
BA_ "GenMsgCycleTime" BO_ 2348814096 50;
BA_ "VssMsg" BO_ 2348814096 "Mch.RDD.TSC1RDE";
BA_ "Channel" BO_ 2348814096 "can1";
BA_ "GenMsgCycleTime" BO_ 2348814099 50;
BA_ "VssMsg" BO_ 2348814099 "Mch.ESP.TSC1RDE";
BA_ "Channel" BO_ 2348814099 "can1";
BA_ "GenMsgCycleTime" BO_ 2348814113 50;
BA_ "VssMsg" BO_ 2348814113 "Mch.MCU.TSC1RDE";
BA_ "Channel" BO_ 2348814113 "can1";
BA_ "GenMsgCycleTime" BO_ 2350579745 20;
BA_ "VssMsg" BO_ 2350579745 "Mch.MCU.HVESSC1";
BA_ "Channel" BO_ 2350579745 "can1";
BA_ "GenMsgCycleTime" BO_ 2351300641 10;
BA_ "VssMsg" BO_ 2351300641 "Mch.MCU.MG1IC";
BA_ "Channel" BO_ 2351300641 "can1";
BA_ "GenMsgCycleTime" BO_ 2564816912 1000;
BA_ "VssMsg" BO_ 2564816912 "Mch.RDD.CM1";
BA_ "Channel" BO_ 2564816912 "can1";
BA_ "GenMsgCycleTime" BO_ 2564816929 1000;
BA_ "VssMsg" BO_ 2564816929 "Mch.MCU.CM1";
BA_ "Channel" BO_ 2564816929 "can1";
BA_ "GenMsgCycleTime" BO_ 2565800744 50;
BA_ "VssMsg" BO_ 2565800744 "Mch.GP.GPSMTCU";
BA_ "Channel" BO_ 2565800744 "can1";
BA_ "GenMsgCycleTime" BO_ 2364478241 500;
BA_ "VssMsg" BO_ 2364478241 "Mch.MCU.MMIPR";
BA_ "Channel" BO_ 2364478241 "can1";
BA_ "VssMsg" BO_ 2565805864 "Mch.GP.GPSMCLT";
BA_ "Channel" BO_ 2565805864 "can1";
BA_ "VssMsg" BO_ 2565808424 "Mch.GP.GPSMVCU";
BA_ "Channel" BO_ 2565808424 "can1";
BA_ "VssMsg" BO_ 2565808458 "Mch.TMS.REQMCU";
BA_ "Channel" BO_ 2565808458 "can1";
BA_ "GenMsgCycleTime" BO_ 2565810241 1000;
BA_ "VssMsg" BO_ 2565810241 "Mch.GW.REQGP";
BA_ "Channel" BO_ 2565810241 "can1";
BA_ "VssMsg" BO_ 2565810250 "Mch.TMS.REQGP";
BA_ "Channel" BO_ 2565810250 "can1";
BA_ "VssMsg" BO_ 2565810256 "Mch.KPD1.REQGP";
BA_ "Channel" BO_ 2565810256 "can1";
BA_ "VssMsg" BO_ 2565816616 "Mch.GP.GPSMGW";
BA_ "Channel" BO_ 2565816616 "can1";
BA_ "VssMsg" BO_ 2565827112 "Mch.GP.GPSMTMS";
BA_ "Channel" BO_ 2565827112 "can1";
BA_ "VssMsg" BO_ 2565820456 "Mch.GP.GPSMKPD";
BA_ "Channel" BO_ 2565820456 "can1";
BA_ "VssMsg" BO_ 2565821480 "Mch.GP.GPSMAVM";
BA_ "Channel" BO_ 2565821480 "can1";
BA_ "VssMsg" BO_ 2565821505 "Mch.GW.REQEXMON";
BA_ "Channel" BO_ 2565821505 "can1";
BA_ "GenMsgCycleTime" BO_ 2364496417 500;
BA_ "VssMsg" BO_ 2364496417 "Mch.MCU.MMISC";
BA_ "Channel" BO_ 2364496417 "can1";
BA_ "GenMsgCycleTime" BO_ 2565865487 100;
BA_ "VssMsg" BO_ 2565865487 "Mch.RDE.ERC1";
BA_ "Channel" BO_ 2565865487 "can1";
BA_ "GenMsgCycleTime" BO_ 2565865488 100;
BA_ "VssMsg" BO_ 2565865488 "Mch.RDD.ERC1";
BA_ "Channel" BO_ 2565865488 "can1";
BA_ "GenMsgCycleTime" BO_ 2565865733 50;
BA_ "VssMsg" BO_ 2565865733 "Mch.FNR.EBC1";
BA_ "Channel" BO_ 2565865733 "can1";
BA_ "GenMsgCycleTime" BO_ 2565865739 100;
BA_ "VssMsg" BO_ 2565865739 "Mch.BRK.EBC1";
BA_ "Channel" BO_ 2565865739 "can1";
BA_ "GenMsgCycleTime" BO_ 2364539395 10;
BA_ "VssMsg" BO_ 2364539395 "Mch.TCU.ETC1";
BA_ "Channel" BO_ 2364539395 "can1";
BA_ "GenMsgCycleTime" BO_ 2364539648 50;
BA_ "VssMsg" BO_ 2364539648 "Mch.ECU.EEC2";
BA_ "Channel" BO_ 2364539648 "can1";
BA_ "GenMsgCycleTime" BO_ 2364539904 10;
BA_ "VssMsg" BO_ 2364539904 "Mch.ECU.EEC1";
BA_ "Channel" BO_ 2364539904 "can1";
BA_ "GenMsgCycleTime" BO_ 2565866755 100;
BA_ "VssMsg" BO_ 2565866755 "Mch.TCU.ETC2";
BA_ "Channel" BO_ 2565866755 "can1";
BA_ "GenMsgCycleTime" BO_ 2565867011 500;
BA_ "VssMsg" BO_ 2565867011 "Mch.TCU.EAC1";
BA_ "Channel" BO_ 2565867011 "can1";
BA_ "GenMsgCycleTime" BO_ 2364542241 100;
BA_ "VssMsg" BO_ 2364542241 "Mch.MCU.LOI";
BA_ "Channel" BO_ 2364542241 "can1";
BA_ "GenMsgCycleTime" BO_ 2565869137 50;
BA_ "VssMsg" BO_ 2565869137 "Mch.KPD2.AT1IG1";
BA_ "Channel" BO_ 2565869137 "can1";
BA_ "GenMsgCycleTime" BO_ 2565869394 50;
BA_ "VssMsg" BO_ 2565869394 "Mch.ATSGO.AT1OG1";
BA_ "Channel" BO_ 2565869394 "can1";
BA_ "GenMsgCycleTime" BO_ 2565875998 10;
BA_ "VssMsg" BO_ 2565875998 "Mch.ACU.SSI2";
BA_ "Channel" BO_ 2565875998 "can1";
BA_ "GenMsgCycleTime" BO_ 2565876161 10;
BA_ "VssMsg" BO_ 2565876161 "Mch.IMU1.SSI2";
BA_ "Channel" BO_ 2565876161 "can1";
BA_ "GenMsgCycleTime" BO_ 2565876162 10;
BA_ "VssMsg" BO_ 2565876162 "Mch.IMU2.SSI2";
BA_ "Channel" BO_ 2565876162 "can1";
BA_ "GenMsgCycleTime" BO_ 2565876163 10;
BA_ "VssMsg" BO_ 2565876163 "Mch.IMU3.SSI2";
BA_ "Channel" BO_ 2565876163 "can1";
BA_ "GenMsgCycleTime" BO_ 2565876164 10;
BA_ "VssMsg" BO_ 2565876164 "Mch.IMU4.SSI2";
BA_ "Channel" BO_ 2565876164 "can1";
BA_ "GenMsgCycleTime" BO_ 2565876165 10;
BA_ "VssMsg" BO_ 2565876165 "Mch.IMU5.SSI2";
BA_ "Channel" BO_ 2565876165 "can1";
BA_ "GenMsgCycleTime" BO_ 2364575987 20;
BA_ "VssMsg" BO_ 2364575987 "Mch.AGW.HVESSD1";
BA_ "Channel" BO_ 2364575987 "can1";
BA_ "GenMsgCycleTime" BO_ 2364576243 20;
BA_ "VssMsg" BO_ 2364576243 "Mch.AGW.HVESSD2";
BA_ "Channel" BO_ 2364576243 "can1";
BA_ "GenMsgCycleTime" BO_ 2364576755 100;
BA_ "VssMsg" BO_ 2364576755 "Mch.AGW.HVESSD4";
BA_ "Channel" BO_ 2364576755 "can1";
BA_ "GenMsgCycleTime" BO_ 2364577011 20;
BA_ "VssMsg" BO_ 2364577011 "Mch.AGW.HVESSD5";
BA_ "Channel" BO_ 2364577011 "can1";
BA_ "GenMsgCycleTime" BO_ 2364577267 100;
BA_ "VssMsg" BO_ 2364577267 "Mch.AGW.HVESSD6";
BA_ "Channel" BO_ 2364577267 "can1";
BA_ "GenMsgCycleTime" BO_ 2364637584 100;
BA_ "VssMsg" BO_ 2364637584 "Mch.PMI.MG1IMF1";
BA_ "Channel" BO_ 2364637584 "can1";
BA_ "VssMsg" BO_ 2364641057 "Mch.MCU.IPGA";
BA_ "Channel" BO_ 2364641057 "can1";
BA_ "VssMsg" BO_ 2364641267 "Mch.AGW.IPGA";
BA_ "Channel" BO_ 2364641267 "can1";
BA_ "GenMsgCycleTime" BO_ 2365288848 1000;
BA_ "VssMsg" BO_ 2365288848 "Mch.PMI.MG1IMT";
BA_ "Channel" BO_ 2365288848 "can1";
BA_ "GenMsgCycleTime" BO_ 2365289104 1000;
BA_ "VssMsg" BO_ 2365289104 "Mch.PMI.MG1IT";
BA_ "Channel" BO_ 2365289104 "can1";
BA_ "GenMsgCycleTime" BO_ 2365289360 1000;
BA_ "VssMsg" BO_ 2365289360 "Mch.PMI.MG1IR2";
BA_ "Channel" BO_ 2365289360 "can1";
BA_ "GenMsgCycleTime" BO_ 2365289616 10;
BA_ "VssMsg" BO_ 2365289616 "Mch.PMI.MG1IS1";
BA_ "Channel" BO_ 2365289616 "can1";
BA_ "VssMsg" BO_ 2566675955 "Mch.AGW.HVESSCFG";
BA_ "Channel" BO_ 2566675955 "can1";
BA_ "VssMsg" BO_ 2633785075 "Mch.AGW.HVESSHIST";
BA_ "Channel" BO_ 2633785075 "can1";
BA_ "GenMsgCycleTime" BO_ 2566709248 10;
BA_ "VssMsg" BO_ 2566709248 "Mch.ECU.DPFC2";
BA_ "Channel" BO_ 2566709248 "can1";
BA_ "GenMsgCycleTime" BO_ 2633828415 30000;
BA_ "VssMsg" BO_ 2633828415 "Mch.HDOQS.OQM1";
BA_ "Channel" BO_ 2633828415 "can2";
BA_ "GenMsgCycleTime" BO_ 2633828526 30000;
BA_ "VssMsg" BO_ 2633828526 "Mch.EGOQS.OQM1";
BA_ "Channel" BO_ 2633828526 "can2";
BA_ "GenMsgCycleTime" BO_ 2566719744 1000;
BA_ "VssMsg" BO_ 2566719744 "Mch.ECU.HRLFC";
BA_ "Channel" BO_ 2566719744 "can1";
BA_ "VssMsg" BO_ 2365394514 "Mch.ATSGO.AT1OGC2";
BA_ "Channel" BO_ 2365394514 "can1";
BA_ "VssMsg" BO_ 2365394770 "Mch.ATSGO.AT1OGC1";
BA_ "Channel" BO_ 2365394770 "can1";
BA_ "VssMsg" BO_ 2365395025 "Mch.KPD2.AT1IGC2";
BA_ "Channel" BO_ 2365395025 "can1";
BA_ "VssMsg" BO_ 2365395281 "Mch.KPD2.AT1IGC1";
BA_ "Channel" BO_ 2365395281 "can1";
BA_ "GenMsgCycleTime" BO_ 2566722989 1000;
BA_ "VssMsg" BO_ 2566722989 "Mch.OBC.BCH1";
BA_ "Channel" BO_ 2566722989 "can1";
BA_ "GenMsgCycleTime" BO_ 2566725632 500;
BA_ "VssMsg" BO_ 2566725632 "Mch.ECU.A1DOC";
BA_ "Channel" BO_ 2566725632 "can1";
BA_ "VssMsg" BO_ 2566748928 "Mch.ECU.AT1S";
BA_ "Channel" BO_ 2566748928 "can1";
BA_ "GenMsgCycleTime" BO_ 2566749184 1000;
BA_ "VssMsg" BO_ 2566749184 "Mch.ECU.PTC1";
BA_ "Channel" BO_ 2566749184 "can1";
BA_ "GenMsgCycleTime" BO_ 2566755587 1000;
BA_ "VssMsg" BO_ 2566755587 "Mch.TCU.TRF2";
BA_ "Channel" BO_ 2566755587 "can1";
BA_ "GenMsgCycleTime" BO_ 2566757120 1000;
BA_ "VssMsg" BO_ 2566757120 "Mch.ECU.A1DEFI1";
BA_ "Channel" BO_ 2566757120 "can1";
BA_ "GenMsgCycleTime" BO_ 2566758656 500;
BA_ "VssMsg" BO_ 2566758656 "Mch.ECU.AT1FC1";
BA_ "Channel" BO_ 2566758656 "can1";
BA_ "GenMsgCycleTime" BO_ 2566763008 100;
BA_ "VssMsg" BO_ 2566763008 "Mch.ECU.AT1IMG";
BA_ "Channel" BO_ 2566763008 "can1";
BA_ "GenMsgCycleTime" BO_ 2566763264 500;
BA_ "VssMsg" BO_ 2566763264 "Mch.ECU.AT1OG2";
BA_ "Channel" BO_ 2566763264 "can1";
BA_ "GenMsgCycleTime" BO_ 2566763325 500;
BA_ "VssMsg" BO_ 2566763325 "Mch.EEC.AT1OG2";
BA_ "Channel" BO_ 2566763325 "can1";
BA_ "GenMsgCycleTime" BO_ 2566763520 500;
BA_ "VssMsg" BO_ 2566763520 "Mch.ECU.AT1IG2";
BA_ "Channel" BO_ 2566763520 "can1";
BA_ "GenMsgCycleTime" BO_ 2566763581 500;
BA_ "VssMsg" BO_ 2566763581 "Mch.EEC.AT1IG2";
BA_ "Channel" BO_ 2566763581 "can1";
BA_ "VssMsg" BO_ 2365441523 "Mch.AGW.ECUID";
BA_ "Channel" BO_ 2365441523 "can1";
BA_ "GenMsgCycleTime" BO_ 2566769997 200;
BA_ "VssMsg" BO_ 2566769997 "Mch.CBSW.OWW";
BA_ "Channel" BO_ 2566769997 "can1";
BA_ "VssMsg" BO_ 2566771968 "Mch.ECU.EEC5";
BA_ "Channel" BO_ 2566771968 "can1";
BA_ "VssMsg" BO_ 2365445841 "Mch.EJRH.BJM1";
BA_ "Channel" BO_ 2365445841 "can1";
BA_ "VssMsg" BO_ 2365446097 "Mch.EJRH.EJM1";
BA_ "Channel" BO_ 2365446097 "can1";
BA_ "VssMsg" BO_ 2365446352 "Mch.EJLH.BJM2";
BA_ "Channel" BO_ 2365446352 "can1";
BA_ "VssMsg" BO_ 2365446608 "Mch.EJLH.EJM2";
BA_ "Channel" BO_ 2365446608 "can1";
BA_ "VssMsg" BO_ 2365446893 "Mch.EPDLT.BJM3";
BA_ "Channel" BO_ 2365446893 "can1";
BA_ "VssMsg" BO_ 2365446894 "Mch.EPDL2.BJM3";
BA_ "Channel" BO_ 2365446894 "can1";
BA_ "VssMsg" BO_ 2365446895 "Mch.EPDLR.BJM3";
BA_ "Channel" BO_ 2365446895 "can1";
BA_ "VssMsg" BO_ 2365446896 "Mch.EPDLA.BJM3";
BA_ "Channel" BO_ 2365446896 "can1";
BA_ "GenMsgCycleTime" BO_ 2365468962 20;
BA_ "VssMsg" BO_ 2365468962 "Mch.TRBDZ.AV01C";
BA_ "Channel" BO_ 2365468962 "can1";
BA_ "GenMsgCycleTime" BO_ 2365469218 20;
BA_ "VssMsg" BO_ 2365469218 "Mch.TRBDZ.AV02C";
BA_ "Channel" BO_ 2365469218 "can1";
BA_ "VssMsg" BO_ 2365473101 "Mch.CBSW.LCMD";
BA_ "Channel" BO_ 2365473101 "can1";
BA_ "GenMsgCycleTime" BO_ 2566801441 100;
BA_ "VssMsg" BO_ 2566801441 "Mch.MCU.WBSD";
BA_ "Channel" BO_ 2566801441 "can1";
BA_ "GenMsgCycleTime" BO_ 2566801923 100;
BA_ "VssMsg" BO_ 2566801923 "Mch.TCU.ETC7";
BA_ "Channel" BO_ 2566801923 "can1";
BA_ "GenMsgCycleTime" BO_ 2566802176 1000;
BA_ "VssMsg" BO_ 2566802176 "Mch.ECU.TCFG2";
BA_ "Channel" BO_ 2566802176 "can1";
BA_ "GenMsgCycleTime" BO_ 2566803211 100;
BA_ "VssMsg" BO_ 2566803211 "Mch.BRK.VDC1";
BA_ "Channel" BO_ 2566803211 "can1";
BA_ "GenMsgCycleTime" BO_ 2566804992 1000;
BA_ "VssMsg" BO_ 2566804992 "Mch.ECU.AT1T1I1";
BA_ "Channel" BO_ 2566804992 "can1";
BA_ "GenMsgCycleTime" BO_ 2566804993 1000;
BA_ "VssMsg" BO_ 2566804993 "Mch.ECU1.AT1T1I1";
BA_ "Channel" BO_ 2566804993 "can1";
BA_ "GenMsgCycleTime" BO_ 2365484270 50;
BA_ "VssMsg" BO_ 2365484270 "Mch.EPDL2.TCO1";
BA_ "Channel" BO_ 2365484270 "can1";
BA_ "GenMsgCycleTime" BO_ 2566811147 20;
BA_ "VssMsg" BO_ 2566811147 "Mch.BRK.HRWS";
BA_ "Channel" BO_ 2566811147 "can1";
BA_ "GenMsgCycleTime" BO_ 2633927682 100;
BA_ "VssMsg" BO_ 2633927682 "Mch.ECU.AAI2EDC";
BA_ "Channel" BO_ 2633927682 "can1";
BA_ "GenMsgCycleTime" BO_ 2566831360 1000;
BA_ "VssMsg" BO_ 2566831360 "Mch.ECU.FD";
BA_ "Channel" BO_ 2566831360 "can1";
BA_ "VssMsg" BO_ 2566831616 "Mch.ECU.EEC4";
BA_ "Channel" BO_ 2566831616 "can1";
BA_ "GenMsgCycleTime" BO_ 2566831883 100;
BA_ "VssMsg" BO_ 2566831883 "Mch.BRK.EBC2";
BA_ "Channel" BO_ 2566831883 "can1";
BA_ "GenMsgCycleTime" BO_ 2566832622 1000;
BA_ "VssMsg" BO_ 2566832622 "Mch.EPDL2.VDHR";
BA_ "Channel" BO_ 2566832622 "can1";
BA_ "GenMsgCycleTime" BO_ 2566834749 10;
BA_ "VssMsg" BO_ 2566834749 "Mch.EEC.DM1";
BA_ "Channel" BO_ 2566834749 "can1";
BA_ "VssMsg" BO_ 2566834944 "Mch.ECU.DM2";
BA_ "Channel" BO_ 2566834944 "can1";
BA_ "VssMsg" BO_ 2566835456 "Mch.ECU.DM4";
BA_ "Channel" BO_ 2566835456 "can1";
BA_ "VssMsg" BO_ 2566835712 "Mch.ECU.DM5";
BA_ "Channel" BO_ 2566835712 "can1";
BA_ "VssMsg" BO_ 2566835968 "Mch.ECU.DM6";
BA_ "Channel" BO_ 2566835968 "can1";
BA_ "GenMsgCycleTime" BO_ 2566838528 100;
BA_ "VssMsg" BO_ 2566838528 "Mch.ECU.AUXIO1";
BA_ "Channel" BO_ 2566838528 "can1";
BA_ "VssMsg" BO_ 2566838784 "Mch.ECU.SOFT";
BA_ "Channel" BO_ 2566838784 "can1";
BA_ "VssMsg" BO_ 2566838787 "Mch.TCU.SOFT";
BA_ "Channel" BO_ 2566838787 "can1";
BA_ "VssMsg" BO_ 2365512435 "Mch.AGW.SOFT";
BA_ "Channel" BO_ 2365512435 "can1";
BA_ "VssMsg" BO_ 2566839296 "Mch.ECU.IDLOP";
BA_ "Channel" BO_ 2566839296 "can1";
BA_ "GenMsgCycleTime" BO_ 2566840064 50;
BA_ "VssMsg" BO_ 2566840064 "Mch.ECU.EEC3";
BA_ "Channel" BO_ 2566840064 "can1";
BA_ "GenMsgCycleTime" BO_ 2566841344 1000;
BA_ "VssMsg" BO_ 2566841344 "Mch.ECU.SHUTDWN";
BA_ "Channel" BO_ 2566841344 "can1";
BA_ "VssMsg" BO_ 2566841600 "Mch.ECU.HOURS";
BA_ "Channel" BO_ 2566841600 "can1";
BA_ "GenMsgCycleTime" BO_ 2566841879 1000;
BA_ "VssMsg" BO_ 2566841879 "Mch.CLST.TD";
BA_ "Channel" BO_ 2566841879 "can1";
BA_ "GenMsgCycleTime" BO_ 2566842094 1000;
BA_ "VssMsg" BO_ 2566842094 "Mch.EPDL2.TD";
BA_ "Channel" BO_ 2566842094 "can1";
BA_ "VssMsg" BO_ 2566842112 "Mch.ECU.VH";
BA_ "Channel" BO_ 2566842112 "can1";
BA_ "VssMsg" BO_ 2566842624 "Mch.ECU.LFC1";
BA_ "Channel" BO_ 2566842624 "can1";
BA_ "VssMsg" BO_ 2566843136 "Mch.ECU.CI";
BA_ "Channel" BO_ 2566843136 "can1";
BA_ "VssMsg" BO_ 2566843392 "Mch.ECU.VI";
BA_ "Channel" BO_ 2566843392 "can1";
BA_ "VssMsg" BO_ 2566843648 "Mch.ECU.CCSS";
BA_ "Channel" BO_ 2566843648 "can1";
BA_ "GenMsgCycleTime" BO_ 2566843651 100;
BA_ "VssMsg" BO_ 2566843651 "Mch.TCU.CCSS";
BA_ "Channel" BO_ 2566843651 "can1";
BA_ "GenMsgCycleTime" BO_ 2566843653 100;
BA_ "VssMsg" BO_ 2566843653 "Mch.FNR.CCSS";
BA_ "Channel" BO_ 2566843653 "can1";
BA_ "GenMsgCycleTime" BO_ 2566843904 1000;
BA_ "VssMsg" BO_ 2566843904 "Mch.ECU.ET1";
BA_ "Channel" BO_ 2566843904 "can1";
BA_ "GenMsgCycleTime" BO_ 2566843967 3000;
BA_ "VssMsg" BO_ 2566843967 "Mch.HDOQS.OT1";
BA_ "Channel" BO_ 2566843967 "can2";
BA_ "GenMsgCycleTime" BO_ 2566844078 30000;
BA_ "VssMsg" BO_ 2566844078 "Mch.EGOQS.OT1";
BA_ "Channel" BO_ 2566844078 "can2";
BA_ "GenMsgCycleTime" BO_ 2566844160 500;
BA_ "VssMsg" BO_ 2566844160 "Mch.ECU.EFLP1";
BA_ "Channel" BO_ 2566844160 "can1";
BA_ "GenMsgCycleTime" BO_ 2566844672 100;
BA_ "VssMsg" BO_ 2566844672 "Mch.ECU.CCVS";
BA_ "Channel" BO_ 2566844672 "can1";
BA_ "GenMsgCycleTime" BO_ 2566844675 100;
BA_ "VssMsg" BO_ 2566844675 "Mch.TCU.CCVS";
BA_ "Channel" BO_ 2566844675 "can1";
BA_ "GenMsgCycleTime" BO_ 2566844705 100;
BA_ "VssMsg" BO_ 2566844705 "Mch.MCU.CCVS";
BA_ "Channel" BO_ 2566844705 "can1";
BA_ "GenMsgCycleTime" BO_ 2566844928 100;
BA_ "VssMsg" BO_ 2566844928 "Mch.ECU.LFE1";
BA_ "Channel" BO_ 2566844928 "can1";
BA_ "GenMsgCycleTime" BO_ 2566845696 1000;
BA_ "VssMsg" BO_ 2566845696 "Mch.ECU.AMB";
BA_ "Channel" BO_ 2566845696 "can1";
BA_ "GenMsgCycleTime" BO_ 2566845952 500;
BA_ "VssMsg" BO_ 2566845952 "Mch.ECU.IC1";
BA_ "Channel" BO_ 2566845952 "can1";
BA_ "GenMsgCycleTime" BO_ 2566846208 1000;
BA_ "VssMsg" BO_ 2566846208 "Mch.ECU.VEP1";
BA_ "Channel" BO_ 2566846208 "can1";
BA_ "GenMsgCycleTime" BO_ 2566846467 1000;
BA_ "VssMsg" BO_ 2566846467 "Mch.TCU.TF";
BA_ "Channel" BO_ 2566846467 "can1";
BA_ "GenMsgCycleTime" BO_ 2566846981 1000;
BA_ "VssMsg" BO_ 2566846981 "Mch.FNR.B1";
BA_ "Channel" BO_ 2566846981 "can1";
BA_ "GenMsgCycleTime" BO_ 2566847235 1000;
BA_ "VssMsg" BO_ 2566847235 "Mch.TCU.RF";
BA_ "Channel" BO_ 2566847235 "can1";
BA_ "GenMsgCycleTime" BO_ 2566847511 1000;
BA_ "VssMsg" BO_ 2566847511 "Mch.CLST.DD1";
BA_ "Channel" BO_ 2566847511 "can1";
BA_ "GenMsgCycleTime" BO_ 2566847521 1000;
BA_ "VssMsg" BO_ 2566847521 "Mch.MCU.DD1";
BA_ "Channel" BO_ 2566847521 "can1";
BA_ "GenMsgCycleTime" BO_ 2566848256 10000;
BA_ "VssMsg" BO_ 2566848256 "Mch.ECU.WFI";
BA_ "Channel" BO_ 2566848256 "can1";
BA_ "GenMsgCycleTime" BO_ 2566849085 100;
BA_ "VssMsg" BO_ 2566849085 "Mch.EEC.TXEGSPM";
BA_ "Channel" BO_ 2566849085 "can1";
BA_ "GenMsgCycleTime" BO_ 2566851074 100;
BA_ "VssMsg" BO_ 2566851074 "Mch.ECU.ACTVCODERx";
BA_ "Channel" BO_ 2566851074 "can1";
BA_ "GenMsgCycleTime" BO_ 2566852897 10;
BA_ "VssMsg" BO_ 2566852897 "Mch.MCU.SMVCU";
BA_ "Channel" BO_ 2566852897 "can1";
BA_ "GenMsgCycleTime" BO_ 2365527585 50;
BA_ "VssMsg" BO_ 2365527585 "Mch.MCU.ASDJPR";
BA_ "Channel" BO_ 2365527585 "can1";
BA_ "GenMsgCycleTime" BO_ 2365527841 50;
BA_ "VssMsg" BO_ 2365527841 "Mch.MCU.ASDJRD";
BA_ "Channel" BO_ 2365527841 "can1";
BA_ "GenMsgCycleTime" BO_ 2365528097 100;
BA_ "VssMsg" BO_ 2365528097 "Mch.MCU.VSPR";
BA_ "Channel" BO_ 2365528097 "can1";
BA_ "GenMsgCycleTime" BO_ 2365528353 100;
BA_ "VssMsg" BO_ 2365528353 "Mch.MCU.VSRD";
BA_ "Channel" BO_ 2365528353 "can1";
BA_ "GenMsgCycleTime" BO_ 2566856451 100;
BA_ "VssMsg" BO_ 2566856451 "Mch.TCU.TCU2";
BA_ "Channel" BO_ 2566856451 "can1";
BA_ "GenMsgCycleTime" BO_ 2566856707 100;
BA_ "VssMsg" BO_ 2566856707 "Mch.TCU.TCU3";
BA_ "Channel" BO_ 2566856707 "can1";
BA_ "VssMsg" BO_ 2365530117 "Mch.FNR.SLP1";
BA_ "Channel" BO_ 2365530117 "can1";
BA_ "GenMsgCycleTime" BO_ 2566856960 100;
BA_ "VssMsg" BO_ 2566856960 "Mch.ECU.EDC2BC";
BA_ "Channel" BO_ 2566856960 "can1";
BA_ "VssMsg" BO_ 2365530373 "Mch.FNR.SLP2";
BA_ "Channel" BO_ 2365530373 "can1";
BA_ "GenMsgCycleTime" BO_ 2566857219 100;
BA_ "VssMsg" BO_ 2566857219 "Mch.TCU.TCU4";
BA_ "Channel" BO_ 2566857219 "can1";
BA_ "GenMsgCycleTime" BO_ 2566857731 100;
BA_ "VssMsg" BO_ 2566857731 "Mch.TCU.ZFCC";
BA_ "Channel" BO_ 2566857731 "can1";
BA_ "VssMsg" BO_ 2566857984 "Mch.ECU.ENGCOND";
BA_ "Channel" BO_ 2566857984 "can1";
BA_ "GenMsgCycleTime" BO_ 2566858752 50;
BA_ "VssMsg" BO_ 2566858752 "Mch.ECU.FanCtl";
BA_ "Channel" BO_ 2566858752 "can1";
BA_ "GenMsgCycleTime" BO_ 2566859297 100;
BA_ "VssMsg" BO_ 2566859297 "Mch.MCU.VEHICLE2";
BA_ "Channel" BO_ 2566859297 "can1";
BA_ "GenMsgCycleTime" BO_ 2566859523 100;
BA_ "VssMsg" BO_ 2566859523 "Mch.TCU.TCU1";
BA_ "Channel" BO_ 2566859523 "can1";
BA_ "GenMsgCycleTime" BO_ 2566860833 100;
BA_ "VssMsg" BO_ 2566860833 "Mch.MCU.VCUHVCI";
BA_ "Channel" BO_ 2566860833 "can1";
BA_ "VssMsg" BO_ 2566861056 "Mch.ECU.TFI4CMD";
BA_ "Channel" BO_ 2566861056 "can1";
BA_ "GenMsgCycleTime" BO_ 2566861119 30000;
BA_ "VssMsg" BO_ 2566861119 "Mch.HDOQS.OSM";
BA_ "Channel" BO_ 2566861119 "can2";
BA_ "GenMsgCycleTime" BO_ 2566861230 30000;
BA_ "VssMsg" BO_ 2566861230 "Mch.EGOQS.OSM";
BA_ "Channel" BO_ 2566861230 "can2";
BA_ "GenMsgCycleTime" BO_ 2566863330 10;
BA_ "VssMsg" BO_ 2566863330 "Mch.LC510.TFI4Data";
BA_ "Channel" BO_ 2566863330 "can1";
BA_ "VssMsg" BO_ 2566863533 "Mch.OBC.OBCMI";
BA_ "Channel" BO_ 2566863533 "can1";
BA_ "GenMsgCycleTime" BO_ 2566864354 50;
BA_ "VssMsg" BO_ 2566864354 "Mch.LC510.RxTFI4OBD";
BA_ "Channel" BO_ 2566864354 "can1";
BA_ "GenMsgCycleTime" BO_ 2566864627 100;
BA_ "VssMsg" BO_ 2566864627 "Mch.AGW.BMSSG";
BA_ "Channel" BO_ 2566864627 "can1";
BA_ "VssMsg" BO_ 2566864680 "Mch.GP.USUHDI";
BA_ "Channel" BO_ 2566864680 "can1";
BA_ "GenMsgCycleTime" BO_ 2566864929 200;
BA_ "VssMsg" BO_ 2566864929 "Mch.MCU.WSG1";
BA_ "Channel" BO_ 2566864929 "can1";
BA_ "GenMsgCycleTime" BO_ 2566865185 200;
BA_ "VssMsg" BO_ 2566865185 "Mch.MCU.WSG2";
BA_ "Channel" BO_ 2566865185 "can1";
BA_ "GenMsgCycleTime" BO_ 2566865441 200;
BA_ "VssMsg" BO_ 2566865441 "Mch.MCU.WSG3";
BA_ "Channel" BO_ 2566865441 "can1";
BA_ "GenMsgCycleTime" BO_ 2566865697 200;
BA_ "VssMsg" BO_ 2566865697 "Mch.MCU.SIG1";
BA_ "Channel" BO_ 2566865697 "can1";
BA_ "GenMsgCycleTime" BO_ 2566865953 200;
BA_ "VssMsg" BO_ 2566865953 "Mch.MCU.SIG2";
BA_ "Channel" BO_ 2566865953 "can1";
BA_ "VssMsg" BO_ 2566866179 "Mch.TCU.ZFETC9";
BA_ "Channel" BO_ 2566866179 "can1";
BA_ "GenMsgCycleTime" BO_ 2566866209 200;
BA_ "VssMsg" BO_ 2566866209 "Mch.MCU.GPG";
BA_ "Channel" BO_ 2566866209 "can1";
BA_ "GenMsgCycleTime" BO_ 2566866465 200;
BA_ "VssMsg" BO_ 2566866465 "Mch.MCU.UPD";
BA_ "Channel" BO_ 2566866465 "can1";
BA_ "GenMsgCycleTime" BO_ 2566866721 200;
BA_ "VssMsg" BO_ 2566866721 "Mch.MCU.SIG3";
BA_ "Channel" BO_ 2566866721 "can1";
BA_ "VssSig" SG_ 3221225472 KnmtVcstyofEgOil "Mch.TGU.KVO.KnmtVcstyofEgOil";
BA_ "VssSig" SG_ 3221225472 KnmtVcstyofHyhOil "Mch.TGU.KVO.KnmtVcstyofHyhOil";
BA_ "VssSig" SG_ 3221225472 LwThKnmtVcstyofEgOil "Mch.TGU.TEO.LwThKnmtVcstyofEgOil";
BA_ "VssSig" SG_ 3221225472 UpThKnmtVcstyofEgOil "Mch.TGU.TEO.UpThKnmtVcstyofEgOil";
BA_ "VssSig" SG_ 3221225472 LwThDielecCstofEgOil "Mch.TGU.TEO.LwThDielecCstofEgOil";
BA_ "VssSig" SG_ 3221225472 UpThDielecCstofEgOil "Mch.TGU.TEO.UpThDielecCstofEgOil";
BA_ "VssSig" SG_ 3221225472 LwThKnmtVcstyofHyhOil "Mch.TGU.THO.LwThKnmtVcstyofHyhOil";
BA_ "VssSig" SG_ 3221225472 UpThKnmtVcstyofHyhOil "Mch.TGU.THO.UpThKnmtVcstyofHyhOil";
BA_ "VssSig" SG_ 3221225472 LwThDielecCstofHyhOil "Mch.TGU.THO.LwThDielecCstofHyhOil";
BA_ "VssSig" SG_ 3221225472 UpThDielecCstofHyhOil "Mch.TGU.THO.UpThDielecCstofHyhOil";
BA_ "VssSig" SG_ 3221225472 WarnPopHyhOilQual "Mch.TGU.PHMWG.WarnPopHyhOilQual";
BA_ "VssSig" SG_ 3221225472 WarnPopEgOilQual "Mch.TGU.PHMWG.WarnPopEgOilQual";
BA_ "VssSig" SG_ 3221225472 SwVer "Mch.TGU.TMSI.SwVer";
BA_ "VssSig" SG_ 3221225472 KnlVer "Mch.TGU.TMSI.KnlVer";
BA_ "VssSig" SG_ 3221225472 ProdDate "Mch.TGU.TMSI.ProdDate";
BA_ "VssSig" SG_ 3221225472 TGUId "Mch.TGU.TMSI.TGUId";
BA_ "VssSig" SG_ 3221225472 TypeCd "Mch.TGU.TMSI.TypeCd";
BA_ "VssSig" SG_ 2583662767 WarnPopEgOilQual "Mch.TGU.PHMWG.WarnPopEgOilQual";
BA_ "VssSig" SG_ 2583662767 WarnPopHyhOilQual "Mch.TGU.PHMWG.WarnPopHyhOilQual";
BA_ "VssSig" SG_ 2348810243 EgReqTrqTrqLmt "Mch.TCU.TSC1.EgReqTrqTrqLmt";
BA_ "VssSig" SG_ 2348810243 EgReqSpdSpdLmt "Mch.TCU.TSC1.EgReqSpdSpdLmt";
BA_ "VssSig" SG_ 2348810243 OvrCtrlMdPri "Mch.TCU.TSC1.OvrCtrlMdPri";
BA_ "VssSig" SG_ 2348810243 EgOvrCtrlMd "Mch.TCU.TSC1.EgOvrCtrlMd";
BA_ "VssSig" SG_ 2348810251 EgReqTrqTrqLmt "Mch.BRK.TSC1.EgReqTrqTrqLmt";
BA_ "VssSig" SG_ 2348810251 EgReqSpdSpdLmt "Mch.BRK.TSC1.EgReqSpdSpdLmt";
BA_ "VssSig" SG_ 2348810251 OvrCtrlMdPri "Mch.BRK.TSC1.OvrCtrlMdPri";
BA_ "VssSig" SG_ 2348810251 EgOvrCtrlMd "Mch.BRK.TSC1.EgOvrCtrlMd";
BA_ "VssSig" SG_ 2348810259 EgReqTrqTrqLmt "Mch.ESP.TSC1.EgReqTrqTrqLmt";
BA_ "VssSig" SG_ 2348810259 EgReqSpdSpdLmt "Mch.ESP.TSC1.EgReqSpdSpdLmt";
BA_ "VssSig" SG_ 2348810259 OvrCtrlMdPri "Mch.ESP.TSC1.OvrCtrlMdPri";
BA_ "VssSig" SG_ 2348810259 EgOvrCtrlMd "Mch.ESP.TSC1.EgOvrCtrlMd";
BA_ "VssSig" SG_ 2348810273 EgReqTrqTrqLmt "Mch.MCU.TSC1.EgReqTrqTrqLmt";
BA_ "VssSig" SG_ 2348810273 EgReqSpdSpdLmt "Mch.MCU.TSC1.EgReqSpdSpdLmt";
BA_ "VssSig" SG_ 2348810273 OvrCtrlMdPri "Mch.MCU.TSC1.OvrCtrlMdPri";
BA_ "VssSig" SG_ 2348810273 EgOvrCtrlMd "Mch.MCU.TSC1.EgOvrCtrlMd";
BA_ "VssSig" SG_ 2564816912 AtRgnFrcSw "Mch.RDD.CM1.AtRgnFrcSw";
BA_ "VssSig" SG_ 2564816912 AtRgnInhbSw "Mch.RDD.CM1.AtRgnInhbSw";
BA_ "VssSig" SG_ 2564816929 AtRgnFrcSw "Mch.MCU.CM1.AtRgnFrcSw";
BA_ "VssSig" SG_ 2564816929 AtRgnInhbSw "Mch.MCU.CM1.AtRgnInhbSw";
BA_ "VssSig" SG_ 2565865733 EgAuxShdnSw "Mch.FNR.EBC1.EgAuxShdnSw";
BA_ "VssSig" SG_ 2565865739 EgAuxShdnSw "Mch.BRK.EBC1.EgAuxShdnSw";
BA_ "VssSig" SG_ 2364539395 TrmInShftSpd "Mch.TCU.ETC1.TrmInShftSpd";
BA_ "VssSig" SG_ 2364539395 TrmsOutShftSpd "Mch.TCU.ETC1.TrmsOutShftSpd";
BA_ "VssSig" SG_ 2364539395 InProTrmShft "Mch.TCU.ETC1.InProTrmShft";
BA_ "VssSig" SG_ 2364539395 TrqCvtLckEng "Mch.TCU.ETC1.TrqCvtLckEng";
BA_ "VssSig" SG_ 2364539395 TrmDrvEng "Mch.TCU.ETC1.TrmDrvEng";
BA_ "VssSig" SG_ 2364539648 AccPdlPos2 "Mch.ECU.EEC2.AccPdlPos2";
BA_ "VssSig" SG_ 2364539648 EgPctLoadCurSpd "Mch.ECU.EEC2.EgPctLoadCurSpd";
BA_ "VssSig" SG_ 2364539648 AccPdlPos1 "Mch.ECU.EEC2.AccPdlPos1";
BA_ "VssSig" SG_ 2364539904 EgSpd "Mch.ECU.EEC1.EgSpd";
BA_ "VssSig" SG_ 2364539904 ActEgPctTrq "Mch.ECU.EEC1.ActEgPctTrq";
BA_ "VssSig" SG_ 2364539904 DrvDmdEgPctTrq "Mch.ECU.EEC1.DrvDmdEgPctTrq";
BA_ "VssSig" SG_ 2565866755 TrmsCurGr "Mch.TCU.ETC2.TrmsCurGr";
BA_ "VssSig" SG_ 2565866755 TrmsActGrRatio "Mch.TCU.ETC2.TrmsActGrRatio";
BA_ "VssSig" SG_ 2565866755 TrmsSelGr "Mch.TCU.ETC2.TrmsSelGr";
BA_ "VssSig" SG_ 2565867011 DifLckStCtrEng "Mch.TCU.EAC1.DifLckStCtrEng";
BA_ "VssSig" SG_ 2364542241 BladeAutoMdCmd "Mch.MCU.LOI.BladeAutoMdCmd";
BA_ "VssSig" SG_ 2364542241 DsrGrdOfsSw "Mch.MCU.LOI.DsrGrdOfsSw";
BA_ "VssSig" SG_ 2364542241 BladeCtrlMdSw "Mch.MCU.LOI.BladeCtrlMdSw";
BA_ "VssSig" SG_ 2565869137 AtIntGasSsHtCtrl "Mch.KPD2.AT1IG1.AtIntGasSsHtCtrl";
BA_ "VssSig" SG_ 2565869137 InRngAtIntGasSsTmp "Mch.KPD2.AT1IG1.InRngAtIntGasSsTmp";
BA_ "VssSig" SG_ 2565869394 AtOutGasSsHtCtrl "Mch.ATSGO.AT1OG1.AtOutGasSsHtCtrl";
BA_ "VssSig" SG_ 2565869394 InRngAtOutGasSsTmp "Mch.ATSGO.AT1OG1.InRngAtOutGasSsTmp";
BA_ "VssSig" SG_ 2633828415 Oildieleccst "Mch.HDOQS.OQM1.Oildieleccst";
BA_ "VssSig" SG_ 2633828415 Oildensity "Mch.HDOQS.OQM1.Oildensity";
BA_ "VssSig" SG_ 2633828415 OilVcsty "Mch.HDOQS.OQM1.OilVcsty";
BA_ "VssSig" SG_ 2633828526 Oildieleccst "Mch.EGOQS.OQM1.Oildieleccst";
BA_ "VssSig" SG_ 2633828526 Oildensity "Mch.EGOQS.OQM1.Oildensity";
BA_ "VssSig" SG_ 2633828526 OilVcsty "Mch.EGOQS.OQM1.OilVcsty";
BA_ "VssSig" SG_ 2566748928 DpfSootLoadPct "Mch.ECU.AT1S.DpfSootLoadPct";
BA_ "VssSig" SG_ 2566749184 ExhHhTmpLmpCmd "Mch.ECU.PTC1.ExhHhTmpLmpCmd";
BA_ "VssSig" SG_ 2566749184 DpfActRgnIhbSw "Mch.ECU.PTC1.DpfActRgnIhbSw";
BA_ "VssSig" SG_ 2566749184 DpfActRgnSt "Mch.ECU.PTC1.DpfActRgnSt";
BA_ "VssSig" SG_ 2566749184 DpfFiltLmpCmd "Mch.ECU.PTC1.DpfFiltLmpCmd";
BA_ "VssSig" SG_ 2566755587 TrqCvtOilOutTmp "Mch.TCU.TRF2.TrqCvtOilOutTmp";
BA_ "VssSig" SG_ 2566755587 TrmOilFiltRstrSw "Mch.TCU.TRF2.TrmOilFiltRstrSw";
BA_ "VssSig" SG_ 2566757120 AtDefPpt "Mch.ECU.A1DEFI1.AtDefPpt";
BA_ "VssSig" SG_ 2566757120 AtDefCct "Mch.ECU.A1DEFI1.AtDefCct";
BA_ "VssSig" SG_ 2566758656 AtFuelInjHtCtrl "Mch.ECU.AT1FC1.AtFuelInjHtCtrl";
BA_ "VssSig" SG_ 2566758656 AtIgn "Mch.ECU.AT1FC1.AtIgn";
BA_ "VssSig" SG_ 2566758656 AtFuelPrsCtrl "Mch.ECU.AT1FC1.AtFuelPrsCtrl";
BA_ "VssSig" SG_ 2566758656 AtFuelRate "Mch.ECU.AT1FC1.AtFuelRate";
BA_ "VssSig" SG_ 2566758656 AtFuelPrs "Mch.ECU.AT1FC1.AtFuelPrs";
BA_ "VssSig" SG_ 2566763264 AtDpfOutGasTmp "Mch.ECU.AT1OG2.AtDpfOutGasTmp";
BA_ "VssSig" SG_ 2566763325 AtDpfOutGasTmp "Mch.EEC.AT1OG2.AtDpfOutGasTmp";
BA_ "VssSig" SG_ 2566763520 AtDpfIntGasTmp "Mch.ECU.AT1IG2.AtDpfIntGasTmp";
BA_ "VssSig" SG_ 2566763520 AtExhGasTmp "Mch.ECU.AT1IG2.AtExhGasTmp";
BA_ "VssSig" SG_ 2566763581 AtDpfIntGasTmp "Mch.EEC.AT1IG2.AtDpfIntGasTmp";
BA_ "VssSig" SG_ 2566763581 AtExhGasTmp "Mch.EEC.AT1IG2.AtExhGasTmp";
BA_ "VssSig" SG_ 2566771968 EgEgrVvCtrl "Mch.ECU.EEC5.EgEgrVvCtrl";
BA_ "VssSig" SG_ 2365468962 PortFlowHighResolution "Mch.TRBDZ.AV01C.PortFlowHighResolution";
BA_ "VssSig" SG_ 2365468962 FailSafeMd "Mch.TRBDZ.AV01C.FailSafeMd";
BA_ "VssSig" SG_ 2365468962 VvSt "Mch.TRBDZ.AV01C.VvSt";
BA_ "VssSig" SG_ 2365468962 ResolutionMd "Mch.TRBDZ.AV01C.ResolutionMd";
BA_ "VssSig" SG_ 2365468962 AuxVv1PortFlowCmd "Mch.TRBDZ.AV01C.AuxVv1PortFlowCmd";
BA_ "VssSig" SG_ 2365469218 PortFlowHighResolution "Mch.TRBDZ.AV02C.PortFlowHighResolution";
BA_ "VssSig" SG_ 2365469218 FailSafeMd "Mch.TRBDZ.AV02C.FailSafeMd";
BA_ "VssSig" SG_ 2365469218 VvSt "Mch.TRBDZ.AV02C.VvSt";
BA_ "VssSig" SG_ 2365469218 ResolutionMd "Mch.TRBDZ.AV02C.ResolutionMd";
BA_ "VssSig" SG_ 2365469218 AuxVv1PortFlowCmd "Mch.TRBDZ.AV02C.AuxVv1PortFlowCmd";
BA_ "VssSig" SG_ 2566802176 EgThrtActCtrlCmd "Mch.ECU.TCFG2.EgThrtActCtrlCmd";
BA_ "VssSig" SG_ 2566804992 AtSelCatalRedOprIndAct "Mch.ECU.AT1T1I1.AtSelCatalRedOprIndAct";
BA_ "VssSig" SG_ 2566804992 AtDefTnkTmp "Mch.ECU.AT1T1I1.AtDefTnkTmp";
BA_ "VssSig" SG_ 2566804992 AtDefTnkLv "Mch.ECU.AT1T1I1.AtDefTnkLv";
BA_ "VssSig" SG_ 2566804993 AtSelCatalRedOprIndAct "Mch.ECU1.AT1T1I1.AtSelCatalRedOprIndAct";
BA_ "VssSig" SG_ 2566804993 AtDefTnkTmp "Mch.ECU1.AT1T1I1.AtDefTnkTmp";
BA_ "VssSig" SG_ 2566804993 AtDefTnkLv "Mch.ECU1.AT1T1I1.AtDefTnkLv";
BA_ "VssSig" SG_ 2566840064 At1ExhGasMasFlw "Mch.ECU.EEC3.At1ExhGasMasFlw";
BA_ "VssSig" SG_ 2566840064 EgDsrOprSpd "Mch.ECU.EEC3.EgDsrOprSpd";
BA_ "VssSig" SG_ 2566840064 NrmFricPctTrq "Mch.ECU.EEC3.NrmFricPctTrq";
BA_ "VssSig" SG_ 2566841600 EgTotRev "Mch.ECU.HOURS.EgTotRev";
BA_ "VssSig" SG_ 2566841600 EgTotHrOpr "Mch.ECU.HOURS.EgTotHrOpr";
BA_ "VssSig" SG_ 2566842624 EgTotFuelUsed "Mch.ECU.LFC1.EgTotFuelUsed";
BA_ "VssSig" SG_ 2566842624 EgTripFuel "Mch.ECU.LFC1.EgTripFuel";
BA_ "VssSig" SG_ 2566843904 EgFuelTmp "Mch.ECU.ET1.EgFuelTmp";
BA_ "VssSig" SG_ 2566843904 EgCoolTmp "Mch.ECU.ET1.EgCoolTmp";
BA_ "VssSig" SG_ 2566843967 OilAvrgTmp "Mch.HDOQS.OT1.OilAvrgTmp";
BA_ "VssSig" SG_ 2566844078 OilAvrgTmp "Mch.EGOQS.OT1.OilAvrgTmp";
BA_ "VssSig" SG_ 2566844160 EgCoolLv "Mch.ECU.EFLP1.EgCoolLv";
BA_ "VssSig" SG_ 2566844160 EgCrkcasePrs "Mch.ECU.EFLP1.EgCrkcasePrs";
BA_ "VssSig" SG_ 2566844160 EgOilPrs "Mch.ECU.EFLP1.EgOilPrs";
BA_ "VssSig" SG_ 2566844160 EgFuelDlvPrs "Mch.ECU.EFLP1.EgFuelDlvPrs";
BA_ "VssSig" SG_ 2566844672 WhlVhcSpd "Mch.ECU.CCVS.WhlVhcSpd";
BA_ "VssSig" SG_ 2566844675 WhlVhcSpd "Mch.TCU.CCVS.WhlVhcSpd";
BA_ "VssSig" SG_ 2566844705 WhlVhcSpd "Mch.MCU.CCVS.WhlVhcSpd";
BA_ "VssSig" SG_ 2566844928 EgThrtVvPos "Mch.ECU.LFE1.EgThrtVvPos";
BA_ "VssSig" SG_ 2566844928 EgFuelRate "Mch.ECU.LFE1.EgFuelRate";
BA_ "VssSig" SG_ 2566845696 EgAirIntTmp "Mch.ECU.AMB.EgAirIntTmp";
BA_ "VssSig" SG_ 2566845696 AmbAirTmp "Mch.ECU.AMB.AmbAirTmp";
BA_ "VssSig" SG_ 2566845696 BaroPrs "Mch.ECU.AMB.BaroPrs";
BA_ "VssSig" SG_ 2566845952 EgAirIntPrs "Mch.ECU.IC1.EgAirIntPrs";
BA_ "VssSig" SG_ 2566845952 EgIntMnfdTmp "Mch.ECU.IC1.EgIntMnfdTmp";
BA_ "VssSig" SG_ 2566845952 EgIntMnfdPrs "Mch.ECU.IC1.EgIntMnfdPrs";
BA_ "VssSig" SG_ 2566846208 KeyswBatPtc "Mch.ECU.VEP1.KeyswBatPtc";
BA_ "VssSig" SG_ 2566846208 BatPtcPowIn "Mch.ECU.VEP1.BatPtcPowIn";
BA_ "VssSig" SG_ 2566847235 TrmOilFiltRstrSw "Mch.TCU.RF.TrmOilFiltRstrSw";
BA_ "VssSig" SG_ 2566852897 MsgCs "Mch.MCU.SMVCU.MsgCs";
BA_ "VssSig" SG_ 2566852897 MsgCnt "Mch.MCU.SMVCU.MsgCnt";
BA_ "VssSig" SG_ 2566852897 PrkBrkSw "Mch.MCU.SMVCU.PrkBrkSw";
BA_ "VssSig" SG_ 2566852897 StartCtrlReq "Mch.MCU.SMVCU.StartCtrlReq";
BA_ "VssSig" SG_ 2566852897 VhcSpd "Mch.MCU.SMVCU.VhcSpd";
BA_ "VssSig" SG_ 2566852897 CCAccSw "Mch.MCU.SMVCU.CCAccSw";
BA_ "VssSig" SG_ 2566852897 CCRsmSw "Mch.MCU.SMVCU.CCRsmSw";
BA_ "VssSig" SG_ 2566852897 CCCoastSw "Mch.MCU.SMVCU.CCCoastSw";
BA_ "VssSig" SG_ 2566852897 CCSetSw "Mch.MCU.SMVCU.CCSetSw";
BA_ "VssSig" SG_ 2566852897 PtoSt "Mch.MCU.SMVCU.PtoSt";
BA_ "VssSig" SG_ 2566852897 RddtBrk "Mch.MCU.SMVCU.RddtBrk";
BA_ "VssSig" SG_ 2566852897 BrkSw "Mch.MCU.SMVCU.BrkSw";
BA_ "VssSig" SG_ 2566852897 LisSw "Mch.MCU.SMVCU.LisSw";
BA_ "VssSig" SG_ 2566852897 FinAccPdlPos "Mch.MCU.SMVCU.FinAccPdlPos";
BA_ "VssSig" SG_ 2365527585 Crc16forDtbytes "Mch.MCU.ASDJPR.Crc16forDtbytes";
BA_ "VssSig" SG_ 2365527585 Errorcode "Mch.MCU.ASDJPR.Errorcode";
BA_ "VssSig" SG_ 2365527585 SequenceNo "Mch.MCU.ASDJPR.SequenceNo";
BA_ "VssSig" SG_ 2365527585 JoyEnbsignal "Mch.MCU.ASDJPR.JoyEnbsignal";
BA_ "VssSig" SG_ 2365527585 JoyNtrlPostrim "Mch.MCU.ASDJPR.JoyNtrlPostrim";
BA_ "VssSig" SG_ 2365527585 JoyPos "Mch.MCU.ASDJPR.JoyPos";
BA_ "VssSig" SG_ 2365527841 Crc16forDtbytes "Mch.MCU.ASDJRD.Crc16forDtbytes";
BA_ "VssSig" SG_ 2365527841 Errorcode "Mch.MCU.ASDJRD.Errorcode";
BA_ "VssSig" SG_ 2365527841 SequenceNo "Mch.MCU.ASDJRD.SequenceNo";
BA_ "VssSig" SG_ 2365527841 JoyEnbsignal "Mch.MCU.ASDJRD.JoyEnbsignal";
BA_ "VssSig" SG_ 2365527841 JoyNtrlPostrim "Mch.MCU.ASDJRD.JoyNtrlPostrim";
BA_ "VssSig" SG_ 2365527841 JoyPos "Mch.MCU.ASDJRD.JoyPos";
BA_ "VssSig" SG_ 2365528097 Crc16forDtbytes "Mch.MCU.VSPR.Crc16forDtbytes";
BA_ "VssSig" SG_ 2365528097 SequenceNo "Mch.MCU.VSPR.SequenceNo";
BA_ "VssSig" SG_ 2365528097 VhcSpd "Mch.MCU.VSPR.VhcSpd";
BA_ "VssSig" SG_ 2365528097 DirIndication "Mch.MCU.VSPR.DirIndication";
BA_ "VssSig" SG_ 2365528353 Crc16forDtbytes "Mch.MCU.VSRD.Crc16forDtbytes";
BA_ "VssSig" SG_ 2365528353 SequenceNo "Mch.MCU.VSRD.SequenceNo";
BA_ "VssSig" SG_ 2365528353 VhcSpd "Mch.MCU.VSRD.VhcSpd";
BA_ "VssSig" SG_ 2365528353 Drtindication "Mch.MCU.VSRD.Drtindication";
BA_ "VssSig" SG_ 2566856960 DpfSootLv "Mch.ECU.EDC2BC.DpfSootLv";
BA_ "VssSig" SG_ 2566856960 EdcOprSt "Mch.ECU.EDC2BC.EdcOprSt";
BA_ "VssSig" SG_ 2566856960 EgDgrdLv "Mch.ECU.EDC2BC.EgDgrdLv";
BA_ "VssSig" SG_ 2566856960 EgOilTmpHh "Mch.ECU.EDC2BC.EgOilTmpHh";
BA_ "VssSig" SG_ 2566856960 FuelFiltHtSt "Mch.ECU.EDC2BC.FuelFiltHtSt";
BA_ "VssSig" SG_ 2566856960 WifWrn "Mch.ECU.EDC2BC.WifWrn";
BA_ "VssSig" SG_ 2566856960 EgOilPrsLw "Mch.ECU.EDC2BC.EgOilPrsLw";
BA_ "VssSig" SG_ 2566856960 BtnStp "Mch.ECU.EDC2BC.BtnStp";
BA_ "VssSig" SG_ 2566856960 RgnLmp "Mch.ECU.EDC2BC.RgnLmp";
BA_ "VssSig" SG_ 2566856960 HydPmpActReq "Mch.ECU.EDC2BC.HydPmpActReq";
BA_ "VssSig" SG_ 2566856960 MIL "Mch.ECU.EDC2BC.MIL";
BA_ "VssSig" SG_ 2566856960 EgOvrSpd "Mch.ECU.EDC2BC.EgOvrSpd";
BA_ "VssSig" SG_ 2566856960 SpdLmtLmp "Mch.ECU.EDC2BC.SpdLmtLmp";
BA_ "VssSig" SG_ 2566856960 DiagLmp "Mch.ECU.EDC2BC.DiagLmp";
BA_ "VssSig" SG_ 2566856960 FuelBlock "Mch.ECU.EDC2BC.FuelBlock";
BA_ "VssSig" SG_ 2566856960 ColdStartHt "Mch.ECU.EDC2BC.ColdStartHt";
BA_ "VssSig" SG_ 2566857219 CnvtTurbTrq "Mch.TCU.TCU4.CnvtTurbTrq";
BA_ "VssSig" SG_ 2566857219 CnvtPmpTrq "Mch.TCU.TCU4.CnvtPmpTrq";
BA_ "VssSig" SG_ 2566857984 PhsDifCrkCam "Mch.ECU.ENGCOND.PhsDifCrkCam";
BA_ "VssSig" SG_ 2566857984 EgOprCmd "Mch.ECU.ENGCOND.EgOprCmd";
BA_ "VssSig" SG_ 2566857984 AirMassPrs "Mch.ECU.ENGCOND.AirMassPrs";
BA_ "VssSig" SG_ 2566858752 RedFanSpd100 "Mch.ECU.FanCtl.RedFanSpd100";
BA_ "VssSig" SG_ 2566858752 RedFanSpd70 "Mch.ECU.FanCtl.RedFanSpd70";
BA_ "VssSig" SG_ 2566858752 RedFanSpd50 "Mch.ECU.FanCtl.RedFanSpd50";
BA_ "VssSig" SG_ 2566858752 RedFanSpd30 "Mch.ECU.FanCtl.RedFanSpd30";
BA_ "VssSig" SG_ 2566858752 RedFanSpd0 "Mch.ECU.FanCtl.RedFanSpd0";
BA_ "VssSig" SG_ 2566859523 IsEngDrvSt "Mch.TCU.TCU1.IsEngDrvSt";
BA_ "VssSig" SG_ 2566859523 InProcShftSt "Mch.TCU.TCU1.InProcShftSt";
BA_ "VssSig" SG_ 2566859523 OpMd "Mch.TCU.TCU1.OpMd";
BA_ "VssSig" SG_ 2566859523 IsActJoyMd "Mch.TCU.TCU1.IsActJoyMd";
BA_ "VssSig" SG_ 2566859523 CurDir "Mch.TCU.TCU1.CurDir";
BA_ "VssSig" SG_ 2566859523 CurGr "Mch.TCU.TCU1.CurGr";
BA_ "VssSig" SG_ 2566859523 DifLck "Mch.TCU.TCU1.DifLck";
BA_ "VssSig" SG_ 2566859523 ShftDir "Mch.TCU.TCU1.ShftDir";
BA_ "VssSig" SG_ 2566859523 ShftRng "Mch.TCU.TCU1.ShftRng";
BA_ "VssSig" SG_ 2566859523 ErrCode "Mch.TCU.TCU1.ErrCode";
BA_ "VssSig" SG_ 2566859523 OutSpd "Mch.TCU.TCU1.OutSpd";
BA_ "VssSig" SG_ 2566859523 EgSpd "Mch.TCU.TCU1.EgSpd";
BA_ "VssSig" SG_ 2566860833 ChgSt "Mch.MCU.VCUHVCI.ChgSt";
BA_ "VssSig" SG_ 2566860833 MchKeyOnSt "Mch.MCU.VCUHVCI.MchKeyOnSt";
BA_ "VssSig" SG_ 2566860833 OnBrdChgCmd "Mch.MCU.VCUHVCI.OnBrdChgCmd";
BA_ "VssSig" SG_ 2566860833 QckChgEnableCmd "Mch.MCU.VCUHVCI.QckChgEnableCmd";
BA_ "VssSig" SG_ 2566860833 PwrDnCmd "Mch.MCU.VCUHVCI.PwrDnCmd";
BA_ "VssSig" SG_ 2566861056 FiltTm "Mch.ECU.TFI4CMD.FiltTm";
BA_ "VssSig" SG_ 2566861056 Cmd "Mch.ECU.TFI4CMD.Cmd";
BA_ "VssSig" SG_ 2566861119 StMsgCode "Mch.HDOQS.OSM.StMsgCode";
BA_ "VssSig" SG_ 2566861230 StMsgCode "Mch.EGOQS.OSM.StMsgCode";
BA_ "VssSig" SG_ 2566863533 FanSt "Mch.OBC.OBCMI.FanSt";
BA_ "VssSig" SG_ 2566863533 PdVlt "Mch.OBC.OBCMI.PdVlt";
BA_ "VssSig" SG_ 2566863533 CpVlt "Mch.OBC.OBCMI.CpVlt";
BA_ "VssSig" SG_ 2566863533 ObcAtmosphereTemp "Mch.OBC.OBCMI.ObcAtmosphereTemp";
BA_ "VssSig" SG_ 2566863533 ObcMaxTemp "Mch.OBC.OBCMI.ObcMaxTemp";
BA_ "VssSig" SG_ 2566863533 PfcVlt "Mch.OBC.OBCMI.PfcVlt";
BA_ "VssSig" SG_ 2566863533 AcInCur "Mch.OBC.OBCMI.AcInCur";
BA_ "VssSig" SG_ 2566863533 AcInFrequency "Mch.OBC.OBCMI.AcInFrequency";
BA_ "VssSig" SG_ 2566863533 AcInVlt "Mch.OBC.OBCMI.AcInVlt";
BA_ "VssSig" SG_ 2566863533 ChgElapsedTm "Mch.OBC.OBCMI.ChgElapsedTm";
BA_ "VssSig" SG_ 2566864627 EstimatedChgTm "Mch.AGW.BMSSG.EstimatedChgTm";
BA_ "VssSig" SG_ 2566864627 ChgSt "Mch.AGW.BMSSG.ChgSt";
BA_ "VssSig" SG_ 2566864627 HtPadSt "Mch.AGW.BMSSG.HtPadSt";
BA_ "VssSig" SG_ 2566864627 BmsChgSrcType "Mch.AGW.BMSSG.BmsChgSrcType";
BA_ "VssSig" SG_ 2566864680 FuelEfficiencybyUser "Mch.GP.USUHDI.FuelEfficiencybyUser";
BA_ "VssSig" SG_ 2566864680 EcnMdFuelUsgbyUser "Mch.GP.USUHDI.EcnMdFuelUsgbyUser";
BA_ "VssSig" SG_ 2566864680 StdMdFuelUsgbyUser "Mch.GP.USUHDI.StdMdFuelUsgbyUser";
BA_ "VssSig" SG_ 2566864680 PwrMdFuelUsgbyUser "Mch.GP.USUHDI.PwrMdFuelUsgbyUser";
BA_ "VssSig" SG_ 2566864680 PwrPlusMdFuelUsgbyUser "Mch.GP.USUHDI.PwrPlusMdFuelUsgbyUser";
BA_ "VssSig" SG_ 2566864680 TotalFuelUsgbyUser "Mch.GP.USUHDI.TotalFuelUsgbyUser";
BA_ "VssSig" SG_ 2566864680 EcnMdOprtgHrbyUser "Mch.GP.USUHDI.EcnMdOprtgHrbyUser";
BA_ "VssSig" SG_ 2566864680 StdMdOprtgHrbyUser "Mch.GP.USUHDI.StdMdOprtgHrbyUser";
BA_ "VssSig" SG_ 2566864680 PwrMdOprtgHrbyUser "Mch.GP.USUHDI.PwrMdOprtgHrbyUser";
BA_ "VssSig" SG_ 2566864680 PwrPlusMdOprtgHrbyUser "Mch.GP.USUHDI.PwrPlusMdOprtgHrbyUser";
BA_ "VssSig" SG_ 2566864680 IdleOprtgHrbyUser "Mch.GP.USUHDI.IdleOprtgHrbyUser";
BA_ "VssSig" SG_ 2566864680 TotalOprtgHrbyUser "Mch.GP.USUHDI.TotalOprtgHrbyUser";
BA_ "VssSig" SG_ 2566864680 UserName "Mch.GP.USUHDI.UserName";
BA_ "VssSig" SG_ 2566864680 UserSeparatorFlag "Mch.GP.USUHDI.UserSeparatorFlag";
BA_ "VssSig" SG_ 2566864680 UserSeparatorSlot "Mch.GP.USUHDI.UserSeparatorSlot";
BA_ "VssSig" SG_ 2566864929 InvOh "Mch.MCU.WSG1.InvOh";
BA_ "VssSig" SG_ 2566864929 MotOh "Mch.MCU.WSG1.MotOh";
BA_ "VssSig" SG_ 2566864929 BatOh "Mch.MCU.WSG1.BatOh";
BA_ "VssSig" SG_ 2566864929 Bms "Mch.MCU.WSG1.Bms";
BA_ "VssSig" SG_ 2566864929 BatHt "Mch.MCU.WSG1.BatHt";
BA_ "VssSig" SG_ 2566864929 TrvlPdlFail "Mch.MCU.WSG1.TrvlPdlFail";
BA_ "VssSig" SG_ 2566864929 RrWhlAlgn "Mch.MCU.WSG1.RrWhlAlgn";
BA_ "VssSig" SG_ 2566864929 PrkBrkPrs "Mch.MCU.WSG1.PrkBrkPrs";
BA_ "VssSig" SG_ 2566864929 TrsmOilFiltClog "Mch.MCU.WSG1.TrsmOilFiltClog";
BA_ "VssSig" SG_ 2566864929 FanMotPrsLw "Mch.MCU.WSG1.FanMotPrsLw";
BA_ "VssSig" SG_ 2566864929 OvSpd "Mch.MCU.WSG1.OvSpd";
BA_ "VssSig" SG_ 2566864929 RBrkPdlNoCalb "Mch.MCU.WSG1.RBrkPdlNoCalb";
BA_ "VssSig" SG_ 2566864929 ElecStr "Mch.MCU.WSG1.ElecStr";
BA_ "VssSig" SG_ 2566864929 EgOvr "Mch.MCU.WSG1.EgOvr";
BA_ "VssSig" SG_ 2566864929 EmgStr "Mch.MCU.WSG1.EmgStr";
BA_ "VssSig" SG_ 2566864929 SeatBelt "Mch.MCU.WSG1.SeatBelt";
BA_ "VssSig" SG_ 2566864929 TrsmOilOh "Mch.MCU.WSG1.TrsmOilOh";
BA_ "VssSig" SG_ 2566864929 Trsm "Mch.MCU.WSG1.Trsm";
BA_ "VssSig" SG_ 2566864929 VboEpprVvOut "Mch.MCU.WSG1.VboEpprVvOut";
BA_ "VssSig" SG_ 2566864929 VboJoySs "Mch.MCU.WSG1.VboJoySs";
BA_ "VssSig" SG_ 2566864929 VboAngSs "Mch.MCU.WSG1.VboAngSs";
BA_ "VssSig" SG_ 2566864929 BatEq "Mch.MCU.WSG1.BatEq";
BA_ "VssSig" SG_ 2566864929 Uss "Mch.MCU.WSG1.Uss";
BA_ "VssSig" SG_ 2566864929 IceptSs "Mch.MCU.WSG1.IceptSs";
BA_ "VssSig" SG_ 2566864929 Str "Mch.MCU.WSG1.Str";
BA_ "VssSig" SG_ 2566864929 BrkOilPrsLw "Mch.MCU.WSG1.BrkOilPrsLw";
BA_ "VssSig" SG_ 2566864929 Ags "Mch.MCU.WSG1.Ags";
BA_ "VssSig" SG_ 2566864929 Owd "Mch.MCU.WSG1.Owd";
BA_ "VssSig" SG_ 2566864929 PilotFilt "Mch.MCU.WSG1.PilotFilt";
BA_ "VssSig" SG_ 2566864929 RetFilt "Mch.MCU.WSG1.RetFilt";
BA_ "VssSig" SG_ 2566864929 HydOilOh "Mch.MCU.WSG1.HydOilOh";
BA_ "VssSig" SG_ 2566864929 BatChg "Mch.MCU.WSG1.BatChg";
BA_ "VssSig" SG_ 2566865185 AcleOilOh "Mch.MCU.WSG2.AcleOilOh";
BA_ "VssSig" SG_ 2566865185 TireTemp "Mch.MCU.WSG2.TireTemp";
BA_ "VssSig" SG_ 2566865185 FuelEmptyAddFuelTnk "Mch.MCU.WSG2.FuelEmptyAddFuelTnk";
BA_ "VssSig" SG_ 2566865185 ePowStp "Mch.MCU.WSG2.ePowStp";
BA_ "VssSig" SG_ 2566865185 ePowChk "Mch.MCU.WSG2.ePowChk";
BA_ "VssSig" SG_ 2566865185 CoolLv "Mch.MCU.WSG2.CoolLv";
BA_ "VssSig" SG_ 2566865185 DefPrsLw "Mch.MCU.WSG2.DefPrsLw";
BA_ "VssSig" SG_ 2566865185 WifMainFiltFault "Mch.MCU.WSG2.WifMainFiltFault";
BA_ "VssSig" SG_ 2566865185 WifMainFiltWaterDetectFault "Mch.MCU.WSG2.WifMainFiltWaterDetectFault";
BA_ "VssSig" SG_ 2566865185 WifPrePilotFault "Mch.MCU.WSG2.WifPrePilotFault";
BA_ "VssSig" SG_ 2566865185 WifPrePilot "Mch.MCU.WSG2.WifPrePilot";
BA_ "VssSig" SG_ 2566865185 FuelEmpty "Mch.MCU.WSG2.FuelEmpty";
BA_ "VssSig" SG_ 2566865185 AutoSCrcondPrkns "Mch.MCU.WSG2.AutoSCrcondPrkns";
BA_ "VssSig" SG_ 2566865185 ExHhTempAmb "Mch.MCU.WSG2.ExHhTempAmb";
BA_ "VssSig" SG_ 2566865185 ExHhTempGr "Mch.MCU.WSG2.ExHhTempGr";
BA_ "VssSig" SG_ 2566865185 DpfActRgnInhbtSt "Mch.MCU.WSG2.DpfActRgnInhbtSt";
BA_ "VssSig" SG_ 2566865185 DpfRgnClg "Mch.MCU.WSG2.DpfRgnClg";
BA_ "VssSig" SG_ 2566865185 EgChkSrv "Mch.MCU.WSG2.EgChkSrv";
BA_ "VssSig" SG_ 2566865185 EgChk2 "Mch.MCU.WSG2.EgChk2";
BA_ "VssSig" SG_ 2566865185 EgChk1 "Mch.MCU.WSG2.EgChk1";
BA_ "VssSig" SG_ 2566865185 EgStp "Mch.MCU.WSG2.EgStp";
BA_ "VssSig" SG_ 2566865185 EgWrn "Mch.MCU.WSG2.EgWrn";
BA_ "VssSig" SG_ 2566865185 AirCln "Mch.MCU.WSG2.AirCln";
BA_ "VssSig" SG_ 2566865185 CoolLvSrgTnk "Mch.MCU.WSG2.CoolLvSrgTnk";
BA_ "VssSig" SG_ 2566865185 CoolTmpOv "Mch.MCU.WSG2.CoolTmpOv";
BA_ "VssSig" SG_ 2566865185 EgOilPrs "Mch.MCU.WSG2.EgOilPrs";
BA_ "VssSig" SG_ 2566865441 TirePrs "Mch.MCU.WSG3.TirePrs";
BA_ "VssSig" SG_ 2566865441 HydOilWarmUp "Mch.MCU.WSG3.HydOilWarmUp";
BA_ "VssSig" SG_ 2566865441 GndSawRdy "Mch.MCU.WSG3.GndSawRdy";
BA_ "VssSig" SG_ 2566865441 TrvMotTempOh "Mch.MCU.WSG3.TrvMotTempOh";
BA_ "VssSig" SG_ 2566865441 QckCouplerLck "Mch.MCU.WSG3.QckCouplerLck";
BA_ "VssSig" SG_ 2566865441 BrkPdlSs "Mch.MCU.WSG3.BrkPdlSs";
BA_ "VssSig" SG_ 2566865441 AtsRgnReq "Mch.MCU.WSG3.AtsRgnReq";
BA_ "VssSig" SG_ 2566865441 TmsConSt "Mch.MCU.WSG3.TmsConSt";
BA_ "VssSig" SG_ 2566865441 QckCouplerUnlock "Mch.MCU.WSG3.QckCouplerUnlock";
BA_ "VssSig" SG_ 2566865441 RmvCntwt "Mch.MCU.WSG3.RmvCntwt";
BA_ "VssSig" SG_ 2566865441 FuelFilt "Mch.MCU.WSG3.FuelFilt";
BA_ "VssSig" SG_ 2566865441 UreaQualScr "Mch.MCU.WSG3.UreaQualScr";
BA_ "VssSig" SG_ 2566865441 UreaLv "Mch.MCU.WSG3.UreaLv";
BA_ "VssSig" SG_ 2566865697 BzzCtrlCmd "Mch.MCU.SIG1.BzzCtrlCmd";
BA_ "VssSig" SG_ 2566865697 CurGr "Mch.MCU.SIG1.CurGr";
BA_ "VssSig" SG_ 2566865697 SelGr "Mch.MCU.SIG1.SelGr";
BA_ "VssSig" SG_ 2566865697 BoomFltBiDir "Mch.MCU.SIG1.BoomFltBiDir";
BA_ "VssSig" SG_ 2566865697 Is3RdFNRElecStr "Mch.MCU.SIG1.Is3RdFNRElecStr";
BA_ "VssSig" SG_ 2566865697 IsFR "Mch.MCU.SIG1.IsFR";
BA_ "VssSig" SG_ 2566865697 IsElecStr "Mch.MCU.SIG1.IsElecStr";
BA_ "VssSig" SG_ 2566865697 IsOprRdy "Mch.MCU.SIG1.IsOprRdy";
BA_ "VssSig" SG_ 2566865697 PreHt "Mch.MCU.SIG1.PreHt";
BA_ "VssSig" SG_ 2566865697 FaultCntAvm "Mch.MCU.SIG1.FaultCntAvm";
BA_ "VssSig" SG_ 2566865697 FaultCntMch "Mch.MCU.SIG1.FaultCntMch";
BA_ "VssSig" SG_ 2566865697 CtrWrnLed "Mch.MCU.SIG1.CtrWrnLed";
BA_ "VssSig" SG_ 2566865697 ExBzz "Mch.MCU.SIG1.ExBzz";
BA_ "VssSig" SG_ 2566865697 AutoShdnAval "Mch.MCU.SIG1.AutoShdnAval";
BA_ "VssSig" SG_ 2566865697 AutoShdnSt "Mch.MCU.SIG1.AutoShdnSt";
BA_ "VssSig" SG_ 2566865697 BrkrAct "Mch.MCU.SIG1.BrkrAct";
BA_ "VssSig" SG_ 2566865697 ThmbWhlLvErr "Mch.MCU.SIG1.ThmbWhlLvErr";
BA_ "VssSig" SG_ 2566865697 AutoIdle "Mch.MCU.SIG1.AutoIdle";
BA_ "VssSig" SG_ 2566865697 RgnPrkns "Mch.MCU.SIG1.RgnPrkns";
BA_ "VssSig" SG_ 2566865697 RpmCtrlRstrt "Mch.MCU.SIG1.RpmCtrlRstrt";
BA_ "VssSig" SG_ 2566865697 IgnRstrtPilotCutOff "Mch.MCU.SIG1.IgnRstrtPilotCutOff";
BA_ "VssSig" SG_ 2566865697 IgnRstrtFRP "Mch.MCU.SIG1.IgnRstrtFRP";
BA_ "VssSig" SG_ 2566865697 OhPrv "Mch.MCU.SIG1.OhPrv";
BA_ "VssSig" SG_ 2566865697 HhMntLgc "Mch.MCU.SIG1.HhMntLgc";
BA_ "VssSig" SG_ 2566865697 AutoShdn "Mch.MCU.SIG1.AutoShdn";
BA_ "VssSig" SG_ 2566865697 FuelHt "Mch.MCU.SIG1.FuelHt";
BA_ "VssSig" SG_ 2566865697 AutoWarmUpGr "Mch.MCU.SIG1.AutoWarmUpGr";
BA_ "VssSig" SG_ 2566865697 AutoWarmUpAmb "Mch.MCU.SIG1.AutoWarmUpAmb";
BA_ "VssSig" SG_ 2566865697 HhBeam "Mch.MCU.SIG1.HhBeam";
BA_ "VssSig" SG_ 2566865697 RamLck "Mch.MCU.SIG1.RamLck";
BA_ "VssSig" SG_ 2566865697 PrkBrk "Mch.MCU.SIG1.PrkBrk";
BA_ "VssSig" SG_ 2566865697 Trv "Mch.MCU.SIG1.Trv";
BA_ "VssSig" SG_ 2566865697 FNR "Mch.MCU.SIG1.FNR";
BA_ "VssSig" SG_ 2566865697 TrvMdWhl "Mch.MCU.SIG1.TrvMdWhl";
BA_ "VssSig" SG_ 2566865697 IsoBhl "Mch.MCU.SIG1.IsoBhl";
BA_ "VssSig" SG_ 2566865697 TwOpt "Mch.MCU.SIG1.TwOpt";
BA_ "VssSig" SG_ 2566865697 WrkMd "Mch.MCU.SIG1.WrkMd";
BA_ "VssSig" SG_ 2566865697 TrvMdCrw "Mch.MCU.SIG1.TrvMdCrw";
BA_ "VssSig" SG_ 2566865697 MrrHt "Mch.MCU.SIG1.MrrHt";
BA_ "VssSig" SG_ 2566865697 AuxMdSt "Mch.MCU.SIG1.AuxMdSt";
BA_ "VssSig" SG_ 2566865697 RvsFanSt "Mch.MCU.SIG1.RvsFanSt";
BA_ "VssSig" SG_ 2566865697 SwPriSt "Mch.MCU.SIG1.SwPriSt";
BA_ "VssSig" SG_ 2566865697 BoomSwAct "Mch.MCU.SIG1.BoomSwAct";
BA_ "VssSig" SG_ 2566865697 BoomFltSngDir "Mch.MCU.SIG1.BoomFltSngDir";
BA_ "VssSig" SG_ 2566865697 PowMax "Mch.MCU.SIG1.PowMax";
BA_ "VssSig" SG_ 2566865697 WrkLmp "Mch.MCU.SIG1.WrkLmp";
BA_ "VssSig" SG_ 2566865953 HstTractionLvSel "Mch.MCU.SIG2.HstTractionLvSel";
BA_ "VssSig" SG_ 2566865953 FltHold "Mch.MCU.SIG2.FltHold";
BA_ "VssSig" SG_ 2566865953 Adb "Mch.MCU.SIG2.Adb";
BA_ "VssSig" SG_ 2566865953 Cruise "Mch.MCU.SIG2.Cruise";
BA_ "VssSig" SG_ 2566865953 WhlDrvMd "Mch.MCU.SIG2.WhlDrvMd";
BA_ "VssSig" SG_ 2566865953 DesMchShtDn "Mch.MCU.SIG2.DesMchShtDn";
BA_ "VssSig" SG_ 2566865953 FrcRgnStp "Mch.MCU.SIG2.FrcRgnStp";
BA_ "VssSig" SG_ 2566865953 FrcRgnScs "Mch.MCU.SIG2.FrcRgnScs";
BA_ "VssSig" SG_ 2566865953 WghCnt "Mch.MCU.SIG2.WghCnt";
BA_ "VssSig" SG_ 2566865953 MapCreateProg "Mch.MCU.SIG2.MapCreateProg";
BA_ "VssSig" SG_ 2566865953 AngSsTunReq "Mch.MCU.SIG2.AngSsTunReq";
BA_ "VssSig" SG_ 2566865953 ZeroCalbReq "Mch.MCU.SIG2.ZeroCalbReq";
BA_ "VssSig" SG_ 2566865953 WarmUp "Mch.MCU.SIG2.WarmUp";
BA_ "VssSig" SG_ 2566865953 MapCreatReady "Mch.MCU.SIG2.MapCreatReady";
BA_ "VssSig" SG_ 2566865953 ColdStart "Mch.MCU.SIG2.ColdStart";
BA_ "VssSig" SG_ 2566865953 WghTooHv "Mch.MCU.SIG2.WghTooHv";
BA_ "VssSig" SG_ 2566865953 WghPoorLft "Mch.MCU.SIG2.WghPoorLft";
BA_ "VssSig" SG_ 2566865953 WghStartPosHh "Mch.MCU.SIG2.WghStartPosHh";
BA_ "VssSig" SG_ 2566865953 WghSpdBuc "Mch.MCU.SIG2.WghSpdBuc";
BA_ "VssSig" SG_ 2566865953 WghUnderSpd "Mch.MCU.SIG2.WghUnderSpd";
BA_ "VssSig" SG_ 2566865953 RrDefst "Mch.MCU.SIG2.RrDefst";
BA_ "VssSig" SG_ 2566865953 EmgMd "Mch.MCU.SIG2.EmgMd";
BA_ "VssSig" SG_ 2566865953 OprMd "Mch.MCU.SIG2.OprMd";
BA_ "VssSig" SG_ 2566865953 OprPowMd "Mch.MCU.SIG2.OprPowMd";
BA_ "VssSig" SG_ 2566865953 HstMdWld "Mch.MCU.SIG2.HstMdWld";
BA_ "VssSig" SG_ 2566865953 CCO "Mch.MCU.SIG2.CCO";
BA_ "VssSig" SG_ 2566865953 TrqCvt "Mch.MCU.SIG2.TrqCvt";
BA_ "VssSig" SG_ 2566865953 TrvMdWld "Mch.MCU.SIG2.TrvMdWld";
BA_ "VssSig" SG_ 2566865953 Creep "Mch.MCU.SIG2.Creep";
BA_ "VssSig" SG_ 2566865953 ThrtLck "Mch.MCU.SIG2.ThrtLck";
BA_ "VssSig" SG_ 2566865953 Dhl "Mch.MCU.SIG2.Dhl";
BA_ "VssSig" SG_ 2566865953 LisSw "Mch.MCU.SIG2.LisSw";
BA_ "VssSig" SG_ 2566865953 CoolDrtTm "Mch.MCU.SIG2.CoolDrtTm";
BA_ "VssSig" SG_ 2566865953 WifDrtTm "Mch.MCU.SIG2.WifDrtTm";
BA_ "VssSig" SG_ 2566866721 DifActlTrgGrdt "Mch.MCU.SIG3.DifActlTrgGrdt";
BA_ "VssSig" SG_ 2566866721 OprPrsntSt "Mch.MCU.SIG3.OprPrsntSt";
BA_ "VssSig" SG_ 2566866721 HydCutOffRls "Mch.MCU.SIG3.HydCutOffRls";
BA_ "VssSig" SG_ 2566866721 ChgErr "Mch.MCU.SIG3.ChgErr";
BA_ "VssSig" SG_ 2566866721 ChgSt "Mch.MCU.SIG3.ChgSt";
BA_ "VssSig" SG_ 2566866721 WrkTrv "Mch.MCU.SIG3.WrkTrv";
BA_ "VssSig" SG_ 2566866721 BatLw "Mch.MCU.SIG3.BatLw";
BA_ "VssSig" SG_ 2566866721 HydLck "Mch.MCU.SIG3.HydLck";
BA_ "VssSig" SG_ 2566866721 HillDscntCtrlSt "Mch.MCU.SIG3.HillDscntCtrlSt";
BA_ "VssSig" SG_ 2566866721 OprPrsnc "Mch.MCU.SIG3.OprPrsnc";
BA_ "VssSig" SG_ 2566866721 BckDust "Mch.MCU.SIG3.BckDust";
BA_ "VssSig" SG_ 2566866721 BmsPrhtLmp "Mch.MCU.SIG3.BmsPrhtLmp";
BA_ "VssSig" SG_ 2566866721 DacSt "Mch.MCU.SIG3.DacSt";
BA_ "VssSig" SG_ 2566866721 EmcvFngrtpLvrErr "Mch.MCU.SIG3.EmcvFngrtpLvrErr";
BA_ "VssSig" SG_ 2566866721 IllminSt "Mch.MCU.SIG3.IllminSt";
BA_ "VssSig" SG_ 2566866721 ChmslSt "Mch.MCU.SIG3.ChmslSt";
BA_ "VssSig" SG_ 2566866721 CdsFanRvsSt "Mch.MCU.SIG3.CdsFanRvsSt";
BA_ "VssSig" SG_ 2566866721 CacFanRvsSt "Mch.MCU.SIG3.CacFanRvsSt";
BA_ "VssSig" SG_ 2566866721 WrnGndSlop "Mch.MCU.SIG3.WrnGndSlop";
BA_ "VssSig" SG_ 2566866721 WrnOilTmpLw "Mch.MCU.SIG3.WrnOilTmpLw";
BA_ "VssSig" SG_ 2566866721 AttOpr "Mch.MCU.SIG3.AttOpr";
BA_ "VssSig" SG_ 2566866721 WrnLimpHome "Mch.MCU.SIG3.WrnLimpHome";
BA_ "VssSig" SG_ 2566866721 MchCond "Mch.MCU.SIG3.MchCond";
BA_ "VssSig" SG_ 2566866721 WrnRollOvr "Mch.MCU.SIG3.WrnRollOvr";
BA_ "VssSig" SG_ 2566866721 WrnArmPosOnDrv "Mch.MCU.SIG3.WrnArmPosOnDrv";
BA_ "VssSig" SG_ 2566866721 WrnThmbWhlStrShft "Mch.MCU.SIG3.WrnThmbWhlStrShft";
BA_ "VssSig" SG_ 2566866721 WrnRamLck "Mch.MCU.SIG3.WrnRamLck";
BA_ "VssSig" SG_ 2566866721 WrnHstOilFilt "Mch.MCU.SIG3.WrnHstOilFilt";
BA_ "VssSig" SG_ 2566866721 WrnGrBoxOvTmp "Mch.MCU.SIG3.WrnGrBoxOvTmp";
BA_ "VssSig" SG_ 2566866721 VhcStTractionLv "Mch.MCU.SIG3.VhcStTractionLv";
BA_ "VssSig" SG_ 2566866721 WhlLis "Mch.MCU.SIG3.WhlLis";
BA_ "VssSig" SG_ 2566866721 WhlDzTrlHitch "Mch.MCU.SIG3.WhlDzTrlHitch";
BA_ "VssSig" SG_ 2566866721 WhlSwgAlign "Mch.MCU.SIG3.WhlSwgAlign";
BA_ "VssSig" SG_ 2566866721 WhlRamLckAuto "Mch.MCU.SIG3.WhlRamLckAuto";
VAL_ 3221225472 WarnPopHyhOilQual 0 "Off" 1 "?? 1??" 2 "?? 2??" ;
VAL_ 3221225472 WarnPopEgOilQual 0 "Off" 1 "?? 1??" 2 "?? 2??" ;
VAL_ 2583662767 WarnPopEgOilQual 0 "Off" 1 "?? 1??" 2 "?? 2??" ;
VAL_ 2583662767 WarnPopHyhOilQual 0 "Off" 1 "?? 1??" 2 "?? 2??" ;
VAL_ 2348810243 OvrCtrlMdPri 0 "Highest" 1 "High" 2 "Medium" 3 "Low" ;
VAL_ 2348810243 EgOvrCtrlMd 0 "Override disabled" 1 "Speed control" 2 "Torque control" 3 "Speed/torque limit control" ;
VAL_ 2348810251 OvrCtrlMdPri 0 "Highest" 1 "High" 2 "Medium" 3 "Low" ;
VAL_ 2348810251 EgOvrCtrlMd 0 "Override disabled" 1 "Speed control" 2 "Torque control" 3 "Speed/torque limit control" ;
VAL_ 2348810259 OvrCtrlMdPri 0 "Highest" 1 "High" 2 "Medium" 3 "Low" ;
VAL_ 2348810259 EgOvrCtrlMd 0 "Override disabled" 1 "Speed control" 2 "Torque control" 3 "Speed/torque limit control" ;
VAL_ 2348810273 OvrCtrlMdPri 0 "Highest" 1 "High" 2 "Medium" 3 "Low" ;
VAL_ 2348810273 EgOvrCtrlMd 0 "Override disabled" 1 "Speed control" 2 "Torque control" 3 "Speed/torque limit control" ;
VAL_ 2564816912 AtRgnFrcSw 0 "Off" 1 "On" 2 "Error" 3 "N/A" ;
VAL_ 2564816912 AtRgnInhbSw 0 "Off" 1 "On" 2 "Error" 3 "N/A" ;
VAL_ 2564816929 AtRgnFrcSw 0 "Off" 1 "On" 2 "Error" 3 "N/A" ;
VAL_ 2564816929 AtRgnInhbSw 0 "Off" 1 "On" 2 "Error" 3 "N/A" ;
VAL_ 2565865733 EgAuxShdnSw 0 "Off" 1 "On" 2 "Error" 3 "N/A" ;
VAL_ 2565865739 EgAuxShdnSw 0 "Off" 1 "On" 2 "Error" 3 "N/A" ;
VAL_ 2364539395 InProTrmShft 0 "False" 1 "True" 2 "Error" 3 "N/A" ;
VAL_ 2364539395 TrqCvtLckEng 0 "False" 1 "True" 2 "Error" 3 "N/A" ;
VAL_ 2364539395 TrmDrvEng 0 "False" 1 "True" 2 "Error" 3 "N/A" ;
VAL_ 2565867011 DifLckStCtrEng 0 "False" 1 "True" 2 "Error" 3 "N/A" ;
VAL_ 2364542241 BladeAutoMdCmd 0 "Auto Allowed" 2 "Suspend Auto" 3 "Service Mode" 4 "Auto Not Allowed" 14 "Error" 15 "Not Available" ;
VAL_ 2364542241 DsrGrdOfsSw 0 "No button pressed" 1 "Increment button pressed" 2 "Decrement button pressed" 14 "Error" 15 "Not Available" ;
VAL_ 2364542241 BladeCtrlMdSw 0 "Manual" 1 "Auto" 2 "Error" 3 "N/A" ;
VAL_ 2565869137 AtIntGasSsHtCtrl 0 "Automatic" 1 "Preheat 2" 2 "Preheat 1" 3 "Heater off" ;
VAL_ 2565869137 InRngAtIntGasSsTmp 0 "False" 1 "True" 2 "Error" 3 "N/A" ;
VAL_ 2565869394 AtOutGasSsHtCtrl 0 "Automatic" 1 "Preheat 2" 2 "Preheat 1" 3 "Heater off" ;
VAL_ 2565869394 InRngAtOutGasSsTmp 0 "False" 1 "True" 2 "Error" 3 "N/A" ;
VAL_ 2566749184 ExhHhTmpLmpCmd 0 "Off" 1 "On" 2 "Error" 3 "N/A" ;
VAL_ 2566749184 DpfActRgnIhbSw 0 "Not inhibited" 1 "Inhibited" 3 "N/A" ;
VAL_ 2566749184 DpfActRgnSt 0 "Not active" 1 "Active" 2 "Regeneration needed" 3 "N/A" ;
VAL_ 2566749184 DpfFiltLmpCmd 0 "Off" 1 "On" 2 "Blinking" 3 "N/A" ;
VAL_ 2566757120 AtDefPpt 0 "Urea concentration too high" 1 "Urea concentration too low" 2 "Fluid is diesel" 3 "Diesel exhaust fluid is proper mixture" 13 "Not able to determine" 14 "Error" 15 "N/A" ;
VAL_ 2566758656 AtIgn 0 "Off" 1 "On" 2 "Error" 3 "N/A" ;
VAL_ 2365468962 FailSafeMd 0 "Block" 1 "Extend" 2 "Reserved" 3 "Don't Care" ;
VAL_ 2365468962 VvSt 0 "Block" 1 "Extend" 2 "Retract" 3 "Float" 15 "N/A" ;
VAL_ 2365468962 ResolutionMd 0 "Standard Resolution" 1 "High Resolution" 2 "Reserved" 3 "Don't Care" ;
VAL_ 2365469218 FailSafeMd 0 "Block" 1 "Extend" 2 "Reserved" 3 "Don't Care" ;
VAL_ 2365469218 VvSt 0 "Block" 1 "Extend" 2 "Retract" 3 "Float" 15 "N/A" ;
VAL_ 2365469218 ResolutionMd 0 "Standard Resolution" 1 "High Resolution" 2 "Reserved" 3 "Don't Care" ;
VAL_ 2566852897 PrkBrkSw 0 "Off" 1 "On" 2 "Error" 3 "N/A" ;
VAL_ 2566852897 StartCtrlReq 0 "Off" 1 "On" 2 "Error" 3 "N/A" ;
VAL_ 2566852897 CCAccSw 0 "Off" 1 "On" 2 "Error" 3 "N/A" ;
VAL_ 2566852897 CCRsmSw 0 "Off" 1 "On" 2 "Error" 3 "N/A" ;
VAL_ 2566852897 CCCoastSw 0 "Off" 1 "On" 2 "Error" 3 "N/A" ;
VAL_ 2566852897 CCSetSw 0 "Off" 1 "On" 2 "Error" 3 "N/A" ;
VAL_ 2566852897 PtoSt 0 "Off/Disabled" 1 "Hold" 2 "Remote Hold" 3 "Standby" 4 "Remote Standby" 5 "Set" 6 "Decelerate/Coast" 7 "Resume" 8 "Accelerate" 9 "Accelerator Override" 10 "Preprogrammed set speed 1" 11 "Preprogrammed set speed 2" 12 "Preprogrammed set speed 3" 13 "Preprogrammed set speed 4" 14 "Preprogrammed set speed 5" 15 "Preprogrammed set speed 6" 16 "Preprogrammed set speed 7" 17 "Preprogrammed set speed 8" 18 "PTO set speed memory 1" 19 "PTO set speed memory 2" 31 "N/A" ;
VAL_ 2566852897 RddtBrk 0 "Off" 1 "On" 2 "Error" 3 "N/A" ;
VAL_ 2566852897 BrkSw 0 "Off" 1 "On" 2 "Error" 3 "N/A" ;
VAL_ 2566852897 LisSw 0 "Off" 1 "On" 2 "Error" 3 "N/A" ;
VAL_ 2365527585 Errorcode 0 "Reserved" 1 "Reserved" 2 "Reserved" 3 "Reserved" 4 "Reserved" 5 "Reserved" 6 "Reserved" 7 "Reserved" 8 "Reserved" 9 "Reserved" 10 "Reserved" 11 "Reserved" 12 "Reserved" 13 "Reserved" 14 "Reserved" 15 "No Error" ;
VAL_ 2365527585 JoyEnbsignal 0 "Inactive" 1 "Active" 2 "Reserved" 3 "Not Available" ;
VAL_ 2365527841 Errorcode 0 "Reserved" 1 "Reserved" 2 "Reserved" 3 "Reserved" 4 "Reserved" 5 "Reserved" 6 "Reserved" 7 "Reserved" 8 "Reserved" 9 "Reserved" 10 "Reserved" 11 "Reserved" 12 "Reserved" 13 "Reserved" 14 "Reserved" 15 "No Error" ;
VAL_ 2365527841 JoyEnbsignal 0 "Inactive" 1 "Active" 2 "Reserved" 3 "Not Available" ;
VAL_ 2365528097 DirIndication 0 "Forward" 1 "Reverse" 2 "Error indicator" 3 "Not Available" ;
VAL_ 2365528353 Drtindication 0 "Forward" 1 "Reverse" 2 "Error indicator" 3 "Not Available" ;
VAL_ 2566856960 EdcOprSt 0 "Normal Operation" 1 "Afterrun Drive" 2 "Diagnostic Test" ;
VAL_ 2566856960 EgOilTmpHh 0 "Normal" 1 "Above Operation Range" 2 "Reserved" 3 "Not Available" ;
VAL_ 2566856960 FuelFiltHtSt 0 "Off" 1 "On" 2 "Error" 3 "N/A" ;
VAL_ 2566856960 WifWrn 0 "Normal" 1 "Warning" 2 "Reserved" 3 "Not Available" ;
VAL_ 2566856960 EgOilPrsLw 0 "Normal" 1 "Below Operation Range" 2 "Reserved" 3 "Not Available" ;
VAL_ 2566856960 BtnStp 0 "Off" 1 "On" 2 "Error" 3 "N/A" ;
VAL_ 2566856960 RgnLmp 0 "Off" 1 "On" 4 "Blinking" ;
VAL_ 2566856960 HydPmpActReq 0 "Off" 1 "On" 2 "Error" 3 "N/A" ;
VAL_ 2566856960 MIL 0 "Off" 1 "On" 2 "Blinking" 3 "N/A" ;
VAL_ 2566856960 EgOvrSpd 0 "Normal" 1 "Above Operation Range" 2 "Reserved" 3 "Not Available" ;
VAL_ 2566856960 SpdLmtLmp 0 "Off" 1 "On" 2 "Blinking" 3 "N/A" ;
VAL_ 2566856960 DiagLmp 0 "Off" 1 "On" 2 "Blinking" 3 "N/A" ;
VAL_ 2566856960 FuelBlock 0 "Fuel Released" 1 "Fuel Blocked" ;
VAL_ 2566856960 ColdStartHt 0 "OFF" 1 "Trsm Pre-Heating" 2 "Gear Neutral for Pre-Heating" 3 "No Foot on the Pdedal for Pre-Heating" 4 "Parking Brake for Pre-Heating" 5 "Fault while Pre-Heating" 6 "Slow Blinking" 7 "Normal Blinking" 8 "Test of Grid Heater Voltage" ;
VAL_ 2566859523 IsEngDrvSt 0 "False" 1 "True" 2 "Error" 3 "N/A" ;
VAL_ 2566859523 InProcShftSt 0 "False" 1 "True" 2 "Error" 3 "N/A" ;
VAL_ 2566859523 OpMd 0 "Normal" 1 "Substitute_Clutch_Control" 2 "Limp_Home" 3 "Transmission_Shutdown" 4 "TCU_Shutdown" 5 "TCU Key Off" 6 "TCU Idle" ;
VAL_ 2566859523 IsActJoyMd 0 "False" 1 "True" 2 "Error" 3 "N/A" ;
VAL_ 2566859523 CurDir 0 "Position_N" 1 "Position_F" 2 "Position_R" 3 "TCU requires N position" ;
VAL_ 2566859523 CurGr 0 "Neutral" 1 "Gear 1" 2 "Gear 2" 3 "Gear 3" 4 "Gear 4" 5 "Gear 5" 6 "Gear 6" 7 "Limp Home" ;
VAL_ 2566859523 DifLck 0 "Off" 1 "On" 2 "Error" 3 "N/A" ;
VAL_ 2566859523 ShftDir 0 "Position_N" 1 "Position_F" 2 "Position_R" 3 "TCU requires N position" ;
VAL_ 2566860833 ChgSt 0 "Charging" 1 "Charging Port Warning" 2 "Charging Gun Warning" 3 "AC Voltage Above Normal" 4 "AC Voltage Below Normal" 5 "EVSE Signal Warning" ;
VAL_ 2566860833 MchKeyOnSt 0 "Key off" 1 "Key on" 2 "Key off charging" 3 "Not defined" ;
VAL_ 2566860833 OnBrdChgCmd 0 "False" 1 "True" 2 "Error" 3 "N/A" ;
VAL_ 2566860833 QckChgEnableCmd 0 "False" 1 "True" 2 "Error" 3 "N/A" ;
VAL_ 2566860833 PwrDnCmd 0 "Not request" 1 "Normal Power-Down" 2 "Emergency Power-Down" 3 "N/A" ;
VAL_ 2566863533 FanSt 0 "Not Working" 1 "Working" ;
VAL_ 2566864627 ChgSt 0 "Standby" 1 "Charging" 2 "Failure" 3 "Complete" 4 "Pause" 5 "Reserved" 6 "Charger Error" 7 "Not Available" ;
VAL_ 2566864627 HtPadSt 0 "Off" 1 "On Board Charger" ;
VAL_ 2566864627 BmsChgSrcType 0 "None" 1 "On Board Charger" 2 "Quick charger" 3 "Not Available" ;
VAL_ 2566864929 InvOh 0 "Off" 1 "On" 2 "Blinking" 3 "Slow Blinking" ;
VAL_ 2566864929 MotOh 0 "Off" 1 "On" 2 "Blinking" 3 "Slow Blinking" ;
VAL_ 2566864929 BatOh 0 "Off" 1 "On" 2 "Blinking" 3 "Slow Blinking" ;
VAL_ 2566864929 Bms 0 "Off" 1 "On" 2 "Blinking" 3 "Slow Blinking" ;
VAL_ 2566864929 BatHt 0 "Off" 1 "On" 2 "Blinking" 3 "Slow Blinking" ;
VAL_ 2566864929 TrvlPdlFail 0 "Off" 1 "On" 2 "Blinking" 3 "Slow Blinking" ;
VAL_ 2566864929 RrWhlAlgn 0 "Off" 1 "On" 2 "Blinking" 3 "Slow Blinking" ;
VAL_ 2566864929 PrkBrkPrs 0 "Off" 1 "On" 2 "Blinking" 3 "Slow Blinking" ;
VAL_ 2566864929 TrsmOilFiltClog 0 "Off" 1 "On" 2 "Blinking" 3 "Slow Blinking" ;
VAL_ 2566864929 FanMotPrsLw 0 "Off" 1 "On" 2 "Blinking" 3 "Slow Blinking" ;
VAL_ 2566864929 OvSpd 0 "Off" 1 "On" 2 "Blinking" 3 "Slow Blinking" ;
VAL_ 2566864929 RBrkPdlNoCalb 0 "Off" 1 "On" 2 "Blinking" 3 "Slow Blinking" ;
VAL_ 2566864929 ElecStr 0 "Off" 1 "On" 2 "Blinking" 3 "Slow Blinking" ;
VAL_ 2566864929 EgOvr 0 "Off" 1 "On" 2 "Blinking" 3 "Slow Blinking" ;
VAL_ 2566864929 EmgStr 0 "Off" 1 "On" 2 "Blinking" 3 "Slow Blinking" ;
VAL_ 2566864929 SeatBelt 0 "Off" 1 "On" 2 "Blinking" 3 "Slow Blinking" ;
VAL_ 2566864929 TrsmOilOh 0 "Off" 1 "On" 2 "Blinking" 3 "Slow Blinking" ;
VAL_ 2566864929 Trsm 0 "Off" 1 "On" 2 "Blinking" 3 "Slow Blinking" ;
VAL_ 2566864929 VboEpprVvOut 0 "Off" 1 "On" 2 "Blinking" 3 "Slow Blinking" ;
VAL_ 2566864929 VboJoySs 0 "Off" 1 "On" 2 "Blinking" 3 "Slow Blinking" ;
VAL_ 2566864929 VboAngSs 0 "Off" 1 "On" 2 "Blinking" 3 "Slow Blinking" ;
VAL_ 2566864929 BatEq 0 "Off" 1 "On" 2 "Blinking" 3 "Slow Blinking" ;
VAL_ 2566864929 Uss 0 "Off" 1 "On" 2 "Blinking" 3 "Slow Blinking" ;
VAL_ 2566864929 IceptSs 0 "Off" 1 "On" 2 "Blinking" 3 "Slow Blinking" ;
VAL_ 2566864929 Str 0 "Off" 1 "On" 2 "Blinking" 3 "Slow Blinking" ;
VAL_ 2566864929 BrkOilPrsLw 0 "Off" 1 "On" 2 "Blinking" 3 "Slow Blinking" ;
VAL_ 2566864929 Ags 0 "Off" 1 "On" 2 "Blinking" 3 "Slow Blinking" ;
VAL_ 2566864929 Owd 0 "Off" 1 "On" 2 "Blinking" 3 "Slow Blinking" ;
VAL_ 2566864929 PilotFilt 0 "Off" 1 "On" 2 "Blinking" 3 "Slow Blinking" ;
VAL_ 2566864929 RetFilt 0 "Off" 1 "On" 2 "Blinking" 3 "Slow Blinking" ;
VAL_ 2566864929 HydOilOh 0 "Off" 1 "On" 2 "Blinking" 3 "Slow Blinking" ;
VAL_ 2566864929 BatChg 0 "Off" 1 "On" 2 "Blinking" 3 "Slow Blinking" ;
VAL_ 2566865185 AcleOilOh 0 "Off" 1 "On" 2 "Blinking" 3 "Slow Blinking" ;
VAL_ 2566865185 TireTemp 0 "Off" 1 "On" 2 "Blinking" 3 "Slow Blinking" ;
VAL_ 2566865185 FuelEmptyAddFuelTnk 0 "Off" 1 "On" 2 "Blinking" 3 "Slow Blinking" ;
VAL_ 2566865185 ePowStp 0 "Off" 1 "On" 2 "Blinking" 3 "Slow Blinking" ;
VAL_ 2566865185 ePowChk 0 "Off" 1 "On" 2 "Blinking" 3 "Slow Blinking" ;
VAL_ 2566865185 CoolLv 0 "Off" 1 "On" 2 "Blinking" 3 "Slow Blinking" ;
VAL_ 2566865185 DefPrsLw 0 "Off" 1 "On" 2 "Blinking" 3 "Slow Blinking" ;
VAL_ 2566865185 WifMainFiltFault 0 "Off" 1 "On" 2 "Blinking" 3 "Slow Blinking" ;
VAL_ 2566865185 WifMainFiltWaterDetectFault 0 "Off" 1 "On" 2 "Blinking" 3 "Slow Blinking" ;
VAL_ 2566865185 WifPrePilotFault 0 "Off" 1 "On" 2 "Blinking" 3 "Slow Blinking" ;
VAL_ 2566865185 WifPrePilot 0 "Off" 1 "On" 2 "Blinking" 3 "Slow Blinking" ;
VAL_ 2566865185 FuelEmpty 0 "Off" 1 "On" 2 "Blinking" 3 "Slow Blinking" ;
VAL_ 2566865185 AutoSCrcondPrkns 0 "Off" 1 "On" 2 "Blinking" 3 "Slow Blinking" ;
VAL_ 2566865185 ExHhTempAmb 0 "Off" 1 "On" 2 "Blinking" 3 "Slow Blinking" ;
VAL_ 2566865185 ExHhTempGr 0 "Off" 1 "On" 2 "Blinking" 3 "Slow Blinking" ;
VAL_ 2566865185 DpfActRgnInhbtSt 0 "Off" 1 "On" 2 "Blinking" 3 "Slow Blinking" ;
VAL_ 2566865185 DpfRgnClg 0 "Off" 1 "On" 2 "Blinking" 3 "Slow Blinking" ;
VAL_ 2566865185 EgChkSrv 0 "Off" 1 "On" 2 "Blinking" 3 "Slow Blinking" ;
VAL_ 2566865185 EgChk2 0 "Off" 1 "On" 2 "Blinking" 3 "Slow Blinking" ;
VAL_ 2566865185 EgChk1 0 "Off" 1 "On" 2 "Blinking" 3 "Slow Blinking" ;
VAL_ 2566865185 EgStp 0 "Off" 1 "On" 2 "Blinking" 3 "Slow Blinking" ;
VAL_ 2566865185 EgWrn 0 "Off" 1 "On" 2 "Blinking" 3 "Slow Blinking" ;
VAL_ 2566865185 AirCln 0 "Off" 1 "On" 2 "Blinking" 3 "Slow Blinking" ;
VAL_ 2566865185 CoolLvSrgTnk 0 "Off" 1 "On" 2 "Blinking" 3 "Slow Blinking" ;
VAL_ 2566865185 CoolTmpOv 0 "Off" 1 "On" 2 "Blinking" 3 "Slow Blinking" ;
VAL_ 2566865185 EgOilPrs 0 "Off" 1 "On" 2 "Blinking" 3 "Slow Blinking" ;
VAL_ 2566865441 TirePrs 0 "Off" 1 "On text1" 2 "Blinking text1" 3 "Slow Blinking text1" 4 "N/A" 5 "On text3" 6 "Blinking text3" 7 "Slow Blinking text3" 8 "N/A" 9 "On text2" 10 "Blinking text2" 11 "Slow Blinking text2" 12 "N/A" 13 "On text4" 14 "Blinking text4" 15 "Slow Blinking text4" ;
VAL_ 2566865441 HydOilWarmUp 0 "Off" 1 "On text1" 2 "Blinking text1" 3 "Slow Blinking text1" 4 "N/A" 5 "On text3" 6 "Blinking text3" 7 "Slow Blinking text3" 8 "N/A" 9 "On text2" 10 "Blinking text2" 11 "Slow Blinking text2" 12 "N/A" 13 "On text4" 14 "Blinking text4" 15 "Slow Blinking text4" ;
VAL_ 2566865441 GndSawRdy 0 "Off" 1 "On text1" 2 "Blinking text1" 3 "Slow Blinking text1" 4 "N/A" 5 "On text3" 6 "Blinking text3" 7 "Slow Blinking text3" 8 "N/A" 9 "On text2" 10 "Blinking text2" 11 "Slow Blinking text2" 12 "N/A" 13 "On text4" 14 "Blinking text4" 15 "Slow Blinking text4" ;
VAL_ 2566865441 TrvMotTempOh 0 "Off" 1 "On text1" 2 "Blinking text1" 3 "Slow Blinking text1" 4 "N/A" 5 "On text3" 6 "Blinking text3" 7 "Slow Blinking text3" 8 "N/A" 9 "On text2" 10 "Blinking text2" 11 "Slow Blinking text2" 12 "N/A" 13 "On text4" 14 "Blinking text4" 15 "Slow Blinking text4" ;
VAL_ 2566865441 QckCouplerLck 0 "Off" 1 "On text1" 2 "Blinking text1" 3 "Slow Blinking text1" 4 "N/A" 5 "On text3" 6 "Blinking text3" 7 "Slow Blinking text3" 8 "N/A" 9 "On text2" 10 "Blinking text2" 11 "Slow Blinking text2" 12 "N/A" 13 "On text4" 14 "Blinking text4" 15 "Slow Blinking text4" ;
VAL_ 2566865441 BrkPdlSs 0 "Off" 1 "On text1" 2 "Blinking text1" 3 "Slow Blinking text1" 4 "N/A" 5 "On text3" 6 "Blinking text3" 7 "Slow Blinking text3" 8 "N/A" 9 "On text2" 10 "Blinking text2" 11 "Slow Blinking text2" 12 "N/A" 13 "On text4" 14 "Blinking text4" 15 "Slow Blinking text4" ;
VAL_ 2566865441 AtsRgnReq 0 "Off" 1 "On text1" 2 "Blinking text1" 3 "Slow Blinking text1" 4 "N/A" 5 "On text3" 6 "Blinking text3" 7 "Slow Blinking text3" 8 "N/A" 9 "On text2" 10 "Blinking text2" 11 "Slow Blinking text2" 12 "N/A" 13 "On text4" 14 "Blinking text4" 15 "Slow Blinking text4" ;
VAL_ 2566865441 TmsConSt 0 "Off" 1 "On text1" 2 "Blinking text1" 3 "Slow Blinking text1" 4 "N/A" 5 "On text3" 6 "Blinking text3" 7 "Slow Blinking text3" 8 "N/A" 9 "On text2" 10 "Blinking text2" 11 "Slow Blinking text2" 12 "N/A" 13 "On text4" 14 "Blinking text4" 15 "Slow Blinking text4" ;
VAL_ 2566865441 QckCouplerUnlock 0 "Off" 1 "On text1" 2 "Blinking text1" 3 "Slow Blinking text1" 4 "N/A" 5 "On text3" 6 "Blinking text3" 7 "Slow Blinking text3" 8 "N/A" 9 "On text2" 10 "Blinking text2" 11 "Slow Blinking text2" 12 "N/A" 13 "On text4" 14 "Blinking text4" 15 "Slow Blinking text4" ;
VAL_ 2566865441 RmvCntwt 0 "Off" 1 "On text1" 2 "Blinking text1" 3 "Slow Blinking text1" 4 "N/A" 5 "On text3" 6 "Blinking text3" 7 "Slow Blinking text3" 8 "N/A" 9 "On text2" 10 "Blinking text2" 11 "Slow Blinking text2" 12 "N/A" 13 "On text4" 14 "Blinking text4" 15 "Slow Blinking text4" ;
VAL_ 2566865441 FuelFilt 0 "Off" 1 "On text1" 2 "Blinking text1" 3 "Slow Blinking text1" 4 "N/A" 5 "On text3" 6 "Blinking text3" 7 "Slow Blinking text3" 8 "N/A" 9 "On text2" 10 "Blinking text2" 11 "Slow Blinking text2" 12 "N/A" 13 "On text4" 14 "Blinking text4" 15 "Slow Blinking text4" ;
VAL_ 2566865441 UreaQualScr 0 "Off" 1 "On text1" 2 "Blinking text1" 3 "Slow Blinking text1" 4 "N/A" 5 "On text3" 6 "Blinking text3" 7 "Slow Blinking text3" 8 "N/A" 9 "On text2" 10 "Blinking text2" 11 "Slow Blinking text2" 12 "N/A" 13 "On text4" 14 "Blinking text4" 15 "Slow Blinking text4" ;
VAL_ 2566865441 UreaLv 0 "Off" 1 "On text1" 2 "Blinking text1" 3 "Slow Blinking text1" 4 "N/A" 5 "On text3" 6 "Blinking text3" 7 "Slow Blinking text3" 8 "N/A" 9 "On text2" 10 "Blinking text2" 11 "Slow Blinking text2" 12 "N/A" 13 "On text4" 14 "Blinking text4" 15 "Slow Blinking text4" ;
VAL_ 2566865697 CurGr 0 "Neutral" 1 "Gear 1" 2 "Gear 2" 3 "Gear 3" 4 "Gear 4" 5 "Gear 5" 6 "Gear 6" 7 "Limp Home" ;
VAL_ 2566865697 SelGr 0 "Neutral" 1 "Gear 1" 2 "Gear 2" 3 "Gear 3" 4 "Gear 4" 5 "Gear 5" 6 "Gear 6" 7 "Limp Home" ;
VAL_ 2566865697 BoomFltBiDir 0 "Off" 1 "On" 2 "Error" 3 "N/A" ;
VAL_ 2566865697 Is3RdFNRElecStr 0 "False" 1 "True" 2 "Error" 3 "N/A" ;
VAL_ 2566865697 IsFR 0 "False" 1 "True" 2 "Error" 3 "N/A" ;
VAL_ 2566865697 IsElecStr 0 "False" 1 "True" 2 "Error" 3 "N/A" ;
VAL_ 2566865697 IsOprRdy 0 "False" 1 "True" 2 "Error" 3 "N/A" ;
VAL_ 2566865697 PreHt 0 "Off" 1 "On" 2 "Error" 3 "N/A" ;
VAL_ 2566865697 FaultCntAvm 0 "None" 1 "FaultOc1" 2 "FaultOc2" 3 "N/A" ;
VAL_ 2566865697 FaultCntMch 0 "None" 1 "FaultOc1" 2 "FaultOc2" 3 "N/A" ;
VAL_ 2566865697 CtrWrnLed 0 "Off" 1 "On" 2 "Error" 3 "N/A" ;
VAL_ 2566865697 ExBzz 0 "Off" 1 "On" 2 "Error" 3 "N/A" ;
VAL_ 2566865697 AutoShdnAval 0 "Off" 1 "On" 2 "Error" 3 "N/A" ;
VAL_ 2566865697 AutoShdnSt 0 "Off" 1 "On" 2 "Error" 3 "N/A" ;
VAL_ 2566865697 BrkrAct 0 "Stop" 1 "Running" 2 "Forced Stop" 3 "N/A" ;
VAL_ 2566865697 ThmbWhlLvErr 0 "Off" 1 "On" 2 "Error" 3 "N/A" ;
VAL_ 2566865697 AutoIdle 0 "Off" 1 "On" 2 "Error" 3 "N/A" ;
VAL_ 2566865697 RgnPrkns 0 "Off" 1 "On" 2 "Error" 3 "N/A" ;
VAL_ 2566865697 RpmCtrlRstrt 0 "Off" 1 "On" 2 "Error" 3 "N/A" ;
VAL_ 2566865697 IgnRstrtPilotCutOff 0 "Off" 1 "On" 2 "Error" 3 "N/A" ;
VAL_ 2566865697 IgnRstrtFRP 0 "Off" 1 "On" 2 "Error" 3 "N/A" ;
VAL_ 2566865697 OhPrv 0 "Off" 1 "On" 2 "Error" 3 "N/A" ;
VAL_ 2566865697 HhMntLgc 0 "OFF" 1 "<=3000m" 2 "<=4000m" 3 ">4000m" ;
VAL_ 2566865697 AutoShdn 0 "Off" 1 "On" 2 "Error" 3 "N/A" ;
VAL_ 2566865697 FuelHt 0 "Off" 1 "On" 2 "Error" 3 "N/A" ;
VAL_ 2566865697 AutoWarmUpGr 0 "Off" 1 "On" 2 "Error" 3 "N/A" ;
VAL_ 2566865697 AutoWarmUpAmb 0 "Off" 1 "On" 2 "Error" 3 "N/A" ;
VAL_ 2566865697 HhBeam 0 "Off" 1 "On" 2 "Error" 3 "N/A" ;
VAL_ 2566865697 RamLck 0 "Off" 1 "On" 2 "Error" 3 "N/A" ;
VAL_ 2566865697 PrkBrk 0 "Off" 1 "On" 2 "Error" 3 "N/A" ;
VAL_ 2566865697 Trv 0 "Off" 1 "On" 2 "Error" 3 "N/A" ;
VAL_ 2566865697 FNR 0 "F" 1 "N" 2 "R" 3 "N/A" ;
VAL_ 2566865697 TrvMdWhl 0 "True" 1 "2" 2 "3" 3 "Not Defined" ;
VAL_ 2566865697 IsoBhl 0 "OFF" 1 "ISO" 2 "BHL" ;
VAL_ 2566865697 TwOpt 0 "N/A" 1 "Joystick Thumb Wheel" 2 "Option Pedal" 3 "Not Defined" ;
VAL_ 2566865697 WrkMd 0 "Not Defined" 1 "Breaker" 2 "Two Way" 3 "Reserved" ;
VAL_ 2566865697 TrvMdCrw 0 "Low Speed" 1 "High Speed" 2 "Auto Speed" 3 "N/A" ;
VAL_ 2566865697 MrrHt 0 "Off" 1 "On" 2 "Error" 3 "N/A" ;
VAL_ 2566865697 AuxMdSt 0 "Off" 1 "On" 2 "Error" 3 "N/A" ;
VAL_ 2566865697 RvsFanSt 0 "Off" 1 "On" 2 "Error" 3 "N/A" ;
VAL_ 2566865697 SwPriSt 0 "Off" 1 "On" 2 "Error" 3 "N/A" ;
VAL_ 2566865697 BoomSwAct 0 "Off" 1 "On" 2 "Error" 3 "N/A" ;
VAL_ 2566865697 BoomFltSngDir 0 "Off" 1 "On" 2 "Error" 3 "N/A" ;
VAL_ 2566865697 PowMax 0 "Off" 1 "On" 2 "Error" 3 "N/A" ;
VAL_ 2566865697 WrkLmp 0 "Off" 1 "On" 2 "Error" 3 "N/A" ;
VAL_ 2566865953 HstTractionLvSel 0 "Off" 1 "On" 2 "Error" 3 "N/A" ;
VAL_ 2566865953 FltHold 0 "Off" 1 "On" 2 "Error" 3 "N/A" ;
VAL_ 2566865953 Adb 0 "Off" 1 "On" 2 "Condition Green" 3 "Condition Yellow" ;
VAL_ 2566865953 Cruise 0 "Off" 1 "On" 2 "Error" 3 "N/A" ;
VAL_ 2566865953 WhlDrvMd 0 "Off" 1 "FrontAlignReq" 2 "RearAlignReq" 3 "AlignComplete" ;
VAL_ 2566865953 DesMchShtDn 0 "Off" 1 "On" 2 "Error" 3 "N/A" ;
VAL_ 2566865953 FrcRgnStp 0 "Off" 1 "On" 2 "Error" 3 "N/A" ;
VAL_ 2566865953 FrcRgnScs 0 "Off" 1 "On" 2 "Error" 3 "N/A" ;
VAL_ 2566865953 MapCreateProg 0 "Off" 1 "On" 2 "Error" 3 "N/A" ;
VAL_ 2566865953 AngSsTunReq 0 "Off" 1 "On" 2 "Error" 3 "N/A" ;
VAL_ 2566865953 ZeroCalbReq 0 "Off" 1 "On" 2 "Error" 3 "N/A" ;
VAL_ 2566865953 WarmUp 0 "Off" 1 "On" 2 "Error" 3 "N/A" ;
VAL_ 2566865953 MapCreatReady 0 "Off" 1 "On" 2 "Error" 3 "N/A" ;
VAL_ 2566865953 ColdStart 0 "OFF" 1 "Trsm Pre-Heating" 2 "Gear Neutral for Pre-Heating" 3 "No Foot on the Pdedal for Pre-Heating" 4 "Parking Brake for Pre-Heating" 5 "Fault while Pre-Heating" 6 "Slow Blinking" 7 "Normal Blinking" 8 "Test of Grid Heater Voltage" ;
VAL_ 2566865953 WghTooHv 0 "Off" 1 "On" 2 "Error" 3 "N/A" ;
VAL_ 2566865953 WghPoorLft 0 "Off" 1 "On" 2 "Error" 3 "N/A" ;
VAL_ 2566865953 WghStartPosHh 0 "Off" 1 "On" 2 "Error" 3 "N/A" ;
VAL_ 2566865953 WghSpdBuc 0 "Off" 1 "On" 2 "Error" 3 "N/A" ;
VAL_ 2566865953 WghUnderSpd 0 "Off" 1 "On" 2 "Error" 3 "N/A" ;
VAL_ 2566865953 RrDefst 0 "Off" 1 "On" 2 "Error" 3 "N/A" ;
VAL_ 2566865953 EmgMd 0 "Off" 1 "On" 2 "Error" 3 "N/A" ;
VAL_ 2566865953 OprMd 0 "Normal" 1 "Digging" ;
VAL_ 2566865953 OprPowMd 0 "Power" 1 "Standard" 2 "Economy" 3 "AutoIdle" 4 "Power+" ;
VAL_ 2566865953 HstMdWld 0 "Max" 1 "Auto" 2 "Slip" 3 "Not Defined" ;
VAL_ 2566865953 CCO 0 "Off" 1 "On" 2 "Error" 3 "N/A" ;
VAL_ 2566865953 TrqCvt 0 "Off" 1 "On" 2 "Error" 3 "N/A" ;
VAL_ 2566865953 TrvMdWld 0 "Manual" 1 "Auto Speed 1" 2 "Auto Speed 2" 3 "Not Defined" ;
VAL_ 2566865953 Creep 0 "Off" 1 "On" 2 "Error" 3 "N/A" ;
VAL_ 2566865953 ThrtLck 0 "Off" 1 "On" 2 "Error" 3 "N/A" ;
VAL_ 2566865953 Dhl 0 "Off" 1 "On" 2 "Error" 3 "N/A" ;
VAL_ 2566865953 LisSw 0 "Off" 1 "On" 2 "Error" 3 "N/A" ;
VAL_ 2566866721 DifActlTrgGrdt 0 "Off" 1 "On" 2 "Error" 3 "N/A" ;
VAL_ 2566866721 OprPrsntSt 0 "Off" 1 "On" 2 "Error" 3 "N/A" ;
VAL_ 2566866721 HydCutOffRls 0 "Off" 1 "On" 2 "Error" 3 "N/A" ;
VAL_ 2566866721 ChgErr 0 "Off" 1 "On" 2 "Error" 3 "N/A" ;
VAL_ 2566866721 ChgSt 0 "Off" 1 "Grey" 2 "Green" 3 "Yellow" ;
VAL_ 2566866721 WrkTrv 0 "Off" 1 "On" 2 "Error" 3 "N/A" ;
VAL_ 2566866721 BatLw 0 "Off" 1 "On" 2 "Error" 3 "N/A" ;
VAL_ 2566866721 HydLck 0 "Off" 1 "On" 2 "Error" 3 "N/A" ;
VAL_ 2566866721 HillDscntCtrlSt 0 "Off" 1 "On" 2 "Error" 3 "N/A" ;
VAL_ 2566866721 OprPrsnc 0 "Off" 1 "On" 2 "Error" 3 "N/A" ;
VAL_ 2566866721 BckDust 0 "Off" 1 "On" 2 "Error" 3 "N/A" ;
VAL_ 2566866721 BmsPrhtLmp 0 "Off" 1 "On" 2 "Error" 3 "N/A" ;
VAL_ 2566866721 DacSt 0 "Not Ready" 1 "Stand By" 2 "Manual" 3 "Auto" 4 "Interlock" 5 "Suspend auto" ;
VAL_ 2566866721 EmcvFngrtpLvrErr 0 "Off" 1 "On" 2 "Error" 3 "N/A" ;
VAL_ 2566866721 IllminSt 0 "None" 1 "Off" 2 "On" 3 "N/A" ;
VAL_ 2566866721 ChmslSt 0 "Off" 1 "Brake On" 2 "Standby Working (Continuous)" 3 "Working Status (Flashing)" 4 "Swing Right" 5 "Swing Left" 6 "Object Sensing (Fast Flashing)" ;
VAL_ 2566866721 CdsFanRvsSt 0 "Off" 1 "On" 2 "Error" 3 "N/A" ;
VAL_ 2566866721 CacFanRvsSt 0 "Off" 1 "On" 2 "Error" 3 "N/A" ;
VAL_ 2566866721 WrnGndSlop 0 "Off" 1 "On" 2 "Error" 3 "N/A" ;
VAL_ 2566866721 WrnOilTmpLw 0 "Off" 1 "On" 2 "Error" 3 "N/A" ;
VAL_ 2566866721 AttOpr 0 "Off" 1 "On" 2 "Error" 3 "N/A" ;
VAL_ 2566866721 WrnLimpHome 0 "Off" 1 "On" 2 "Error" 3 "N/A" ;
VAL_ 2566866721 MchCond 0 "Idle Condition" 1 "Working Condition" 2 "Error" 3 "Standstill Condition" ;
VAL_ 2566866721 WrnRollOvr 0 "Off" 1 "On" 2 "Error" 3 "N/A" ;
VAL_ 2566866721 WrnArmPosOnDrv 0 "Off" 1 "On" 2 "Error" 3 "N/A" ;
VAL_ 2566866721 WrnThmbWhlStrShft 0 "Off" 1 "On" 2 "Error" 3 "N/A" ;
VAL_ 2566866721 WrnRamLck 0 "Off" 1 "On" 2 "Error" 3 "N/A" ;
VAL_ 2566866721 WrnHstOilFilt 0 "Off" 1 "On" 2 "Error" 3 "N/A" ;
VAL_ 2566866721 WrnGrBoxOvTmp 0 "Off" 1 "On" 2 "Error" 3 "N/A" ;
VAL_ 2566866721 VhcStTractionLv 0 "Off" 1 "On" 2 "Error" 3 "N/A" ;
VAL_ 2566866721 WhlLis 0 "Off" 1 "On" 2 "Error" 3 "N/A" ;
VAL_ 2566866721 WhlDzTrlHitch 0 "Off" 1 "On" 2 "Error" 3 "N/A" ;
VAL_ 2566866721 WhlSwgAlign 0 "Off" 1 "On" 2 "Error" 3 "N/A" ;
VAL_ 2566866721 WhlRamLckAuto 0 "Off" 1 "On" 2 "Error" 3 "N/A" ;
